VERSION ""

NS_ :

BS_:

BU_: OpticalSensor EMUS_BMS SCIMO_PE TelemetryNode Master SensorF SensorR BrakeF BrakeR PDU HVCU HVTU TestBench

BO_ 1482 HVCU_SDO_Req_Up: 8 TelemetryNode
 SG_ HVCU_OD_CAN2_DelayedTxMessages m1129 : 16|24@1+ (1,0) [0|16777215] ""  HVCU
 SG_ HVCU_OD_CAN2_ErrorStatus m1128 : 16|8@1+ (1,0) [0|255] ""  HVCU
 SG_ HVCU_OD_CAN2_DiscardedTxMessages m1127 : 16|24@1+ (1,0) [0|16777215] ""  HVCU
 SG_ HVCU_OD_CAN2_Status m1126 : 16|8@1+ (1,0) [0|255] ""  HVCU
 SG_ HVCU_OD_CAN2_Baudrate m1124 : 16|16@1+ (1,0) [125|1000] "kbps"  HVCU
 SG_ HVCU_OD_CAN2_autoErrorReset m1123 : 16|8@1+ (1,0) [0|255] ""  HVCU
 SG_ HVCU_OD_CAN2_lastErrorCode m1122 : 16|32@1+ (1,0) [0|4294967295] ""  HVCU
 SG_ HVCU_OD_CAN2_RxErrCnt m1121 : 16|8@1+ (1,0) [0|255] ""  HVCU
 SG_ HVCU_OD_CAN2_TxErrCnt m1120 : 16|8@1+ (1,0) [0|255] ""  HVCU
 SG_ HVCU_OD_CAN1_DelayedTxMessages m1113 : 16|24@1+ (1,0) [0|16777215] ""  HVCU
 SG_ HVCU_OD_CAN1_ErrorStatus m1112 : 16|8@1+ (1,0) [0|255] ""  HVCU
 SG_ HVCU_OD_CAN1_DiscardedTxMessages m1111 : 16|24@1+ (1,0) [0|16777215] ""  HVCU
 SG_ HVCU_OD_CAN1_Status m1110 : 16|8@1+ (1,0) [0|255] ""  HVCU
 SG_ HVCU_OD_CAN1_Baudrate m1108 : 16|16@1+ (1,0) [125|1000] "kbps"  HVCU
 SG_ HVCU_OD_CAN1_autoErrorReset m1107 : 16|8@1+ (1,0) [0|255] ""  HVCU
 SG_ HVCU_OD_CAN1_lastErrorCode m1106 : 16|32@1+ (1,0) [0|4294967295] ""  HVCU
 SG_ HVCU_OD_CAN1_RxErrCnt m1105 : 16|8@1+ (1,0) [0|255] ""  HVCU
 SG_ HVCU_OD_CAN1_TxErrCnt m1104 : 16|8@1+ (1,0) [0|255] ""  HVCU
 SG_ HVCU_OD_BuildTime m1073 : 16|24@1+ (1,0) [0|16777215] ""  HVCU
 SG_ HVCU_OD_BuildDate m1072 : 16|32@1+ (1,0) [0|4294967295] ""  HVCU
 SG_ HVCU_OD_ChipUID2 m1057 : 16|48@1+ (1,0) [0|281474976710655] ""  HVCU
 SG_ HVCU_OD_ChipUID1 m1056 : 16|48@1+ (1,0) [0|281474976710655] ""  HVCU
 SG_ HVCU_OD_SdcOut m1046 : 16|8@1+ (1,0) [0|255] ""  HVCU
 SG_ HVCU_OD_SdcIn m1045 : 16|8@1+ (1,0) [0|255] ""  HVCU
 SG_ HVCU_OD_runtime m1044 : 16|24@1+ (1,0) [0|16777215] "ms"  HVCU
 SG_ HVCU_OD_InputVoltage m1043 : 16|16@1+ (0.001,0) [0|65.535] "V"  HVCU
 SG_ HVCU_OD_BoardTemp m1042 : 16|16@1+ (0.01,-30) [-30|625.35] "°C"  HVCU
 SG_ HVCU_OD_MemFree m1041 : 16|16@1+ (4,0) [0|262140] "bytes"  HVCU
 SG_ HVCU_OD_CpuUsage m1040 : 16|8@1+ (0.5,0) [0|100] "%"  HVCU
 SG_ HVCU_OD_OdEntrySendInterval m33 : 16|16@1+ (1,0) [0|65535] "ms"  HVCU
 SG_ HVCU_OD_SendOdOnBootup m32 : 16|8@1+ (1,0) [0|255] ""  HVCU
 SG_ HVCU_OD_HeartbeatInterval m16 : 16|16@1+ (1,0) [0|65535] "ms"  HVCU
 SG_ HVCU_OD_DbcVersion m5 : 16|16@1+ (1,0) [0|65535] ""  HVCU
 SG_ HVCU_OD_StackVersion m4 : 16|16@1+ (1,0) [0|65535] ""  HVCU
 SG_ HVCU_OD_ProtocolVersion m3 : 16|16@1+ (1,0) [0|65535] ""  HVCU
 SG_ HVCU_OD_NodeStatus m2 : 16|8@1+ (1,0) [0|255] ""  HVCU
 SG_ HVCU_OD_NodeID m1 : 16|8@1+ (1,0) [0|255] ""  HVCU
 SG_ HVCU_SDO_ID M : 0|12@1+ (1,0) [0|4095] ""  HVCU

BO_ 1546 HVCU_SDO_Req_Down: 2 TelemetryNode
 SG_ HVCU_SDO_ID M : 0|12@1+ (1,0) [0|4095] ""  HVCU

BO_ 1802 HVCU_Heartbeat: 1 HVCU
 SG_ HVCU_NodeState : 0|8@1+ (1,0) [0|0] ""  SensorF,Master,TelemetryNode

BO_ 1866 HVCU_BTL_TX: 8 HVCU

BO_ 1930 HVCU_BTL_RX: 8 TelemetryNode

BO_ 153 HVTU_EMCY: 4 HVTU
 SG_ HVTU_E0_OtherError : 12|1@1+ (1,0) [0|0] ""  Master,TelemetryNode
 SG_ HVTU_W0_OtherWarning : 0|1@1+ (1,0) [0|0] ""  Master,TelemetryNode

BO_ 2684289024 EMUS_Internal_01: 8 EMUS_BMS

BO_ 2684289025 EMUS_Internal_02: 8 EMUS_BMS

BO_ 2684289026 EMUS_Internal_03: 8 EMUS_BMS

BO_ 2684289027 EMUS_Internal_04: 8 EMUS_BMS

BO_ 2684289028 EMUS_Internal_05: 8 EMUS_BMS

BO_ 2684289029 EMUS_Internal_06: 8 EMUS_BMS

BO_ 2684289030 EMUS_Internal_07: 8 EMUS_BMS

BO_ 2684289031 EMUS_Internal_08: 8 EMUS_BMS

BO_ 2684289032 EMUS_Internal_09: 8 EMUS_BMS

BO_ 2684289033 EMUS_Internal_10: 8 EMUS_BMS

BO_ 2684289034 EMUS_Internal_11: 8 EMUS_BMS

BO_ 2684289035 EMUS_Internal_12: 8 EMUS_BMS

BO_ 2684289036 EMUS_Internal_13: 8 EMUS_BMS

BO_ 2684289037 EMUS_Internal_14: 8 EMUS_BMS

BO_ 2684289038 EMUS_Internal_15: 8 EMUS_BMS

BO_ 2684289039 EMUS_Internal_16: 8 EMUS_BMS

BO_ 2684289040 EMUS_Internal_17: 8 EMUS_BMS

BO_ 2684289041 EMUS_Internal_18: 8 EMUS_BMS

BO_ 2684289042 EMUS_Internal_19: 8 EMUS_BMS

BO_ 2684289043 EMUS_Internal_20: 8 EMUS_BMS

BO_ 2684289044 EMUS_Internal_21: 8 EMUS_BMS

BO_ 2684289045 EMUS_Internal_22: 8 EMUS_BMS

BO_ 2684289046 EMUS_Internal_23: 8 EMUS_BMS

BO_ 2684289047 EMUS_Internal_24: 8 EMUS_BMS

BO_ 2684289048 EMUS_Internal_25: 8 EMUS_BMS

BO_ 2684289049 EMUS_Internal_26: 8 EMUS_BMS

BO_ 2684289050 EMUS_Internal_27: 8 EMUS_BMS

BO_ 2684289051 EMUS_Internal_28: 8 EMUS_BMS

BO_ 2684289052 EMUS_Internal_29: 8 EMUS_BMS

BO_ 2684289053 EMUS_Internal_30: 8 EMUS_BMS

BO_ 2684289054 EMUS_Internal_31: 8 EMUS_BMS

BO_ 2684289055 EMUS_Internal_32: 8 EMUS_BMS

BO_ 2684289056 EMUS_Internal_33: 8 EMUS_BMS

BO_ 2684289057 EMUS_Internal_34: 8 EMUS_BMS

BO_ 2684289058 EMUS_Internal_35: 8 EMUS_BMS

BO_ 2684289059 EMUS_Internal_36: 8 EMUS_BMS

BO_ 2684289060 EMUS_Internal_37: 8 EMUS_BMS

BO_ 2684289061 EMUS_Internal_38: 8 EMUS_BMS

BO_ 2684289062 EMUS_Internal_39: 8 EMUS_BMS

BO_ 2684289063 EMUS_Internal_40: 8 EMUS_BMS

BO_ 2684289064 EMUS_Internal_41: 8 EMUS_BMS

BO_ 2684289065 EMUS_Internal_42: 8 EMUS_BMS

BO_ 2684289066 EMUS_Internal_43: 8 EMUS_BMS

BO_ 2684289067 EMUS_Internal_44: 8 EMUS_BMS

BO_ 2684289068 EMUS_Internal_45: 8 EMUS_BMS

BO_ 2684289069 EMUS_Internal_46: 8 EMUS_BMS

BO_ 2684289070 EMUS_Internal_47: 8 EMUS_BMS

BO_ 2684289071 EMUS_Internal_48: 8 EMUS_BMS

BO_ 1509 SCIMO_PE_TX_Electric_MZ_V_FAST: 6 SCIMO_PE
 SG_ SCIMO_V_SET_W_MOT2 : 39|16@0- (0.02,0) [-655.36|655.34] "" Vector__XXX
 SG_ SCIMO_V_SET_V_MOT2 : 23|16@0- (0.02,0) [-655.36|655.34] "" Vector__XXX
 SG_ SCIMO_V_SET_U_MOT2 : 7|16@0- (0.02,0) [-655.36|655.34] "" Vector__XXX

BO_ 1508 SCIMO_PE_TX_Electric_MZ_I_FAST: 6 SCIMO_PE
 SG_ SCIMO_I_MES_W_MOT2 : 39|16@0- (0.02,0) [-655.36|655.34] "" Vector__XXX
 SG_ SCIMO_I_MES_V_MOT2 : 23|16@0- (0.02,0) [-655.36|655.34] "" Vector__XXX
 SG_ SCIMO_I_MES_U_MOT2 : 7|16@0- (0.02,0) [-655.36|655.34] "" Vector__XXX

BO_ 1488 SCIMO_PE_TX_AmbientTemp_MOT2: 8 SensorR
 SG_ SCIMO_Temp_ThermocoupleJ_MOT2 : 55|16@0- (0.005,150) [-13.84|313.835] ""  TestBench
 SG_ SCIMO_Temp_ThermocoupleK_MOT2 : 39|16@0- (0.005,150) [-13.84|313.835] ""  TestBench
 SG_ SCIMO_Temp_ADS_Ambient_MOT2 : 23|16@0- (0.005,150) [-13.84|313.835] ""  TestBench
 SG_ SCIMO_Temp_RotorAmbient_MOT2 : 7|16@0- (0.005,150) [-13.84|313.835] ""  TestBench

BO_ 1472 SCIMO_PE_TX_AmbientTemp_MOT1: 8 SensorR
 SG_ SCIMO_Temp_ThermocoupleJ_MOT1 : 55|16@0- (0.005,150) [-13.84|313.835] ""  TestBench
 SG_ SCIMO_Temp_ThermocoupleK_MOT1 : 39|16@0- (0.005,150) [-13.84|313.835] ""  TestBench
 SG_ SCIMO_Temp_ADS_Ambient_MOT1 : 23|16@0- (0.005,150) [-13.84|313.835] ""  TestBench
 SG_ SCIMO_Temp_RotorAmbient_MOT1 : 7|16@0- (0.005,150) [-13.84|313.835] ""  TestBench

BO_ 1456 SCIMO_MS_RX_RequestData: 2 SensorR
 SG_ SCIMO_NumOfSamples : 7|16@0+ (1,0) [0|65535] ""  TestBench

BO_ 1440 SCIMO_MS_TX_Electric: 8 SCIMO_PE
 SG_ SCIMO_U_Q_MOT : 55|16@0- (0.025,0) [-819.2|819.175] ""  TestBench
 SG_ SCIMO_U_D_MOT : 39|16@0- (0.025,0) [-819.2|819.175] ""  TestBench
 SG_ SCIMO_I_Q_MOT : 23|16@0- (0.025,0) [-819.2|819.175] ""  TestBench
 SG_ SCIMO_I_D_MOT : 7|16@0- (0.025,0) [-819.2|819.175] ""  TestBench

BO_ 1344 SCIMO_PE_TX_MotorTemp_MOT2: 6 SensorR
 SG_ SCIMO_Temp_PT100B_MOT2 : 39|16@0- (0.005,150) [-13.84|313.835] ""  TestBench
 SG_ SCIMO_Temp_PT100A_MOT2 : 23|16@0- (0.005,150) [-13.84|313.835] ""  TestBench
 SG_ SCIMO_Temp_Rotor_MOT2 : 7|16@0- (0.005,150) [-13.84|313.835] ""  TestBench

BO_ 1328 SCIMO_PE_TX_MotorTemp_MOT1: 6 SensorR
 SG_ SCIMO_Temp_PT100B_MOT1 : 39|16@0- (0.005,150) [-13.84|313.835] ""  TestBench
 SG_ SCIMO_Temp_PT100A_MOT1 : 23|16@0- (0.005,150) [-13.84|313.835] ""  TestBench
 SG_ SCIMO_Temp_Rotor_MOT1 : 7|16@0- (0.005,150) [-13.84|313.835] ""  TestBench

BO_ 1520 SCIMO_PE_TX_Status: 6 SCIMO_PE
 SG_ SCIMO_tempCPU : 47|8@0+ (0.5,0) [0|127.5] ""  TestBench,SensorR
 SG_ SCIMO_VCC_LV : 39|8@0+ (0.25,6) [6|69.75] ""  TestBench,SensorR
 SG_ SCIMO_I_LV : 31|8@0+ (0.01,0) [0|2.55] ""  TestBench,SensorR
 SG_ SCIMO_tempAUX2 : 23|8@0+ (1,0) [0|255] ""  TestBench,SensorR
 SG_ SCIMO_tempAUX1 : 15|8@0+ (1,0) [0|255] ""  TestBench,SensorR
 SG_ SCIMO_tempPCB : 7|8@0+ (1,0) [0|255] ""  TestBench,SensorR

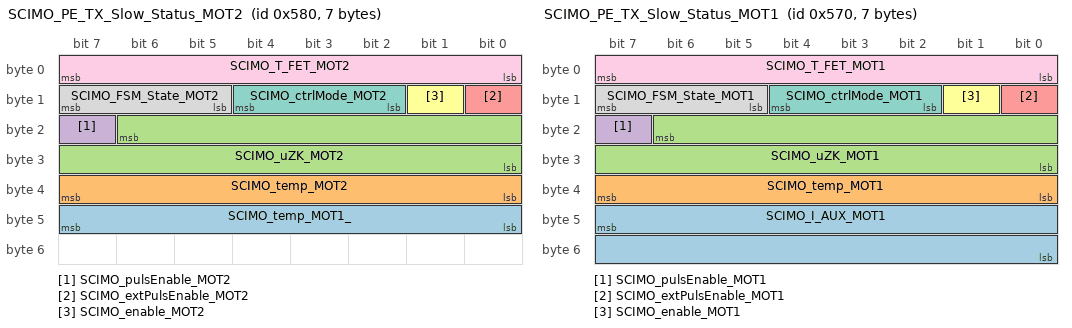
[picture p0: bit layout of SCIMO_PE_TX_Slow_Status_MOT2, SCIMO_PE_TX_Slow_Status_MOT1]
BO_ 1408 SCIMO_PE_TX_Slow_Status_MOT2: 7 SCIMO_PE
 SG_ SCIMO_temp_MOT1_ : 47|8@0+ (1,0) [0|0] ""  TestBench,SensorR
 SG_ SCIMO_temp_MOT2 : 39|8@0+ (1,0) [0|0] ""  TestBench,SensorR
 SG_ SCIMO_uZK_MOT2 : 22|15@0- (0.1,0) [0|0] ""  TestBench,SensorR
 SG_ SCIMO_pulsEnable_MOT2 : 23|1@0+ (1,0) [0|0] ""  TestBench,SensorR
 SG_ SCIMO_extPulsEnable_MOT2 : 8|1@0+ (1,0) [0|0] ""  TestBench,SensorR
 SG_ SCIMO_enable_MOT2 : 9|1@0+ (1,0) [0|0] ""  TestBench,SensorR
 SG_ SCIMO_ctrlMode_MOT2 : 12|3@0+ (1,0) [0|0] ""  TestBench,SensorR
 SG_ SCIMO_FSM_State_MOT2 : 15|3@0+ (1,0) [0|0] ""  TestBench,SensorR
 SG_ SCIMO_T_FET_MOT2 : 7|8@0+ (1,0) [0|0] ""  TestBench,SensorR

BO_ 1392 SCIMO_PE_TX_Slow_Status_MOT1: 7 SCIMO_PE
 SG_ SCIMO_I_AUX_MOT1 : 47|16@0- (1,0) [-32768|32767] ""  TestBench
 SG_ SCIMO_temp_MOT1 : 39|8@0+ (1,0) [0|0] ""  TestBench,SensorR
 SG_ SCIMO_uZK_MOT1 : 22|15@0- (0.1,0) [0|0] ""  TestBench,SensorR
 SG_ SCIMO_pulsEnable_MOT1 : 23|1@0+ (1,0) [0|0] ""  TestBench,SensorR
 SG_ SCIMO_extPulsEnable_MOT1 : 8|1@0+ (1,0) [0|0] ""  TestBench,SensorR
 SG_ SCIMO_enable_MOT1 : 9|1@0+ (1,0) [0|0] ""  TestBench,SensorR
 SG_ SCIMO_ctrlMode_MOT1 : 12|3@0+ (1,0) [0|0] ""  TestBench,SensorR
 SG_ SCIMO_FSM_State_MOT1 : 15|3@0+ (1,0) [0|0] ""  TestBench,SensorR
 SG_ SCIMO_T_FET_MOT1 : 7|8@0+ (1,0) [0|0] ""  TestBench,SensorR

BO_ 1504 SCIMO_PE_TX_Electric: 8 SCIMO_PE
 SG_ I_Q_MOT2 : 55|16@0- (1,0) [0|0] ""  TestBench,SensorR
 SG_ I_D_MOT2 : 39|16@0- (1,0) [0|0] ""  TestBench,SensorR
 SG_ I_Q_MOT1 : 23|16@0- (1,0) [0|0] ""  TestBench,SensorR
 SG_ I_D_MOT1 : 7|16@0- (1,0) [0|0] ""  TestBench,SensorR

BO_ 1510 SCIMO_PE_TX_MZ_Electric: 8 SCIMO_PE
 SG_ SCIMO_I_Q_MOT2 : 55|16@0- (0.05,0) [-1638.4|1638.35] ""  TestBench,SensorR
 SG_ SCIMO_I_D_MOT2 : 39|16@0- (0.05,0) [-1638.4|1638.35] ""  TestBench,SensorR
 SG_ SCIMO_f_REQ_LOWPASS_MOT2 : 23|13@0+ (0.05,0) [0|409.55] ""  TestBench,SensorR
 SG_ SCIMO_I_REQ_LOWPASS_MOT2 : 7|13@0+ (0.05,0) [0|409.55] ""  TestBench,SensorR

BO_ 1312 SCIMO_PE_TX_Errors: 5 SCIMO_PE
 SG_ SCIMO_warnNum_MOT2 : 25|10@0+ (1,0) [0|0] ""  TestBench,SensorR
 SG_ SCIMO_warnNum_MOT1 : 19|10@0+ (1,0) [0|1023] ""  TestBench,SensorR
 SG_ SCIMO_errNum_MOT2 : 15|8@0+ (1,0) [0|0] ""  TestBench,SensorR
 SG_ SCIMO_errNum_MOT1 : 7|8@0+ (1,0) [0|0] ""  TestBench,SensorR

BO_ 1360 SCIMO_PE_TX_Mech_fast: 8 SCIMO_PE
 SG_ SCIMO_M_ist_gw_MOT2 : 55|16@0- (1,0) [0|0] ""  TestBench,SensorR
 SG_ SCIMO_n_gw_MOT2 : 39|16@0- (1,0) [0|0] ""  TestBench,SensorR
 SG_ SCIMO_M_ist_gw_MOT1 : 23|16@0- (1,0) [0|0] ""  TestBench,SensorR
 SG_ SCIMO_n_gw_MOT1 : 7|16@0- (1,0) [0|0] ""  TestBench,SensorR

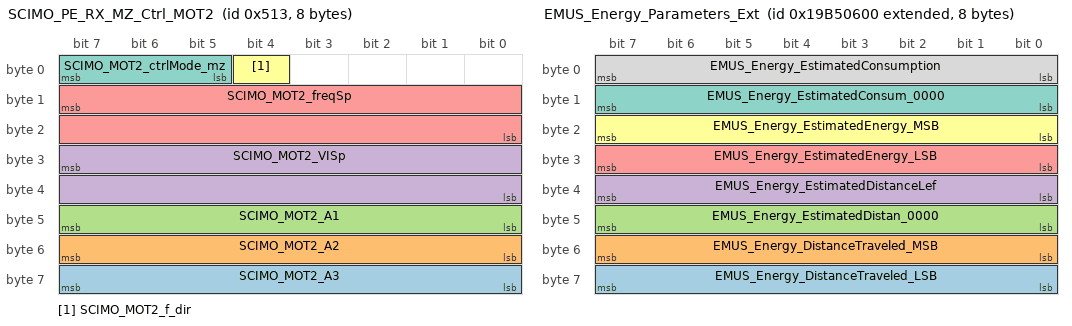
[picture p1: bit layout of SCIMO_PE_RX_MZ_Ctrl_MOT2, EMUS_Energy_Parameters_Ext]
BO_ 1299 SCIMO_PE_RX_MZ_Ctrl_MOT2: 8 SensorR
 SG_ SCIMO_MOT2_A3 : 56|8@1+ (0.01,0) [0|2.55] ""  SCIMO_PE
 SG_ SCIMO_MOT2_A2 : 48|8@1+ (0.01,0) [0|2.55] ""  SCIMO_PE
 SG_ SCIMO_MOT2_A1 : 40|8@1+ (0.01,0) [0|2.55] ""  SCIMO_PE
 SG_ SCIMO_MOT2_VISp : 31|16@0+ (0.01,0) [0|655.35] ""  TestBench,SCIMO_PE
 SG_ SCIMO_MOT2_freqSp : 15|16@0+ (0.02,0) [0|1310.7] ""  TestBench,SCIMO_PE
 SG_ SCIMO_MOT2_f_dir : 4|1@0+ (1,0) [0|0] ""  SCIMO_PE
 SG_ SCIMO_MOT2_ctrlMode_mz : 7|3@0+ (1,0) [0|0] ""  TestBench,SCIMO_PE

BO_ 1280 SCIMO_PE_RX_Ctrl_MOT1: 5 SensorR
 SG_ SCIMO_MOT1_limitSp : 31|16@0- (1,0) [0|0] ""  TestBench,SCIMO_PE
 SG_ SCIMO_MOT1_targetSp : 15|16@0- (1,0) [0|0] ""  TestBench,SCIMO_PE
 SG_ SCIMO_MOT1_reset : 3|1@0+ (1,0) [0|0] ""  TestBench,SCIMO_PE
 SG_ SCIMO_MOT1_ctrlMode : 6|3@0+ (1,0) [0|0] ""  TestBench,SCIMO_PE
 SG_ SCIMO_MOT1_enable : 7|1@0+ (1,0) [0|0] ""  TestBench,SCIMO_PE

BO_ 1296 SCIMO_PE_RX_Ctrl_MOT2: 5 SensorR
 SG_ SCIMO_MOT2_limitSp : 31|16@0- (1,0) [0|0] ""  TestBench,SCIMO_PE
 SG_ SCIMO_MOT2_targetSp : 15|16@0- (1,0) [0|0] ""  TestBench,SCIMO_PE
 SG_ SCIMO_MOT2_reset : 3|1@0+ (1,0) [0|0] ""  TestBench,SCIMO_PE
 SG_ SCIMO_MOT2_ctrlMode : 6|3@0+ (1,0) [0|0] ""  TestBench,SCIMO_PE
 SG_ SCIMO_MOT2_enable : 7|1@0+ (1,0) [0|0] ""  TestBench,SCIMO_PE

BO_ 2578776065 EMUS_Battery_Volt_Overall_Param_: 8 EMUS_BMS
 SG_ EMUS_VoltOverallParams_TVoltThir : 48|8@1+ (1,0) [0|255] ""  HVCU,HVTU
 SG_ EMUS_VoltOverallParams_TVoltMSB : 40|8@1+ (1,0) [0|255] ""  HVCU,HVTU
 SG_ EMUS_VoltOverallParams_TVoltLSB : 32|8@1+ (1,0) [0|255] ""  HVCU,HVTU
 SG_ EMUS_VoltOverallParams_TVoltSecB : 24|8@1+ (1,0) [0|255] ""  HVCU,HVTU
 SG_ EMUS_VoltOverallParam_AvrgCellVo : 16|8@1+ (0.01,2) [2|4.55] "V"  HVCU,HVTU
 SG_ EMUS_VoltOverallParam_MaxCellVol : 8|8@1+ (0.01,2) [2|4.55] "V"  HVCU,HVTU
 SG_ EMUS_VoltOverallParam_MinCellVol : 0|8@1+ (0.01,2) [2|4.55] "V"  HVCU,HVTU

BO_ 2578776064 EMUS_Overall_Parameters_Ext: 8 EMUS_BMS
 SG_ EMUS_OverallParams_NumberOf_0000 : 56|8@1+ (1,0) [0|255] ""  HVCU
 SG_ EMUS_OverallParams_LastChargingE : 48|8@1+ (1,0) [0|255] ""  HVCU
 SG_ EMUS_OverallParams_ChrgStag_0000 : 40|8@1+ (1,0) [0|255] ""  HVCU
 SG_ EMUS_OverallParams_ChrgStageDura : 32|8@1+ (1,0) [0|255] ""  HVCU
 SG_ EMUS_OverallParams_ChargingStage : 24|8@1+ (1,0) [0|255] ""  HVCU
 SG_ EMUS_OverallParams_NumberOfCells : 16|8@1+ (1,0) [0|255] ""  HVCU
 SG_ EMUS_OverallParams_ContactorPreC : 15|1@1+ (1,0) [0|1] ""  HVCU
 SG_ EMUS_OverallParams_DCDC_Control : 14|1@1+ (1,0) [0|1] ""  HVCU
 SG_ EMUS_OverallParams_ChargingInter : 13|1@1+ (1,0) [0|1] ""  HVCU
 SG_ EMUS_OverallParams_PowerReductio : 12|1@1+ (1,0) [0|1] ""  HVCU
 SG_ EMUS_OverallParams_BatteryFan : 11|1@1+ (1,0) [0|1] ""  HVCU
 SG_ EMUS_OverallParams_BatteryContac : 10|1@1+ (1,0) [0|1] ""  HVCU
 SG_ EMUS_OverallParams_HeaterEnable : 9|1@1+ (1,0) [0|1] ""  HVCU
 SG_ EMUS_OverallParams_ChargerEnable : 8|1@1+ (1,0) [0|1] ""  HVCU
 SG_ EMUS_OverallParams_LeakageSensor : 3|1@1+ (1,0) [0|1] ""  HVCU
 SG_ EMUS_OverallParams_FastCharge : 2|1@1+ (1,0) [0|1] ""  HVCU
 SG_ EMUS_OverallParams_ChargerMains : 1|1@1+ (1,0) [0|1] ""  HVCU
 SG_ EMUS_OverallParams_IgnitionKey : 0|1@1+ (1,0) [0|1] ""  HVCU

BO_ 2578776071 EMUS_Diagnostic_Codes_Ext: 8 EMUS_BMS
 SG_ EMUS_DiagnosticCodes_CellTempVal : 29|1@1+ (1,0) [0|1] ""  HVCU,HVTU
 SG_ EMUS_DiagnosticCodes_BatChrgFini : 28|1@1+ (1,0) [0|1] ""  HVCU,HVTU
 SG_ EMUS_DiagnosticCodes_NumOfCellsV : 27|1@1+ (1,0) [0|1] ""  HVCU,HVTU
 SG_ EMUS_DiagnosticCodes_CellBalancV : 26|1@1+ (1,0) [0|1] ""  HVCU,HVTU
 SG_ EMUS_DiagnosticCodes_CellModTemp : 25|1@1+ (1,0) [0|1] ""  HVCU,HVTU
 SG_ EMUS_DiagnosticCodes_CellVoltVal : 24|1@1+ (1,0) [0|1] ""  HVCU,HVTU
 SG_ EMUS_DiagnosticCodes_PackUnderVo : 21|1@1+ (1,0) [0|1] ""  HVCU,HVTU
 SG_ EMUS_DiagnosticCodes_NoCurrentSe : 20|1@1+ (1,0) [0|1] ""  HVCU,HVTU
 SG_ EMUS_DiagnosticCodes_CellOverHea : 19|1@1+ (1,0) [0|1] ""  HVCU,HVTU
 SG_ EMUS_DiagnosticCodes_HighTempera : 10|1@1+ (1,0) [0|1] ""  HVCU,HVTU
 SG_ EMUS_DiagnosticCodes_HighCurrent : 9|1@1+ (1,0) [0|1] ""  HVCU,HVTU
 SG_ EMUS_DiagnosticCodes_LowVoltage : 8|1@1+ (1,0) [0|1] ""  HVCU,HVTU
 SG_ EMUS_DiagnosticCodes_NoCellComm : 6|1@1+ (1,0) [0|1] ""  HVCU,HVTU
 SG_ EMUS_DiagnosticCodes_Leakage : 5|1@1+ (1,0) [0|1] ""  HVCU,HVTU
 SG_ EMUS_DiagnosticCodes_CellModOver : 4|1@1+ (1,0) [0|1] ""  HVCU,HVTU
 SG_ EMUS_DiagnosticCodes_ChrgOverCur : 3|1@1+ (1,0) [0|1] ""  HVCU,HVTU
 SG_ EMUS_DiagnosticCodes_DchrgOvrCur : 2|1@1+ (1,0) [0|1] ""  HVCU,HVTU
 SG_ EMUS_DiagnosticCodes_OverVoltage : 1|1@1+ (1,0) [0|1] ""  HVCU,HVTU
 SG_ EMUS_DiagnosticCodes_UnderVoltag : 0|1@1+ (1,0) [0|1] ""  HVCU,HVTU

BO_ 2578776066 EMUS_Cell_Mod_Temp_Overall_Param: 8 EMUS_BMS
 SG_ EMUS_CellModOverallPar_AvgCellMo : 16|8@1+ (1,-100) [-100|155] "Â°C"  HVTU
 SG_ EMUS_CellModOverallPar_MaxCellMo : 8|8@1+ (1,-100) [-100|155] "Â°C"  HVTU
 SG_ EMUS_CellModOverallPar_MinCellMo : 0|8@1+ (1,-100) [-100|155] "Â°C"  HVTU

BO_ 2578776072 EMUS_Cell_Temp_Overall_Params_Ex: 8 EMUS_BMS
 SG_ EMUS_CellOverallPar_AvgCellTemp : 16|8@1+ (1,-100) [-100|155] "Â°C"  HVTU
 SG_ EMUS_CellOverallPar_MaxCellTemp : 8|8@1+ (1,-100) [-100|155] "Â°C"  HVTU
 SG_ EMUS_CellOverallPar_MinCellTemp : 0|8@1+ (1,-100) [-100|155] "Â°C"  HVTU

BO_ 2578776067 EMUS_Cell_Balanc_Rate_Overall_Pa: 8 EMUS_BMS
 SG_ EMUS_CellBalancPar_AvgCellBalanc : 16|8@1+ (0.392156862745098,0) [0|100] "%"  HVTU
 SG_ EMUS_CellBalancPar_MaxCellBalanc : 8|8@1+ (0.392156862745098,0) [0|100] "%"  HVTU
 SG_ EMUS_CellBalancPar_MinCellBalanc : 0|8@1+ (0.392156862745098,0) [0|100] "%"  HVTU

BO_ 2578777088 EMUS_Configuration_Parameters_Ex: 8 EMUS_BMS
 SG_ EMUS_ConfigParams_Parameter_0000 : 48|8@1+ (1,0) [0|255] "" Vector__XXX
 SG_ EMUS_ConfigParams_ParamData_SecB : 40|8@1+ (1,0) [0|255] "" Vector__XXX
 SG_ EMUS_ConfigParams_ParamData_Thir : 32|8@1+ (1,0) [0|255] "" Vector__XXX
 SG_ EMUS_ConfigParams_ParameterData_ : 24|8@1+ (1,0) [0|255] "" Vector__XXX
 SG_ EMUS_ConfigParams_ParameterSize : 16|8@1+ (1,0) [0|255] "" Vector__XXX
 SG_ EMUS_ConfigParams_ParameterID_LS : 8|8@1+ (1,0) [0|255] "" Vector__XXX
 SG_ EMUS_ConfigParams_ParameterID_MS : 0|8@1+ (1,0) [0|255] "" Vector__XXX

BO_ 2578777090 EMUS_Login_Level_Ext: 8 EMUS_BMS
 SG_ EMUS_LoginLevel : 0|8@1+ (1,0) [0|255] "" Vector__XXX

BO_ 2578777089 EMUS_Contactor_Control_Ext: 1 HVCU
 SG_ EMUS_ContactorControl_ContactorS : 0|8@1+ (1,0) [0|255] ""  HVTU,EMUS_BMS

BO_ 2578777600 EMUS_Energy_Parameters_Ext: 8 EMUS_BMS
 SG_ EMUS_Energy_DistanceTraveled_LSB : 56|8@1+ (1,0) [0|255] "" Vector__XXX
 SG_ EMUS_Energy_DistanceTraveled_MSB : 48|8@1+ (1,0) [0|255] "" Vector__XXX
 SG_ EMUS_Energy_EstimatedDistan_0000 : 40|8@1+ (1,0) [0|255] "" Vector__XXX
 SG_ EMUS_Energy_EstimatedDistanceLef : 32|8@1+ (1,0) [0|255] "" Vector__XXX
 SG_ EMUS_Energy_EstimatedEnergy_LSB : 24|8@1+ (1,0) [0|255] "" Vector__XXX
 SG_ EMUS_Energy_EstimatedEnergy_MSB : 16|8@1+ (1,0) [0|255] "" Vector__XXX
 SG_ EMUS_Energy_EstimatedConsum_0000 : 8|8@1+ (1,0) [0|255] "" Vector__XXX
 SG_ EMUS_Energy_EstimatedConsumption : 0|8@1+ (1,0) [0|255] "" Vector__XXX

BO_ 2578777344 EMUS_State_Of_Charge_Param_Ext: 8 EMUS_BMS
 SG_ EMUS_SOCParams_EstimatedSOC : 48|8@1+ (1,0) [0|255] ""  HVTU
 SG_ EMUS_SOCParams_EstimatedCharge_L : 24|8@1+ (1,0) [0|255] ""  HVTU
 SG_ EMUS_SOCParams_EstimatedCharge_M : 16|8@1+ (1,0) [0|255] ""  HVTU
 SG_ EMUS_SOCParams_Current_LSB : 8|8@1+ (1,0) [0|255] ""  HVTU
 SG_ EMUS_SOCParams_Current_MSB : 0|8@1+ (1,0) [0|255] ""  HVTU

BO_ 2578777092 EMUS_Statistics_Ext: 8 EMUS_BMS
 SG_ EMUS_Statistics_Data_LSB : 40|8@1+ (1,0) [0|255] "" Vector__XXX
 SG_ EMUS_Statistics_Data_SecondByte : 32|8@1+ (1,0) [0|255] "" Vector__XXX
 SG_ EMUS_Statistics_Data_ThirdByte : 24|8@1+ (1,0) [0|255] "" Vector__XXX
 SG_ EMUS_Statistics_Data_MSB : 16|8@1+ (1,0) [0|255] "" Vector__XXX
 SG_ EMUS_Statistics_DataType : 8|8@1+ (1,0) [0|255] "" Vector__XXX
 SG_ EMUS_Statistics_Identifier : 0|8@1+ (1,0) [0|255] "" Vector__XXX

BO_ 2578777093 EMUS_Events_Ext: 8 EMUS_BMS
 SG_ EMUS_Events_Data_LSB : 40|8@1+ (1,0) [0|255] "" Vector__XXX
 SG_ EMUS_Events_Data_SecondByte : 32|8@1+ (1,0) [0|255] "" Vector__XXX
 SG_ EMUS_Events_Data_ThirdByte : 24|8@1+ (1,0) [0|255] "" Vector__XXX
 SG_ EMUS_Events_Data_MSB : 16|8@1+ (1,0) [0|255] "" Vector__XXX
 SG_ EMUS_Events_DataType : 8|8@1+ (1,0) [0|255] "" Vector__XXX
 SG_ EMUS_Events_EntryNumber : 0|8@1+ (1,0) [0|255] "" Vector__XXX

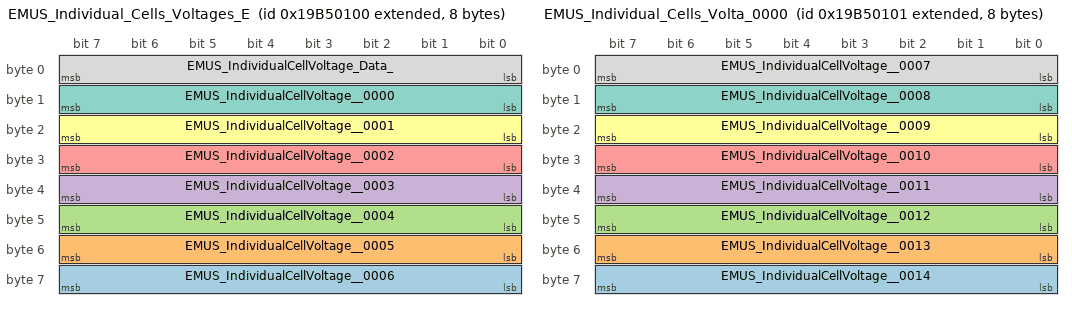
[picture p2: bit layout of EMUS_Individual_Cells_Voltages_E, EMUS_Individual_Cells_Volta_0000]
BO_ 2578776320 EMUS_Individual_Cells_Voltages_E: 8 EMUS_BMS
 SG_ EMUS_IndividualCellVoltage__0006 : 56|8@1+ (0.01,2) [2|4.55] "V" Vector__XXX
 SG_ EMUS_IndividualCellVoltage__0005 : 48|8@1+ (0.01,2) [2|4.55] "V" Vector__XXX
 SG_ EMUS_IndividualCellVoltage__0004 : 40|8@1+ (0.01,2) [2|4.55] "V" Vector__XXX
 SG_ EMUS_IndividualCellVoltage__0003 : 32|8@1+ (0.01,2) [2|4.55] "V" Vector__XXX
 SG_ EMUS_IndividualCellVoltage__0002 : 24|8@1+ (0.01,2) [2|4.55] "V" Vector__XXX
 SG_ EMUS_IndividualCellVoltage__0001 : 16|8@1+ (0.01,2) [2|4.55] "V" Vector__XXX
 SG_ EMUS_IndividualCellVoltage__0000 : 8|8@1+ (0.01,2) [2|4.55] "V" Vector__XXX
 SG_ EMUS_IndividualCellVoltage_Data_ : 0|8@1+ (0.01,2) [2|4.55] "V" Vector__XXX

BO_ 2578776321 EMUS_Individual_Cells_Volta_0000: 8 EMUS_BMS
 SG_ EMUS_IndividualCellVoltage__0014 : 56|8@1+ (0.01,2) [2|4.55] "V" Vector__XXX
 SG_ EMUS_IndividualCellVoltage__0013 : 48|8@1+ (0.01,2) [2|4.55] "V" Vector__XXX
 SG_ EMUS_IndividualCellVoltage__0012 : 40|8@1+ (0.01,2) [2|4.55] "V" Vector__XXX
 SG_ EMUS_IndividualCellVoltage__0011 : 32|8@1+ (0.01,2) [2|4.55] "V" Vector__XXX
 SG_ EMUS_IndividualCellVoltage__0010 : 24|8@1+ (0.01,2) [2|4.55] "V" Vector__XXX
 SG_ EMUS_IndividualCellVoltage__0009 : 16|8@1+ (0.01,2) [2|4.55] "V" Vector__XXX
 SG_ EMUS_IndividualCellVoltage__0008 : 8|8@1+ (0.01,2) [2|4.55] "V" Vector__XXX
 SG_ EMUS_IndividualCellVoltage__0007 : 0|8@1+ (0.01,2) [2|4.55] "V" Vector__XXX

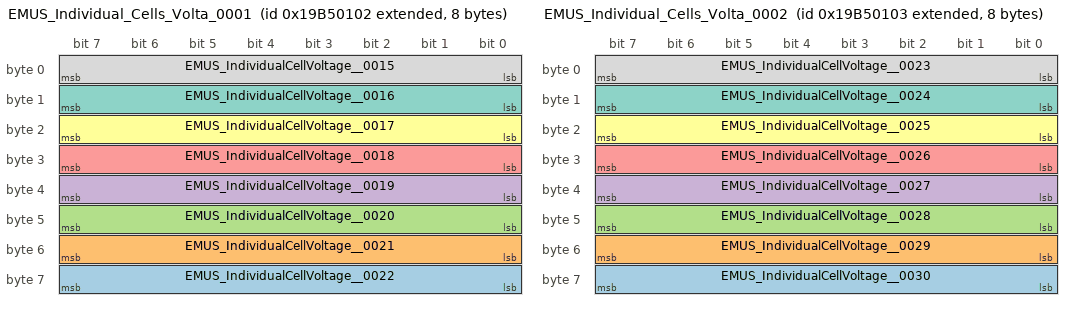
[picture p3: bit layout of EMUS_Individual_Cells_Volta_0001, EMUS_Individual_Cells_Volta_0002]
BO_ 2578776322 EMUS_Individual_Cells_Volta_0001: 8 EMUS_BMS
 SG_ EMUS_IndividualCellVoltage__0022 : 56|8@1+ (0.01,2) [2|4.55] "V" Vector__XXX
 SG_ EMUS_IndividualCellVoltage__0021 : 48|8@1+ (0.01,2) [2|4.55] "V" Vector__XXX
 SG_ EMUS_IndividualCellVoltage__0020 : 40|8@1+ (0.01,2) [2|4.55] "V" Vector__XXX
 SG_ EMUS_IndividualCellVoltage__0019 : 32|8@1+ (0.01,2) [2|4.55] "V" Vector__XXX
 SG_ EMUS_IndividualCellVoltage__0018 : 24|8@1+ (0.01,2) [2|4.55] "V" Vector__XXX
 SG_ EMUS_IndividualCellVoltage__0017 : 16|8@1+ (0.01,2) [2|4.55] "V" Vector__XXX
 SG_ EMUS_IndividualCellVoltage__0016 : 8|8@1+ (0.01,2) [2|4.55] "V" Vector__XXX
 SG_ EMUS_IndividualCellVoltage__0015 : 0|8@1+ (0.01,2) [2|4.55] "V" Vector__XXX

BO_ 2578776323 EMUS_Individual_Cells_Volta_0002: 8 EMUS_BMS
 SG_ EMUS_IndividualCellVoltage__0030 : 56|8@1+ (0.01,2) [2|4.55] "V" Vector__XXX
 SG_ EMUS_IndividualCellVoltage__0029 : 48|8@1+ (0.01,2) [2|4.55] "V" Vector__XXX
 SG_ EMUS_IndividualCellVoltage__0028 : 40|8@1+ (0.01,2) [2|4.55] "V" Vector__XXX
 SG_ EMUS_IndividualCellVoltage__0027 : 32|8@1+ (0.01,2) [2|4.55] "V" Vector__XXX
 SG_ EMUS_IndividualCellVoltage__0026 : 24|8@1+ (0.01,2) [2|4.55] "V" Vector__XXX
 SG_ EMUS_IndividualCellVoltage__0025 : 16|8@1+ (0.01,2) [2|4.55] "V" Vector__XXX
 SG_ EMUS_IndividualCellVoltage__0024 : 8|8@1+ (0.01,2) [2|4.55] "V" Vector__XXX
 SG_ EMUS_IndividualCellVoltage__0023 : 0|8@1+ (0.01,2) [2|4.55] "V" Vector__XXX

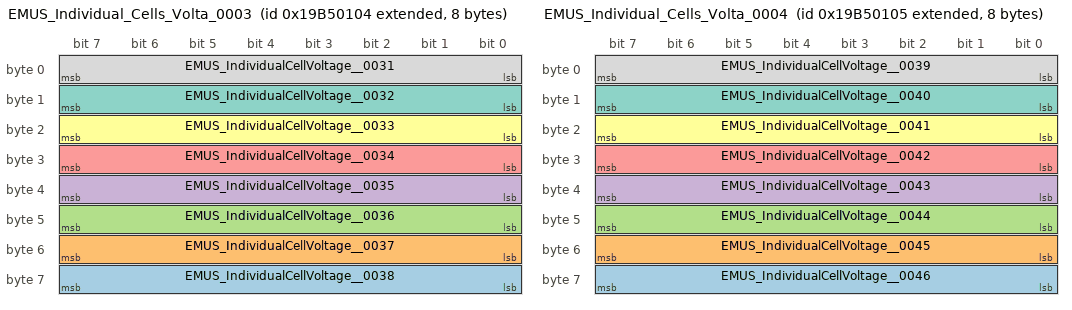
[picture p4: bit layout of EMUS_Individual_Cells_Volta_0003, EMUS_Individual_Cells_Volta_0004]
BO_ 2578776324 EMUS_Individual_Cells_Volta_0003: 8 EMUS_BMS
 SG_ EMUS_IndividualCellVoltage__0038 : 56|8@1+ (0.01,2) [2|4.55] "V" Vector__XXX
 SG_ EMUS_IndividualCellVoltage__0037 : 48|8@1+ (0.01,2) [2|4.55] "V" Vector__XXX
 SG_ EMUS_IndividualCellVoltage__0036 : 40|8@1+ (0.01,2) [2|4.55] "V" Vector__XXX
 SG_ EMUS_IndividualCellVoltage__0035 : 32|8@1+ (0.01,2) [2|4.55] "V" Vector__XXX
 SG_ EMUS_IndividualCellVoltage__0034 : 24|8@1+ (0.01,2) [2|4.55] "V" Vector__XXX
 SG_ EMUS_IndividualCellVoltage__0033 : 16|8@1+ (0.01,2) [2|4.55] "V" Vector__XXX
 SG_ EMUS_IndividualCellVoltage__0032 : 8|8@1+ (0.01,2) [2|4.55] "V" Vector__XXX
 SG_ EMUS_IndividualCellVoltage__0031 : 0|8@1+ (0.01,2) [2|4.55] "V" Vector__XXX

BO_ 2578776325 EMUS_Individual_Cells_Volta_0004: 8 EMUS_BMS
 SG_ EMUS_IndividualCellVoltage__0046 : 56|8@1+ (0.01,2) [2|4.55] "V" Vector__XXX
 SG_ EMUS_IndividualCellVoltage__0045 : 48|8@1+ (0.01,2) [2|4.55] "V" Vector__XXX
 SG_ EMUS_IndividualCellVoltage__0044 : 40|8@1+ (0.01,2) [2|4.55] "V" Vector__XXX
 SG_ EMUS_IndividualCellVoltage__0043 : 32|8@1+ (0.01,2) [2|4.55] "V" Vector__XXX
 SG_ EMUS_IndividualCellVoltage__0042 : 24|8@1+ (0.01,2) [2|4.55] "V" Vector__XXX
 SG_ EMUS_IndividualCellVoltage__0041 : 16|8@1+ (0.01,2) [2|4.55] "V" Vector__XXX
 SG_ EMUS_IndividualCellVoltage__0040 : 8|8@1+ (0.01,2) [2|4.55] "V" Vector__XXX
 SG_ EMUS_IndividualCellVoltage__0039 : 0|8@1+ (0.01,2) [2|4.55] "V" Vector__XXX

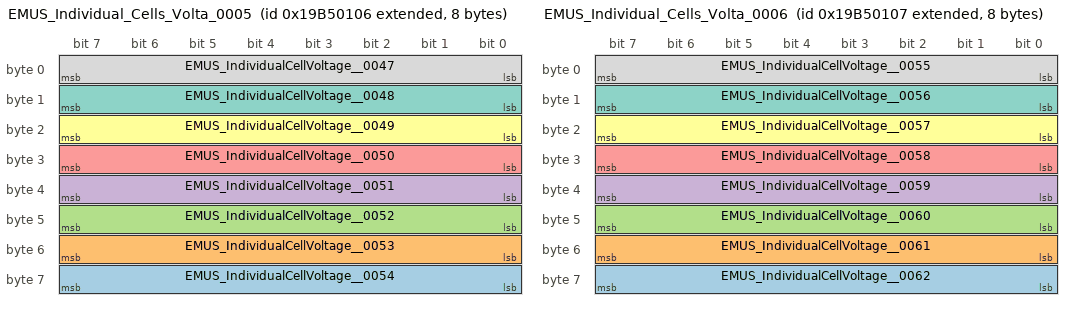
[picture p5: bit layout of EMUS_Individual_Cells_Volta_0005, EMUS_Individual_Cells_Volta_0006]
BO_ 2578776326 EMUS_Individual_Cells_Volta_0005: 8 EMUS_BMS
 SG_ EMUS_IndividualCellVoltage__0054 : 56|8@1+ (0.01,2) [2|4.55] "V" Vector__XXX
 SG_ EMUS_IndividualCellVoltage__0053 : 48|8@1+ (0.01,2) [2|4.55] "V" Vector__XXX
 SG_ EMUS_IndividualCellVoltage__0052 : 40|8@1+ (0.01,2) [2|4.55] "V" Vector__XXX
 SG_ EMUS_IndividualCellVoltage__0051 : 32|8@1+ (0.01,2) [2|4.55] "V" Vector__XXX
 SG_ EMUS_IndividualCellVoltage__0050 : 24|8@1+ (0.01,2) [2|4.55] "V" Vector__XXX
 SG_ EMUS_IndividualCellVoltage__0049 : 16|8@1+ (0.01,2) [2|4.55] "V" Vector__XXX
 SG_ EMUS_IndividualCellVoltage__0048 : 8|8@1+ (0.01,2) [2|4.55] "V" Vector__XXX
 SG_ EMUS_IndividualCellVoltage__0047 : 0|8@1+ (0.01,2) [2|4.55] "V" Vector__XXX

BO_ 2578776327 EMUS_Individual_Cells_Volta_0006: 8 EMUS_BMS
 SG_ EMUS_IndividualCellVoltage__0062 : 56|8@1+ (0.01,2) [2|4.55] "V" Vector__XXX
 SG_ EMUS_IndividualCellVoltage__0061 : 48|8@1+ (0.01,2) [2|4.55] "V" Vector__XXX
 SG_ EMUS_IndividualCellVoltage__0060 : 40|8@1+ (0.01,2) [2|4.55] "V" Vector__XXX
 SG_ EMUS_IndividualCellVoltage__0059 : 32|8@1+ (0.01,2) [2|4.55] "V" Vector__XXX
 SG_ EMUS_IndividualCellVoltage__0058 : 24|8@1+ (0.01,2) [2|4.55] "V" Vector__XXX
 SG_ EMUS_IndividualCellVoltage__0057 : 16|8@1+ (0.01,2) [2|4.55] "V" Vector__XXX
 SG_ EMUS_IndividualCellVoltage__0056 : 8|8@1+ (0.01,2) [2|4.55] "V" Vector__XXX
 SG_ EMUS_IndividualCellVoltage__0055 : 0|8@1+ (0.01,2) [2|4.55] "V" Vector__XXX

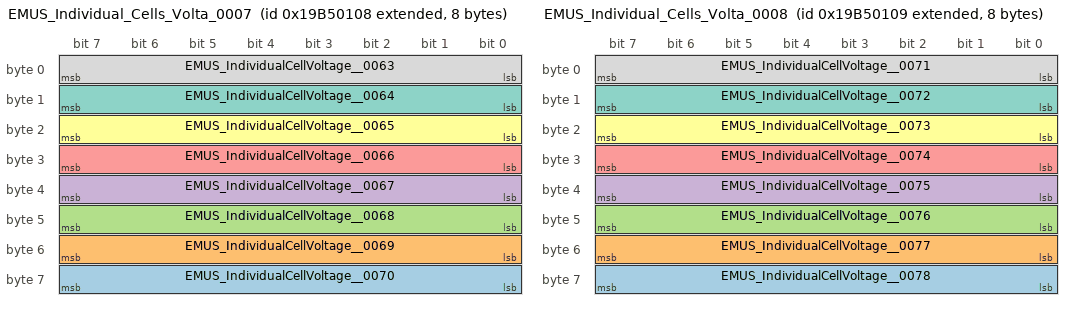
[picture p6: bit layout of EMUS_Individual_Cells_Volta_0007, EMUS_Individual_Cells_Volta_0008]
BO_ 2578776328 EMUS_Individual_Cells_Volta_0007: 8 EMUS_BMS
 SG_ EMUS_IndividualCellVoltage__0070 : 56|8@1+ (0.01,2) [2|4.55] "V" Vector__XXX
 SG_ EMUS_IndividualCellVoltage__0069 : 48|8@1+ (0.01,2) [2|4.55] "V" Vector__XXX
 SG_ EMUS_IndividualCellVoltage__0068 : 40|8@1+ (0.01,2) [2|4.55] "V" Vector__XXX
 SG_ EMUS_IndividualCellVoltage__0067 : 32|8@1+ (0.01,2) [2|4.55] "V" Vector__XXX
 SG_ EMUS_IndividualCellVoltage__0066 : 24|8@1+ (0.01,2) [2|4.55] "V" Vector__XXX
 SG_ EMUS_IndividualCellVoltage__0065 : 16|8@1+ (0.01,2) [2|4.55] "V" Vector__XXX
 SG_ EMUS_IndividualCellVoltage__0064 : 8|8@1+ (0.01,2) [2|4.55] "V" Vector__XXX
 SG_ EMUS_IndividualCellVoltage__0063 : 0|8@1+ (0.01,2) [2|4.55] "V" Vector__XXX

BO_ 2578776329 EMUS_Individual_Cells_Volta_0008: 8 EMUS_BMS
 SG_ EMUS_IndividualCellVoltage__0078 : 56|8@1+ (0.01,2) [2|4.55] "V" Vector__XXX
 SG_ EMUS_IndividualCellVoltage__0077 : 48|8@1+ (0.01,2) [2|4.55] "V" Vector__XXX
 SG_ EMUS_IndividualCellVoltage__0076 : 40|8@1+ (0.01,2) [2|4.55] "V" Vector__XXX
 SG_ EMUS_IndividualCellVoltage__0075 : 32|8@1+ (0.01,2) [2|4.55] "V" Vector__XXX
 SG_ EMUS_IndividualCellVoltage__0074 : 24|8@1+ (0.01,2) [2|4.55] "V" Vector__XXX
 SG_ EMUS_IndividualCellVoltage__0073 : 16|8@1+ (0.01,2) [2|4.55] "V" Vector__XXX
 SG_ EMUS_IndividualCellVoltage__0072 : 8|8@1+ (0.01,2) [2|4.55] "V" Vector__XXX
 SG_ EMUS_IndividualCellVoltage__0071 : 0|8@1+ (0.01,2) [2|4.55] "V" Vector__XXX

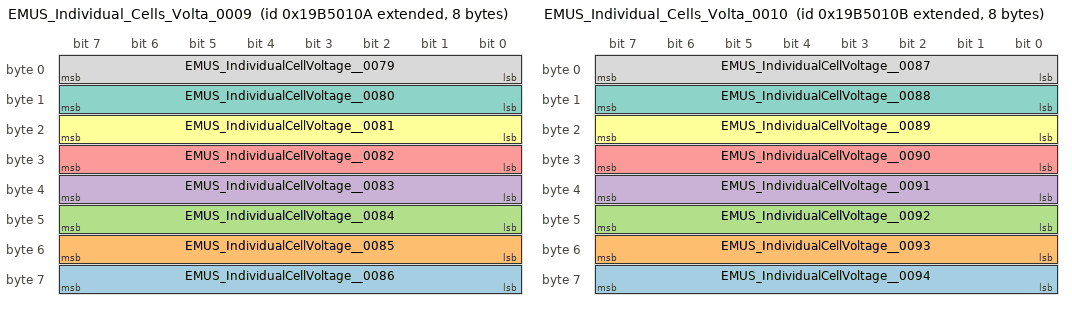
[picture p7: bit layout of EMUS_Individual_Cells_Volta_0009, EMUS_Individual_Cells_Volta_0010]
BO_ 2578776330 EMUS_Individual_Cells_Volta_0009: 8 EMUS_BMS
 SG_ EMUS_IndividualCellVoltage__0086 : 56|8@1+ (0.01,2) [2|4.55] "V" Vector__XXX
 SG_ EMUS_IndividualCellVoltage__0085 : 48|8@1+ (0.01,2) [2|4.55] "V" Vector__XXX
 SG_ EMUS_IndividualCellVoltage__0084 : 40|8@1+ (0.01,2) [2|4.55] "V" Vector__XXX
 SG_ EMUS_IndividualCellVoltage__0083 : 32|8@1+ (0.01,2) [2|4.55] "V" Vector__XXX
 SG_ EMUS_IndividualCellVoltage__0082 : 24|8@1+ (0.01,2) [2|4.55] "V" Vector__XXX
 SG_ EMUS_IndividualCellVoltage__0081 : 16|8@1+ (0.01,2) [2|4.55] "V" Vector__XXX
 SG_ EMUS_IndividualCellVoltage__0080 : 8|8@1+ (0.01,2) [2|4.55] "V" Vector__XXX
 SG_ EMUS_IndividualCellVoltage__0079 : 0|8@1+ (0.01,2) [2|4.55] "V" Vector__XXX

BO_ 2578776331 EMUS_Individual_Cells_Volta_0010: 8 EMUS_BMS
 SG_ EMUS_IndividualCellVoltage__0094 : 56|8@1+ (0.01,2) [2|4.55] "V" Vector__XXX
 SG_ EMUS_IndividualCellVoltage__0093 : 48|8@1+ (0.01,2) [2|4.55] "V" Vector__XXX
 SG_ EMUS_IndividualCellVoltage__0092 : 40|8@1+ (0.01,2) [2|4.55] "V" Vector__XXX
 SG_ EMUS_IndividualCellVoltage__0091 : 32|8@1+ (0.01,2) [2|4.55] "V" Vector__XXX
 SG_ EMUS_IndividualCellVoltage__0090 : 24|8@1+ (0.01,2) [2|4.55] "V" Vector__XXX
 SG_ EMUS_IndividualCellVoltage__0089 : 16|8@1+ (0.01,2) [2|4.55] "V" Vector__XXX
 SG_ EMUS_IndividualCellVoltage__0088 : 8|8@1+ (0.01,2) [2|4.55] "V" Vector__XXX
 SG_ EMUS_IndividualCellVoltage__0087 : 0|8@1+ (0.01,2) [2|4.55] "V" Vector__XXX

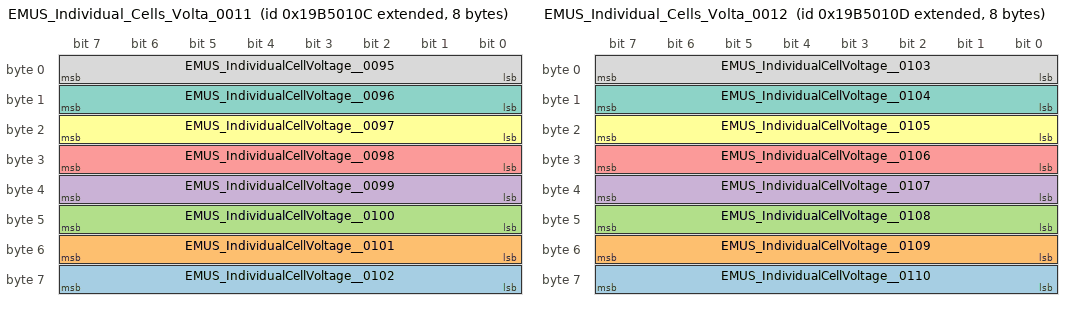
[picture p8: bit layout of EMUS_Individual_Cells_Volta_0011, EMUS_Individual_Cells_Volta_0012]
BO_ 2578776332 EMUS_Individual_Cells_Volta_0011: 8 EMUS_BMS
 SG_ EMUS_IndividualCellVoltage__0102 : 56|8@1+ (0.01,2) [2|4.55] "V" Vector__XXX
 SG_ EMUS_IndividualCellVoltage__0101 : 48|8@1+ (0.01,2) [2|4.55] "V" Vector__XXX
 SG_ EMUS_IndividualCellVoltage__0100 : 40|8@1+ (0.01,2) [2|4.55] "V" Vector__XXX
 SG_ EMUS_IndividualCellVoltage__0099 : 32|8@1+ (0.01,2) [2|4.55] "V" Vector__XXX
 SG_ EMUS_IndividualCellVoltage__0098 : 24|8@1+ (0.01,2) [2|4.55] "V" Vector__XXX
 SG_ EMUS_IndividualCellVoltage__0097 : 16|8@1+ (0.01,2) [2|4.55] "V" Vector__XXX
 SG_ EMUS_IndividualCellVoltage__0096 : 8|8@1+ (0.01,2) [2|4.55] "V" Vector__XXX
 SG_ EMUS_IndividualCellVoltage__0095 : 0|8@1+ (0.01,2) [2|4.55] "V" Vector__XXX

BO_ 2578776333 EMUS_Individual_Cells_Volta_0012: 8 EMUS_BMS
 SG_ EMUS_IndividualCellVoltage__0110 : 56|8@1+ (0.01,2) [2|4.55] "V" Vector__XXX
 SG_ EMUS_IndividualCellVoltage__0109 : 48|8@1+ (0.01,2) [2|4.55] "V" Vector__XXX
 SG_ EMUS_IndividualCellVoltage__0108 : 40|8@1+ (0.01,2) [2|4.55] "V" Vector__XXX
 SG_ EMUS_IndividualCellVoltage__0107 : 32|8@1+ (0.01,2) [2|4.55] "V" Vector__XXX
 SG_ EMUS_IndividualCellVoltage__0106 : 24|8@1+ (0.01,2) [2|4.55] "V" Vector__XXX
 SG_ EMUS_IndividualCellVoltage__0105 : 16|8@1+ (0.01,2) [2|4.55] "V" Vector__XXX
 SG_ EMUS_IndividualCellVoltage__0104 : 8|8@1+ (0.01,2) [2|4.55] "V" Vector__XXX
 SG_ EMUS_IndividualCellVoltage__0103 : 0|8@1+ (0.01,2) [2|4.55] "V" Vector__XXX

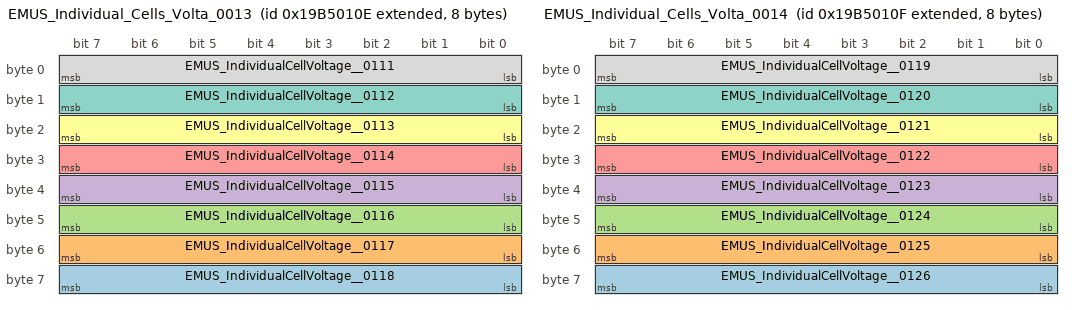
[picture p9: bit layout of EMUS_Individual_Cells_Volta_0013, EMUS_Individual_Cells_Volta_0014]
BO_ 2578776334 EMUS_Individual_Cells_Volta_0013: 8 EMUS_BMS
 SG_ EMUS_IndividualCellVoltage__0118 : 56|8@1+ (0.01,2) [2|4.55] "V" Vector__XXX
 SG_ EMUS_IndividualCellVoltage__0117 : 48|8@1+ (0.01,2) [2|4.55] "V" Vector__XXX
 SG_ EMUS_IndividualCellVoltage__0116 : 40|8@1+ (0.01,2) [2|4.55] "V" Vector__XXX
 SG_ EMUS_IndividualCellVoltage__0115 : 32|8@1+ (0.01,2) [2|4.55] "V" Vector__XXX
 SG_ EMUS_IndividualCellVoltage__0114 : 24|8@1+ (0.01,2) [2|4.55] "V" Vector__XXX
 SG_ EMUS_IndividualCellVoltage__0113 : 16|8@1+ (0.01,2) [2|4.55] "V" Vector__XXX
 SG_ EMUS_IndividualCellVoltage__0112 : 8|8@1+ (0.01,2) [2|4.55] "V" Vector__XXX
 SG_ EMUS_IndividualCellVoltage__0111 : 0|8@1+ (0.01,2) [2|4.55] "V" Vector__XXX

BO_ 2578776335 EMUS_Individual_Cells_Volta_0014: 8 EMUS_BMS
 SG_ EMUS_IndividualCellVoltage__0126 : 56|8@1+ (0.01,2) [2|4.55] "V" Vector__XXX
 SG_ EMUS_IndividualCellVoltage__0125 : 48|8@1+ (0.01,2) [2|4.55] "V" Vector__XXX
 SG_ EMUS_IndividualCellVoltage__0124 : 40|8@1+ (0.01,2) [2|4.55] "V" Vector__XXX
 SG_ EMUS_IndividualCellVoltage__0123 : 32|8@1+ (0.01,2) [2|4.55] "V" Vector__XXX
 SG_ EMUS_IndividualCellVoltage__0122 : 24|8@1+ (0.01,2) [2|4.55] "V" Vector__XXX
 SG_ EMUS_IndividualCellVoltage__0121 : 16|8@1+ (0.01,2) [2|4.55] "V" Vector__XXX
 SG_ EMUS_IndividualCellVoltage__0120 : 8|8@1+ (0.01,2) [2|4.55] "V" Vector__XXX
 SG_ EMUS_IndividualCellVoltage__0119 : 0|8@1+ (0.01,2) [2|4.55] "V" Vector__XXX

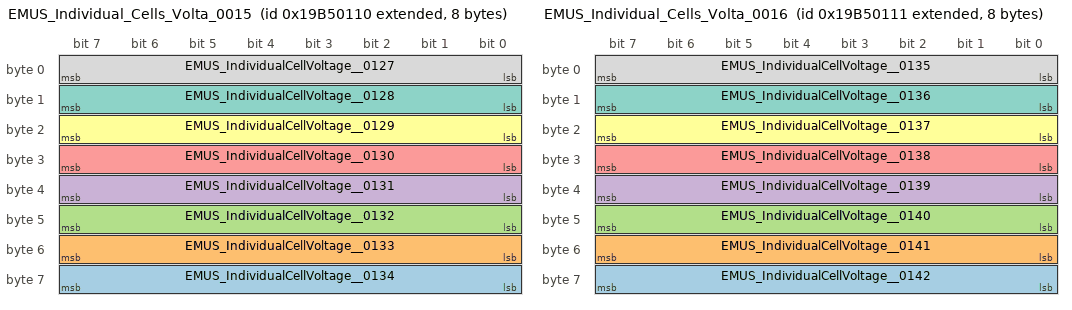
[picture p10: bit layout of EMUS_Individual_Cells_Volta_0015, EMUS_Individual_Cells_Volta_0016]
BO_ 2578776336 EMUS_Individual_Cells_Volta_0015: 8 EMUS_BMS
 SG_ EMUS_IndividualCellVoltage__0134 : 56|8@1+ (0.01,2) [2|4.55] "V" Vector__XXX
 SG_ EMUS_IndividualCellVoltage__0133 : 48|8@1+ (0.01,2) [2|4.55] "V" Vector__XXX
 SG_ EMUS_IndividualCellVoltage__0132 : 40|8@1+ (0.01,2) [2|4.55] "V" Vector__XXX
 SG_ EMUS_IndividualCellVoltage__0131 : 32|8@1+ (0.01,2) [2|4.55] "V" Vector__XXX
 SG_ EMUS_IndividualCellVoltage__0130 : 24|8@1+ (0.01,2) [2|4.55] "V" Vector__XXX
 SG_ EMUS_IndividualCellVoltage__0129 : 16|8@1+ (0.01,2) [2|4.55] "V" Vector__XXX
 SG_ EMUS_IndividualCellVoltage__0128 : 8|8@1+ (0.01,2) [2|4.55] "V" Vector__XXX
 SG_ EMUS_IndividualCellVoltage__0127 : 0|8@1+ (0.01,2) [2|4.55] "V" Vector__XXX

BO_ 2578776337 EMUS_Individual_Cells_Volta_0016: 8 EMUS_BMS
 SG_ EMUS_IndividualCellVoltage__0142 : 56|8@1+ (0.01,2) [2|4.55] "V" Vector__XXX
 SG_ EMUS_IndividualCellVoltage__0141 : 48|8@1+ (0.01,2) [2|4.55] "V" Vector__XXX
 SG_ EMUS_IndividualCellVoltage__0140 : 40|8@1+ (0.01,2) [2|4.55] "V" Vector__XXX
 SG_ EMUS_IndividualCellVoltage__0139 : 32|8@1+ (0.01,2) [2|4.55] "V" Vector__XXX
 SG_ EMUS_IndividualCellVoltage__0138 : 24|8@1+ (0.01,2) [2|4.55] "V" Vector__XXX
 SG_ EMUS_IndividualCellVoltage__0137 : 16|8@1+ (0.01,2) [2|4.55] "V" Vector__XXX
 SG_ EMUS_IndividualCellVoltage__0136 : 8|8@1+ (0.01,2) [2|4.55] "V" Vector__XXX
 SG_ EMUS_IndividualCellVoltage__0135 : 0|8@1+ (0.01,2) [2|4.55] "V" Vector__XXX

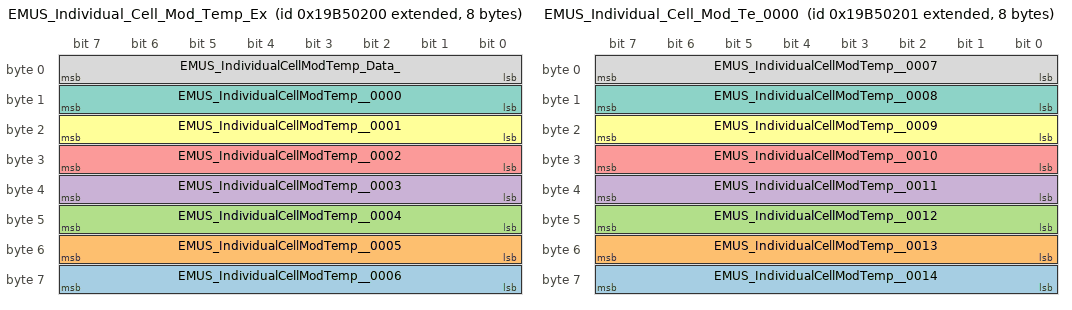
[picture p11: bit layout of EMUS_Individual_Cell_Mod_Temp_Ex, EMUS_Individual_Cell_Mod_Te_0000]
BO_ 2578776576 EMUS_Individual_Cell_Mod_Temp_Ex: 8 EMUS_BMS
 SG_ EMUS_IndividualCellModTemp__0006 : 56|8@1+ (1,-100) [-100|155] "%" Vector__XXX
 SG_ EMUS_IndividualCellModTemp__0005 : 48|8@1+ (1,-100) [-100|155] "%" Vector__XXX
 SG_ EMUS_IndividualCellModTemp__0004 : 40|8@1+ (1,-100) [-100|155] "%" Vector__XXX
 SG_ EMUS_IndividualCellModTemp__0003 : 32|8@1+ (1,-100) [-100|155] "%" Vector__XXX
 SG_ EMUS_IndividualCellModTemp__0002 : 24|8@1+ (1,-100) [-100|155] "%" Vector__XXX
 SG_ EMUS_IndividualCellModTemp__0001 : 16|8@1+ (1,-100) [-100|155] "%" Vector__XXX
 SG_ EMUS_IndividualCellModTemp__0000 : 8|8@1+ (1,-100) [-100|155] "%" Vector__XXX
 SG_ EMUS_IndividualCellModTemp_Data_ : 0|8@1+ (1,-100) [-100|155] "%" Vector__XXX

BO_ 2578776577 EMUS_Individual_Cell_Mod_Te_0000: 8 EMUS_BMS
 SG_ EMUS_IndividualCellModTemp__0014 : 56|8@1+ (1,-100) [-100|155] "%" Vector__XXX
 SG_ EMUS_IndividualCellModTemp__0013 : 48|8@1+ (1,-100) [-100|155] "%" Vector__XXX
 SG_ EMUS_IndividualCellModTemp__0012 : 40|8@1+ (1,-100) [-100|155] "%" Vector__XXX
 SG_ EMUS_IndividualCellModTemp__0011 : 32|8@1+ (1,-100) [-100|155] "%" Vector__XXX
 SG_ EMUS_IndividualCellModTemp__0010 : 24|8@1+ (1,-100) [-100|155] "%" Vector__XXX
 SG_ EMUS_IndividualCellModTemp__0009 : 16|8@1+ (1,-100) [-100|155] "%" Vector__XXX
 SG_ EMUS_IndividualCellModTemp__0008 : 8|8@1+ (1,-100) [-100|155] "%" Vector__XXX
 SG_ EMUS_IndividualCellModTemp__0007 : 0|8@1+ (1,-100) [-100|155] "%" Vector__XXX

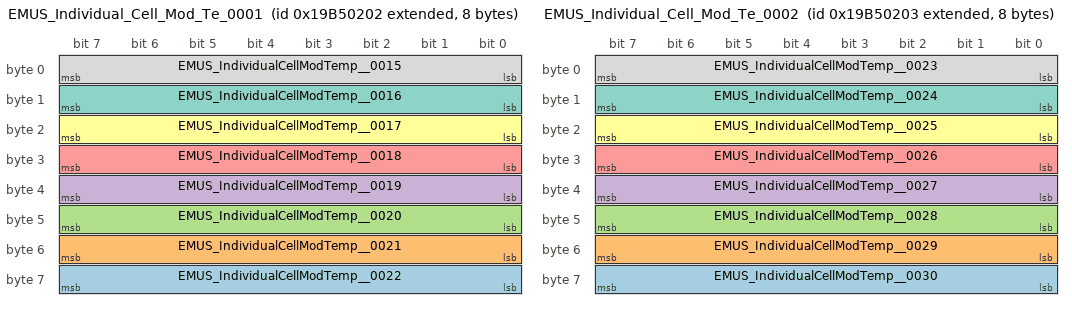
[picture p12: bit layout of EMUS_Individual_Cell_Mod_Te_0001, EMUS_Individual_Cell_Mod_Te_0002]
BO_ 2578776578 EMUS_Individual_Cell_Mod_Te_0001: 8 EMUS_BMS
 SG_ EMUS_IndividualCellModTemp__0022 : 56|8@1+ (1,-100) [-100|155] "%" Vector__XXX
 SG_ EMUS_IndividualCellModTemp__0021 : 48|8@1+ (1,-100) [-100|155] "%" Vector__XXX
 SG_ EMUS_IndividualCellModTemp__0020 : 40|8@1+ (1,-100) [-100|155] "%" Vector__XXX
 SG_ EMUS_IndividualCellModTemp__0019 : 32|8@1+ (1,-100) [-100|155] "%" Vector__XXX
 SG_ EMUS_IndividualCellModTemp__0018 : 24|8@1+ (1,-100) [-100|155] "%" Vector__XXX
 SG_ EMUS_IndividualCellModTemp__0017 : 16|8@1+ (1,-100) [-100|155] "%" Vector__XXX
 SG_ EMUS_IndividualCellModTemp__0016 : 8|8@1+ (1,-100) [-100|155] "%" Vector__XXX
 SG_ EMUS_IndividualCellModTemp__0015 : 0|8@1+ (1,-100) [-100|155] "%" Vector__XXX

BO_ 2578776579 EMUS_Individual_Cell_Mod_Te_0002: 8 EMUS_BMS
 SG_ EMUS_IndividualCellModTemp__0030 : 56|8@1+ (1,-100) [-100|155] "%" Vector__XXX
 SG_ EMUS_IndividualCellModTemp__0029 : 48|8@1+ (1,-100) [-100|155] "%" Vector__XXX
 SG_ EMUS_IndividualCellModTemp__0028 : 40|8@1+ (1,-100) [-100|155] "%" Vector__XXX
 SG_ EMUS_IndividualCellModTemp__0027 : 32|8@1+ (1,-100) [-100|155] "%" Vector__XXX
 SG_ EMUS_IndividualCellModTemp__0026 : 24|8@1+ (1,-100) [-100|155] "%" Vector__XXX
 SG_ EMUS_IndividualCellModTemp__0025 : 16|8@1+ (1,-100) [-100|155] "%" Vector__XXX
 SG_ EMUS_IndividualCellModTemp__0024 : 8|8@1+ (1,-100) [-100|155] "%" Vector__XXX
 SG_ EMUS_IndividualCellModTemp__0023 : 0|8@1+ (1,-100) [-100|155] "%" Vector__XXX

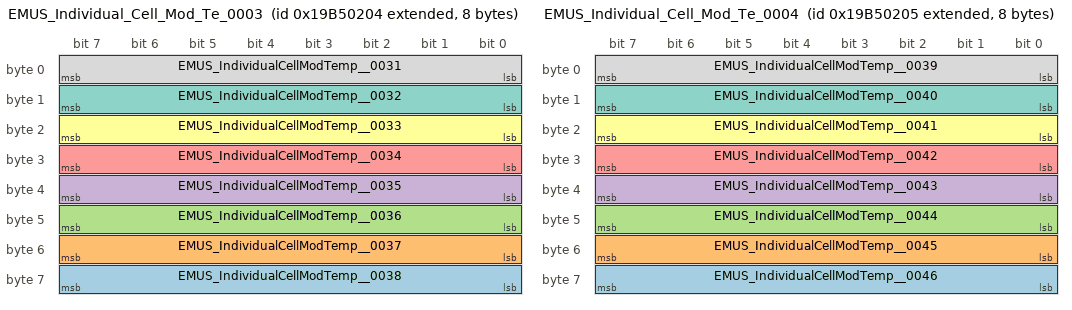
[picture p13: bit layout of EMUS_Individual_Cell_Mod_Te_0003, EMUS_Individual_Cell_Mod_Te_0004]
BO_ 2578776580 EMUS_Individual_Cell_Mod_Te_0003: 8 EMUS_BMS
 SG_ EMUS_IndividualCellModTemp__0038 : 56|8@1+ (1,-100) [-100|155] "%" Vector__XXX
 SG_ EMUS_IndividualCellModTemp__0037 : 48|8@1+ (1,-100) [-100|155] "%" Vector__XXX
 SG_ EMUS_IndividualCellModTemp__0036 : 40|8@1+ (1,-100) [-100|155] "%" Vector__XXX
 SG_ EMUS_IndividualCellModTemp__0035 : 32|8@1+ (1,-100) [-100|155] "%" Vector__XXX
 SG_ EMUS_IndividualCellModTemp__0034 : 24|8@1+ (1,-100) [-100|155] "%" Vector__XXX
 SG_ EMUS_IndividualCellModTemp__0033 : 16|8@1+ (1,-100) [-100|155] "%" Vector__XXX
 SG_ EMUS_IndividualCellModTemp__0032 : 8|8@1+ (1,-100) [-100|155] "%" Vector__XXX
 SG_ EMUS_IndividualCellModTemp__0031 : 0|8@1+ (1,-100) [-100|155] "%" Vector__XXX

BO_ 2578776581 EMUS_Individual_Cell_Mod_Te_0004: 8 EMUS_BMS
 SG_ EMUS_IndividualCellModTemp__0046 : 56|8@1+ (1,-100) [-100|155] "%" Vector__XXX
 SG_ EMUS_IndividualCellModTemp__0045 : 48|8@1+ (1,-100) [-100|155] "%" Vector__XXX
 SG_ EMUS_IndividualCellModTemp__0044 : 40|8@1+ (1,-100) [-100|155] "%" Vector__XXX
 SG_ EMUS_IndividualCellModTemp__0043 : 32|8@1+ (1,-100) [-100|155] "%" Vector__XXX
 SG_ EMUS_IndividualCellModTemp__0042 : 24|8@1+ (1,-100) [-100|155] "%" Vector__XXX
 SG_ EMUS_IndividualCellModTemp__0041 : 16|8@1+ (1,-100) [-100|155] "%" Vector__XXX
 SG_ EMUS_IndividualCellModTemp__0040 : 8|8@1+ (1,-100) [-100|155] "%" Vector__XXX
 SG_ EMUS_IndividualCellModTemp__0039 : 0|8@1+ (1,-100) [-100|155] "%" Vector__XXX

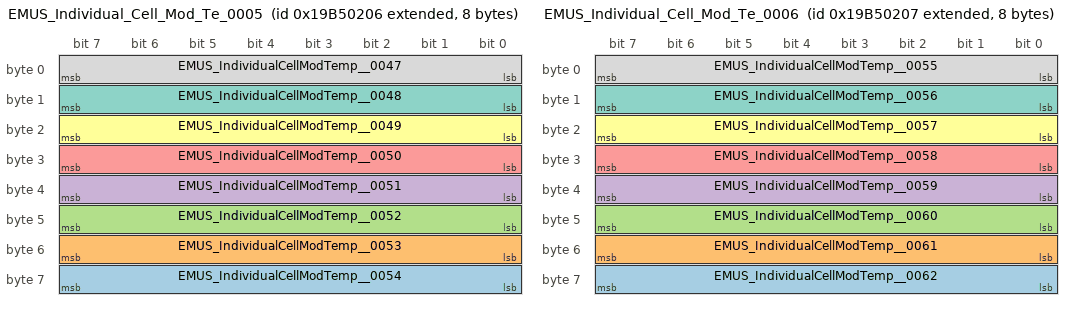
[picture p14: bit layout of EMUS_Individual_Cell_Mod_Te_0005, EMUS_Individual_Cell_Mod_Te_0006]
BO_ 2578776582 EMUS_Individual_Cell_Mod_Te_0005: 8 EMUS_BMS
 SG_ EMUS_IndividualCellModTemp__0054 : 56|8@1+ (1,-100) [-100|155] "%" Vector__XXX
 SG_ EMUS_IndividualCellModTemp__0053 : 48|8@1+ (1,-100) [-100|155] "%" Vector__XXX
 SG_ EMUS_IndividualCellModTemp__0052 : 40|8@1+ (1,-100) [-100|155] "%" Vector__XXX
 SG_ EMUS_IndividualCellModTemp__0051 : 32|8@1+ (1,-100) [-100|155] "%" Vector__XXX
 SG_ EMUS_IndividualCellModTemp__0050 : 24|8@1+ (1,-100) [-100|155] "%" Vector__XXX
 SG_ EMUS_IndividualCellModTemp__0049 : 16|8@1+ (1,-100) [-100|155] "%" Vector__XXX
 SG_ EMUS_IndividualCellModTemp__0048 : 8|8@1+ (1,-100) [-100|155] "%" Vector__XXX
 SG_ EMUS_IndividualCellModTemp__0047 : 0|8@1+ (1,-100) [-100|155] "%" Vector__XXX

BO_ 2578776583 EMUS_Individual_Cell_Mod_Te_0006: 8 EMUS_BMS
 SG_ EMUS_IndividualCellModTemp__0062 : 56|8@1+ (1,-100) [-100|155] "%" Vector__XXX
 SG_ EMUS_IndividualCellModTemp__0061 : 48|8@1+ (1,-100) [-100|155] "%" Vector__XXX
 SG_ EMUS_IndividualCellModTemp__0060 : 40|8@1+ (1,-100) [-100|155] "%" Vector__XXX
 SG_ EMUS_IndividualCellModTemp__0059 : 32|8@1+ (1,-100) [-100|155] "%" Vector__XXX
 SG_ EMUS_IndividualCellModTemp__0058 : 24|8@1+ (1,-100) [-100|155] "%" Vector__XXX
 SG_ EMUS_IndividualCellModTemp__0057 : 16|8@1+ (1,-100) [-100|155] "%" Vector__XXX
 SG_ EMUS_IndividualCellModTemp__0056 : 8|8@1+ (1,-100) [-100|155] "%" Vector__XXX
 SG_ EMUS_IndividualCellModTemp__0055 : 0|8@1+ (1,-100) [-100|155] "%" Vector__XXX

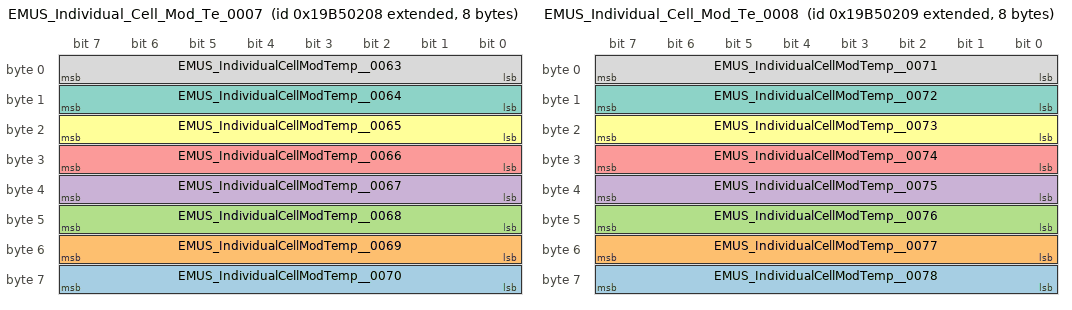
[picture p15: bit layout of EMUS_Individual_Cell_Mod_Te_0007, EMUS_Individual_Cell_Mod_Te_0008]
BO_ 2578776584 EMUS_Individual_Cell_Mod_Te_0007: 8 EMUS_BMS
 SG_ EMUS_IndividualCellModTemp__0070 : 56|8@1+ (1,-100) [-100|155] "%" Vector__XXX
 SG_ EMUS_IndividualCellModTemp__0069 : 48|8@1+ (1,-100) [-100|155] "%" Vector__XXX
 SG_ EMUS_IndividualCellModTemp__0068 : 40|8@1+ (1,-100) [-100|155] "%" Vector__XXX
 SG_ EMUS_IndividualCellModTemp__0067 : 32|8@1+ (1,-100) [-100|155] "%" Vector__XXX
 SG_ EMUS_IndividualCellModTemp__0066 : 24|8@1+ (1,-100) [-100|155] "%" Vector__XXX
 SG_ EMUS_IndividualCellModTemp__0065 : 16|8@1+ (1,-100) [-100|155] "%" Vector__XXX
 SG_ EMUS_IndividualCellModTemp__0064 : 8|8@1+ (1,-100) [-100|155] "%" Vector__XXX
 SG_ EMUS_IndividualCellModTemp__0063 : 0|8@1+ (1,-100) [-100|155] "%" Vector__XXX

BO_ 2578776585 EMUS_Individual_Cell_Mod_Te_0008: 8 EMUS_BMS
 SG_ EMUS_IndividualCellModTemp__0078 : 56|8@1+ (1,-100) [-100|155] "%" Vector__XXX
 SG_ EMUS_IndividualCellModTemp__0077 : 48|8@1+ (1,-100) [-100|155] "%" Vector__XXX
 SG_ EMUS_IndividualCellModTemp__0076 : 40|8@1+ (1,-100) [-100|155] "%" Vector__XXX
 SG_ EMUS_IndividualCellModTemp__0075 : 32|8@1+ (1,-100) [-100|155] "%" Vector__XXX
 SG_ EMUS_IndividualCellModTemp__0074 : 24|8@1+ (1,-100) [-100|155] "%" Vector__XXX
 SG_ EMUS_IndividualCellModTemp__0073 : 16|8@1+ (1,-100) [-100|155] "%" Vector__XXX
 SG_ EMUS_IndividualCellModTemp__0072 : 8|8@1+ (1,-100) [-100|155] "%" Vector__XXX
 SG_ EMUS_IndividualCellModTemp__0071 : 0|8@1+ (1,-100) [-100|155] "%" Vector__XXX

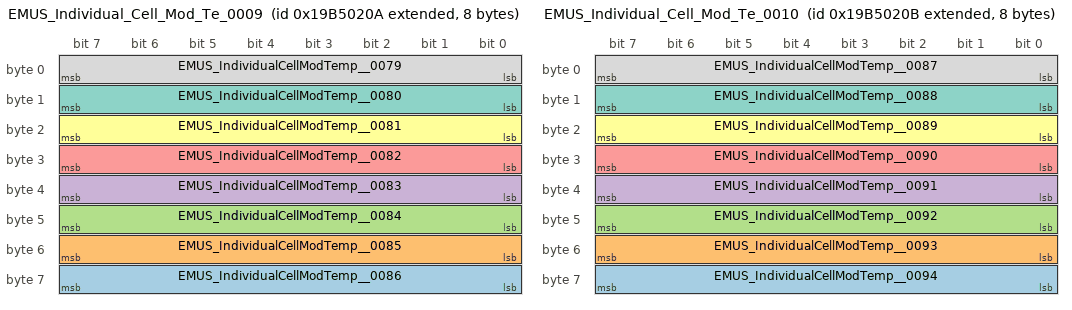
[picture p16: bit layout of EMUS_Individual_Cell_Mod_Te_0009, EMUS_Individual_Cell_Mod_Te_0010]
BO_ 2578776586 EMUS_Individual_Cell_Mod_Te_0009: 8 EMUS_BMS
 SG_ EMUS_IndividualCellModTemp__0086 : 56|8@1+ (1,-100) [-100|155] "%" Vector__XXX
 SG_ EMUS_IndividualCellModTemp__0085 : 48|8@1+ (1,-100) [-100|155] "%" Vector__XXX
 SG_ EMUS_IndividualCellModTemp__0084 : 40|8@1+ (1,-100) [-100|155] "%" Vector__XXX
 SG_ EMUS_IndividualCellModTemp__0083 : 32|8@1+ (1,-100) [-100|155] "%" Vector__XXX
 SG_ EMUS_IndividualCellModTemp__0082 : 24|8@1+ (1,-100) [-100|155] "%" Vector__XXX
 SG_ EMUS_IndividualCellModTemp__0081 : 16|8@1+ (1,-100) [-100|155] "%" Vector__XXX
 SG_ EMUS_IndividualCellModTemp__0080 : 8|8@1+ (1,-100) [-100|155] "%" Vector__XXX
 SG_ EMUS_IndividualCellModTemp__0079 : 0|8@1+ (1,-100) [-100|155] "%" Vector__XXX

BO_ 2578776587 EMUS_Individual_Cell_Mod_Te_0010: 8 EMUS_BMS
 SG_ EMUS_IndividualCellModTemp__0094 : 56|8@1+ (1,-100) [-100|155] "%" Vector__XXX
 SG_ EMUS_IndividualCellModTemp__0093 : 48|8@1+ (1,-100) [-100|155] "%" Vector__XXX
 SG_ EMUS_IndividualCellModTemp__0092 : 40|8@1+ (1,-100) [-100|155] "%" Vector__XXX
 SG_ EMUS_IndividualCellModTemp__0091 : 32|8@1+ (1,-100) [-100|155] "%" Vector__XXX
 SG_ EMUS_IndividualCellModTemp__0090 : 24|8@1+ (1,-100) [-100|155] "%" Vector__XXX
 SG_ EMUS_IndividualCellModTemp__0089 : 16|8@1+ (1,-100) [-100|155] "%" Vector__XXX
 SG_ EMUS_IndividualCellModTemp__0088 : 8|8@1+ (1,-100) [-100|155] "%" Vector__XXX
 SG_ EMUS_IndividualCellModTemp__0087 : 0|8@1+ (1,-100) [-100|155] "%" Vector__XXX

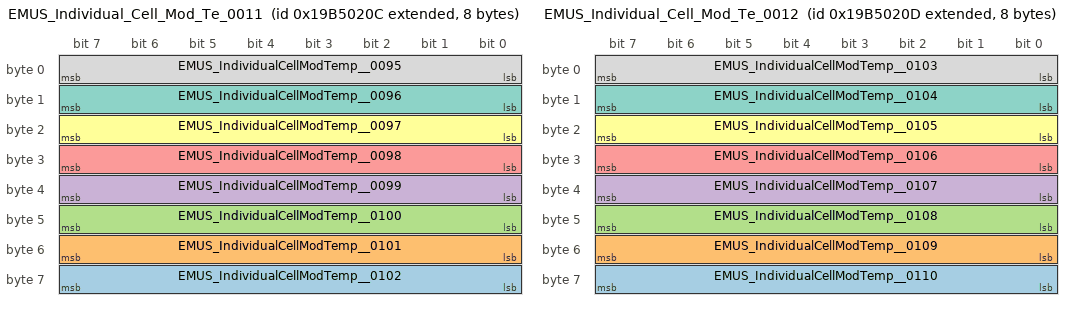
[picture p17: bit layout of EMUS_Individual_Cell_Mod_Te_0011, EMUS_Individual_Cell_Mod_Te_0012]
BO_ 2578776588 EMUS_Individual_Cell_Mod_Te_0011: 8 EMUS_BMS
 SG_ EMUS_IndividualCellModTemp__0102 : 56|8@1+ (1,-100) [-100|155] "%" Vector__XXX
 SG_ EMUS_IndividualCellModTemp__0101 : 48|8@1+ (1,-100) [-100|155] "%" Vector__XXX
 SG_ EMUS_IndividualCellModTemp__0100 : 40|8@1+ (1,-100) [-100|155] "%" Vector__XXX
 SG_ EMUS_IndividualCellModTemp__0099 : 32|8@1+ (1,-100) [-100|155] "%" Vector__XXX
 SG_ EMUS_IndividualCellModTemp__0098 : 24|8@1+ (1,-100) [-100|155] "%" Vector__XXX
 SG_ EMUS_IndividualCellModTemp__0097 : 16|8@1+ (1,-100) [-100|155] "%" Vector__XXX
 SG_ EMUS_IndividualCellModTemp__0096 : 8|8@1+ (1,-100) [-100|155] "%" Vector__XXX
 SG_ EMUS_IndividualCellModTemp__0095 : 0|8@1+ (1,-100) [-100|155] "%" Vector__XXX

BO_ 2578776589 EMUS_Individual_Cell_Mod_Te_0012: 8 EMUS_BMS
 SG_ EMUS_IndividualCellModTemp__0110 : 56|8@1+ (1,-100) [-100|155] "%" Vector__XXX
 SG_ EMUS_IndividualCellModTemp__0109 : 48|8@1+ (1,-100) [-100|155] "%" Vector__XXX
 SG_ EMUS_IndividualCellModTemp__0108 : 40|8@1+ (1,-100) [-100|155] "%" Vector__XXX
 SG_ EMUS_IndividualCellModTemp__0107 : 32|8@1+ (1,-100) [-100|155] "%" Vector__XXX
 SG_ EMUS_IndividualCellModTemp__0106 : 24|8@1+ (1,-100) [-100|155] "%" Vector__XXX
 SG_ EMUS_IndividualCellModTemp__0105 : 16|8@1+ (1,-100) [-100|155] "%" Vector__XXX
 SG_ EMUS_IndividualCellModTemp__0104 : 8|8@1+ (1,-100) [-100|155] "%" Vector__XXX
 SG_ EMUS_IndividualCellModTemp__0103 : 0|8@1+ (1,-100) [-100|155] "%" Vector__XXX

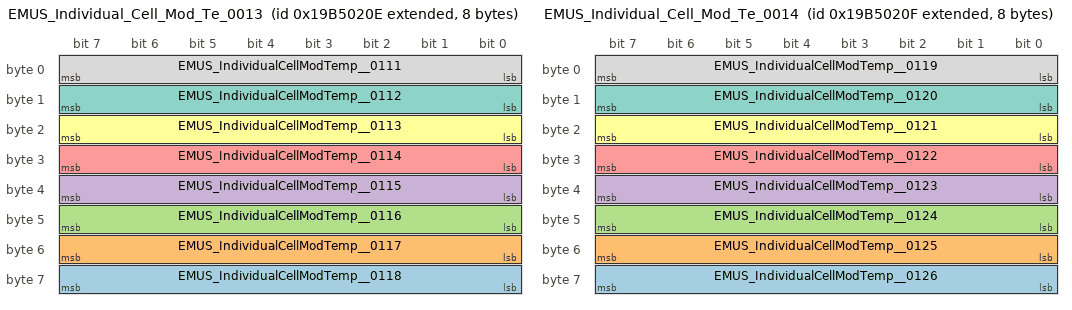
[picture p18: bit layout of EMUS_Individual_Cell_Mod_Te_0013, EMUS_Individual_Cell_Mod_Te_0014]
BO_ 2578776590 EMUS_Individual_Cell_Mod_Te_0013: 8 EMUS_BMS
 SG_ EMUS_IndividualCellModTemp__0118 : 56|8@1+ (1,-100) [-100|155] "%" Vector__XXX
 SG_ EMUS_IndividualCellModTemp__0117 : 48|8@1+ (1,-100) [-100|155] "%" Vector__XXX
 SG_ EMUS_IndividualCellModTemp__0116 : 40|8@1+ (1,-100) [-100|155] "%" Vector__XXX
 SG_ EMUS_IndividualCellModTemp__0115 : 32|8@1+ (1,-100) [-100|155] "%" Vector__XXX
 SG_ EMUS_IndividualCellModTemp__0114 : 24|8@1+ (1,-100) [-100|155] "%" Vector__XXX
 SG_ EMUS_IndividualCellModTemp__0113 : 16|8@1+ (1,-100) [-100|155] "%" Vector__XXX
 SG_ EMUS_IndividualCellModTemp__0112 : 8|8@1+ (1,-100) [-100|155] "%" Vector__XXX
 SG_ EMUS_IndividualCellModTemp__0111 : 0|8@1+ (1,-100) [-100|155] "%" Vector__XXX

BO_ 2578776591 EMUS_Individual_Cell_Mod_Te_0014: 8 EMUS_BMS
 SG_ EMUS_IndividualCellModTemp__0126 : 56|8@1+ (1,-100) [-100|155] "%" Vector__XXX
 SG_ EMUS_IndividualCellModTemp__0125 : 48|8@1+ (1,-100) [-100|155] "%" Vector__XXX
 SG_ EMUS_IndividualCellModTemp__0124 : 40|8@1+ (1,-100) [-100|155] "%" Vector__XXX
 SG_ EMUS_IndividualCellModTemp__0123 : 32|8@1+ (1,-100) [-100|155] "%" Vector__XXX
 SG_ EMUS_IndividualCellModTemp__0122 : 24|8@1+ (1,-100) [-100|155] "%" Vector__XXX
 SG_ EMUS_IndividualCellModTemp__0121 : 16|8@1+ (1,-100) [-100|155] "%" Vector__XXX
 SG_ EMUS_IndividualCellModTemp__0120 : 8|8@1+ (1,-100) [-100|155] "%" Vector__XXX
 SG_ EMUS_IndividualCellModTemp__0119 : 0|8@1+ (1,-100) [-100|155] "%" Vector__XXX

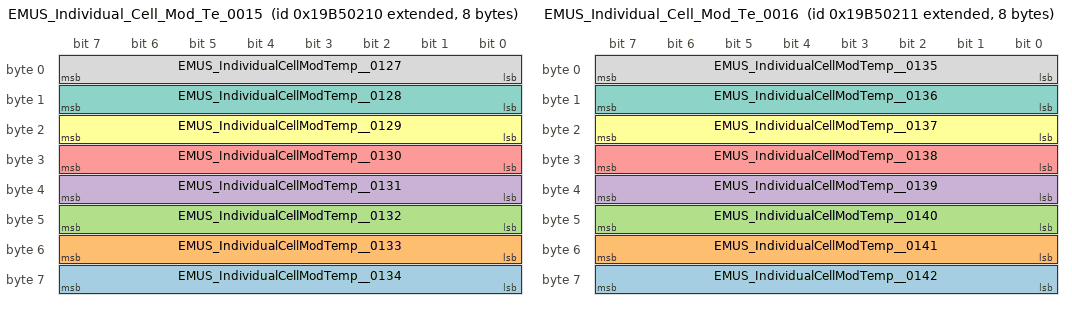
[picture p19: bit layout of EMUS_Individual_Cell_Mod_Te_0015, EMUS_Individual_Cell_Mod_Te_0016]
BO_ 2578776592 EMUS_Individual_Cell_Mod_Te_0015: 8 EMUS_BMS
 SG_ EMUS_IndividualCellModTemp__0134 : 56|8@1+ (1,-100) [-100|155] "%" Vector__XXX
 SG_ EMUS_IndividualCellModTemp__0133 : 48|8@1+ (1,-100) [-100|155] "%" Vector__XXX
 SG_ EMUS_IndividualCellModTemp__0132 : 40|8@1+ (1,-100) [-100|155] "%" Vector__XXX
 SG_ EMUS_IndividualCellModTemp__0131 : 32|8@1+ (1,-100) [-100|155] "%" Vector__XXX
 SG_ EMUS_IndividualCellModTemp__0130 : 24|8@1+ (1,-100) [-100|155] "%" Vector__XXX
 SG_ EMUS_IndividualCellModTemp__0129 : 16|8@1+ (1,-100) [-100|155] "%" Vector__XXX
 SG_ EMUS_IndividualCellModTemp__0128 : 8|8@1+ (1,-100) [-100|155] "%" Vector__XXX
 SG_ EMUS_IndividualCellModTemp__0127 : 0|8@1+ (1,-100) [-100|155] "%" Vector__XXX

BO_ 2578776593 EMUS_Individual_Cell_Mod_Te_0016: 8 EMUS_BMS
 SG_ EMUS_IndividualCellModTemp__0142 : 56|8@1+ (1,-100) [-100|155] "%" Vector__XXX
 SG_ EMUS_IndividualCellModTemp__0141 : 48|8@1+ (1,-100) [-100|155] "%" Vector__XXX
 SG_ EMUS_IndividualCellModTemp__0140 : 40|8@1+ (1,-100) [-100|155] "%" Vector__XXX
 SG_ EMUS_IndividualCellModTemp__0139 : 32|8@1+ (1,-100) [-100|155] "%" Vector__XXX
 SG_ EMUS_IndividualCellModTemp__0138 : 24|8@1+ (1,-100) [-100|155] "%" Vector__XXX
 SG_ EMUS_IndividualCellModTemp__0137 : 16|8@1+ (1,-100) [-100|155] "%" Vector__XXX
 SG_ EMUS_IndividualCellModTemp__0136 : 8|8@1+ (1,-100) [-100|155] "%" Vector__XXX
 SG_ EMUS_IndividualCellModTemp__0135 : 0|8@1+ (1,-100) [-100|155] "%" Vector__XXX

BO_ 2578778112 EMUS_Individual_Cell_Temp_Ext_A0: 8 EMUS_BMS
 SG_ EMUS_IndividualCellTemperat_0006 : 56|8@1+ (1,-100) [-100|155] "%" Vector__XXX
 SG_ EMUS_IndividualCellTemperat_0005 : 48|8@1+ (1,-100) [-100|155] "%" Vector__XXX
 SG_ EMUS_IndividualCellTemperat_0004 : 40|8@1+ (1,-100) [-100|155] "%" Vector__XXX
 SG_ EMUS_IndividualCellTemperat_0003 : 32|8@1+ (1,-100) [-100|155] "%" Vector__XXX
 SG_ EMUS_IndividualCellTemperat_0002 : 24|8@1+ (1,-100) [-100|155] "%" Vector__XXX
 SG_ EMUS_IndividualCellTemperat_0001 : 16|8@1+ (1,-100) [-100|155] "%" Vector__XXX
 SG_ EMUS_IndividualCellTemperat_0000 : 8|8@1+ (1,-100) [-100|155] "%" Vector__XXX
 SG_ EMUS_IndividualCellTemperature_D : 0|8@1+ (1,-100) [-100|155] "%" Vector__XXX

BO_ 2578778113 EMUS_Individual_Cell_Temp_E_0000: 8 EMUS_BMS
 SG_ EMUS_IndividualCellTemperat_0014 : 56|8@1+ (1,-100) [-100|155] "%" Vector__XXX
 SG_ EMUS_IndividualCellTemperat_0013 : 48|8@1+ (1,-100) [-100|155] "%" Vector__XXX
 SG_ EMUS_IndividualCellTemperat_0012 : 40|8@1+ (1,-100) [-100|155] "%" Vector__XXX
 SG_ EMUS_IndividualCellTemperat_0011 : 32|8@1+ (1,-100) [-100|155] "%" Vector__XXX
 SG_ EMUS_IndividualCellTemperat_0010 : 24|8@1+ (1,-100) [-100|155] "%" Vector__XXX
 SG_ EMUS_IndividualCellTemperat_0009 : 16|8@1+ (1,-100) [-100|155] "%" Vector__XXX
 SG_ EMUS_IndividualCellTemperat_0008 : 8|8@1+ (1,-100) [-100|155] "%" Vector__XXX
 SG_ EMUS_IndividualCellTemperat_0007 : 0|8@1+ (1,-100) [-100|155] "%" Vector__XXX

BO_ 2578778114 EMUS_Individual_Cell_Temp_E_0001: 8 EMUS_BMS
 SG_ EMUS_IndividualCellTemperat_0022 : 56|8@1+ (1,-100) [-100|155] "%" Vector__XXX
 SG_ EMUS_IndividualCellTemperat_0021 : 48|8@1+ (1,-100) [-100|155] "%" Vector__XXX
 SG_ EMUS_IndividualCellTemperat_0020 : 40|8@1+ (1,-100) [-100|155] "%" Vector__XXX
 SG_ EMUS_IndividualCellTemperat_0019 : 32|8@1+ (1,-100) [-100|155] "%" Vector__XXX
 SG_ EMUS_IndividualCellTemperat_0018 : 24|8@1+ (1,-100) [-100|155] "%" Vector__XXX
 SG_ EMUS_IndividualCellTemperat_0017 : 16|8@1+ (1,-100) [-100|155] "%" Vector__XXX
 SG_ EMUS_IndividualCellTemperat_0016 : 8|8@1+ (1,-100) [-100|155] "%" Vector__XXX
 SG_ EMUS_IndividualCellTemperat_0015 : 0|8@1+ (1,-100) [-100|155] "%" Vector__XXX

BO_ 2578778115 EMUS_Individual_Cell_Temp_E_0002: 8 EMUS_BMS
 SG_ EMUS_IndividualCellTemperat_0030 : 56|8@1+ (1,-100) [-100|155] "%" Vector__XXX
 SG_ EMUS_IndividualCellTemperat_0029 : 48|8@1+ (1,-100) [-100|155] "%" Vector__XXX
 SG_ EMUS_IndividualCellTemperat_0028 : 40|8@1+ (1,-100) [-100|155] "%" Vector__XXX
 SG_ EMUS_IndividualCellTemperat_0027 : 32|8@1+ (1,-100) [-100|155] "%" Vector__XXX
 SG_ EMUS_IndividualCellTemperat_0026 : 24|8@1+ (1,-100) [-100|155] "%" Vector__XXX
 SG_ EMUS_IndividualCellTemperat_0025 : 16|8@1+ (1,-100) [-100|155] "%" Vector__XXX
 SG_ EMUS_IndividualCellTemperat_0024 : 8|8@1+ (1,-100) [-100|155] "%" Vector__XXX
 SG_ EMUS_IndividualCellTemperat_0023 : 0|8@1+ (1,-100) [-100|155] "%" Vector__XXX

BO_ 2578778116 EMUS_Individual_Cell_Temp_E_0003: 8 EMUS_BMS
 SG_ EMUS_IndividualCellTemperat_0038 : 56|8@1+ (1,-100) [-100|155] "%" Vector__XXX
 SG_ EMUS_IndividualCellTemperat_0037 : 48|8@1+ (1,-100) [-100|155] "%" Vector__XXX
 SG_ EMUS_IndividualCellTemperat_0036 : 40|8@1+ (1,-100) [-100|155] "%" Vector__XXX
 SG_ EMUS_IndividualCellTemperat_0035 : 32|8@1+ (1,-100) [-100|155] "%" Vector__XXX
 SG_ EMUS_IndividualCellTemperat_0034 : 24|8@1+ (1,-100) [-100|155] "%" Vector__XXX
 SG_ EMUS_IndividualCellTemperat_0033 : 16|8@1+ (1,-100) [-100|155] "%" Vector__XXX
 SG_ EMUS_IndividualCellTemperat_0032 : 8|8@1+ (1,-100) [-100|155] "%" Vector__XXX
 SG_ EMUS_IndividualCellTemperat_0031 : 0|8@1+ (1,-100) [-100|155] "%" Vector__XXX

BO_ 2578778117 EMUS_Individual_Cell_Temp_E_0004: 8 EMUS_BMS
 SG_ EMUS_IndividualCellTemperat_0046 : 56|8@1+ (1,-100) [-100|155] "%" Vector__XXX
 SG_ EMUS_IndividualCellTemperat_0045 : 48|8@1+ (1,-100) [-100|155] "%" Vector__XXX
 SG_ EMUS_IndividualCellTemperat_0044 : 40|8@1+ (1,-100) [-100|155] "%" Vector__XXX
 SG_ EMUS_IndividualCellTemperat_0043 : 32|8@1+ (1,-100) [-100|155] "%" Vector__XXX
 SG_ EMUS_IndividualCellTemperat_0042 : 24|8@1+ (1,-100) [-100|155] "%" Vector__XXX
 SG_ EMUS_IndividualCellTemperat_0041 : 16|8@1+ (1,-100) [-100|155] "%" Vector__XXX
 SG_ EMUS_IndividualCellTemperat_0040 : 8|8@1+ (1,-100) [-100|155] "%" Vector__XXX
 SG_ EMUS_IndividualCellTemperat_0039 : 0|8@1+ (1,-100) [-100|155] "%" Vector__XXX

BO_ 2578778118 EMUS_Individual_Cell_Temp_E_0005: 8 EMUS_BMS
 SG_ EMUS_IndividualCellTemperat_0054 : 56|8@1+ (1,-100) [-100|155] "%" Vector__XXX
 SG_ EMUS_IndividualCellTemperat_0053 : 48|8@1+ (1,-100) [-100|155] "%" Vector__XXX
 SG_ EMUS_IndividualCellTemperat_0052 : 40|8@1+ (1,-100) [-100|155] "%" Vector__XXX
 SG_ EMUS_IndividualCellTemperat_0051 : 32|8@1+ (1,-100) [-100|155] "%" Vector__XXX
 SG_ EMUS_IndividualCellTemperat_0050 : 24|8@1+ (1,-100) [-100|155] "%" Vector__XXX
 SG_ EMUS_IndividualCellTemperat_0049 : 16|8@1+ (1,-100) [-100|155] "%" Vector__XXX
 SG_ EMUS_IndividualCellTemperat_0048 : 8|8@1+ (1,-100) [-100|155] "%" Vector__XXX
 SG_ EMUS_IndividualCellTemperat_0047 : 0|8@1+ (1,-100) [-100|155] "%" Vector__XXX

BO_ 2578778119 EMUS_Individual_Cell_Temp_E_0006: 8 EMUS_BMS
 SG_ EMUS_IndividualCellTemperat_0062 : 56|8@1+ (1,-100) [-100|155] "%" Vector__XXX
 SG_ EMUS_IndividualCellTemperat_0061 : 48|8@1+ (1,-100) [-100|155] "%" Vector__XXX
 SG_ EMUS_IndividualCellTemperat_0060 : 40|8@1+ (1,-100) [-100|155] "%" Vector__XXX
 SG_ EMUS_IndividualCellTemperat_0059 : 32|8@1+ (1,-100) [-100|155] "%" Vector__XXX
 SG_ EMUS_IndividualCellTemperat_0058 : 24|8@1+ (1,-100) [-100|155] "%" Vector__XXX
 SG_ EMUS_IndividualCellTemperat_0057 : 16|8@1+ (1,-100) [-100|155] "%" Vector__XXX
 SG_ EMUS_IndividualCellTemperat_0056 : 8|8@1+ (1,-100) [-100|155] "%" Vector__XXX
 SG_ EMUS_IndividualCellTemperat_0055 : 0|8@1+ (1,-100) [-100|155] "%" Vector__XXX

BO_ 2578778120 EMUS_Individual_Cell_Temp_E_0007: 8 EMUS_BMS
 SG_ EMUS_IndividualCellTemperat_0070 : 56|8@1+ (1,-100) [-100|155] "%" Vector__XXX
 SG_ EMUS_IndividualCellTemperat_0069 : 48|8@1+ (1,-100) [-100|155] "%" Vector__XXX
 SG_ EMUS_IndividualCellTemperat_0068 : 40|8@1+ (1,-100) [-100|155] "%" Vector__XXX
 SG_ EMUS_IndividualCellTemperat_0067 : 32|8@1+ (1,-100) [-100|155] "%" Vector__XXX
 SG_ EMUS_IndividualCellTemperat_0066 : 24|8@1+ (1,-100) [-100|155] "%" Vector__XXX
 SG_ EMUS_IndividualCellTemperat_0065 : 16|8@1+ (1,-100) [-100|155] "%" Vector__XXX
 SG_ EMUS_IndividualCellTemperat_0064 : 8|8@1+ (1,-100) [-100|155] "%" Vector__XXX
 SG_ EMUS_IndividualCellTemperat_0063 : 0|8@1+ (1,-100) [-100|155] "%" Vector__XXX

BO_ 2578778121 EMUS_Individual_Cell_Temp_E_0008: 8 EMUS_BMS
 SG_ EMUS_IndividualCellTemperat_0078 : 56|8@1+ (1,-100) [-100|155] "%" Vector__XXX
 SG_ EMUS_IndividualCellTemperat_0077 : 48|8@1+ (1,-100) [-100|155] "%" Vector__XXX
 SG_ EMUS_IndividualCellTemperat_0076 : 40|8@1+ (1,-100) [-100|155] "%" Vector__XXX
 SG_ EMUS_IndividualCellTemperat_0075 : 32|8@1+ (1,-100) [-100|155] "%" Vector__XXX
 SG_ EMUS_IndividualCellTemperat_0074 : 24|8@1+ (1,-100) [-100|155] "%" Vector__XXX
 SG_ EMUS_IndividualCellTemperat_0073 : 16|8@1+ (1,-100) [-100|155] "%" Vector__XXX
 SG_ EMUS_IndividualCellTemperat_0072 : 8|8@1+ (1,-100) [-100|155] "%" Vector__XXX
 SG_ EMUS_IndividualCellTemperat_0071 : 0|8@1+ (1,-100) [-100|155] "%" Vector__XXX

BO_ 2578778122 EMUS_Individual_Cell_Temp_Ext_A1: 8 EMUS_BMS
 SG_ EMUS_IndividualCellTemperat_0086 : 56|8@1+ (1,-100) [-100|155] "%" Vector__XXX
 SG_ EMUS_IndividualCellTemperat_0085 : 48|8@1+ (1,-100) [-100|155] "%" Vector__XXX
 SG_ EMUS_IndividualCellTemperat_0084 : 40|8@1+ (1,-100) [-100|155] "%" Vector__XXX
 SG_ EMUS_IndividualCellTemperat_0083 : 32|8@1+ (1,-100) [-100|155] "%" Vector__XXX
 SG_ EMUS_IndividualCellTemperat_0082 : 24|8@1+ (1,-100) [-100|155] "%" Vector__XXX
 SG_ EMUS_IndividualCellTemperat_0081 : 16|8@1+ (1,-100) [-100|155] "%" Vector__XXX
 SG_ EMUS_IndividualCellTemperat_0080 : 8|8@1+ (1,-100) [-100|155] "%" Vector__XXX
 SG_ EMUS_IndividualCellTemperat_0079 : 0|8@1+ (1,-100) [-100|155] "%" Vector__XXX

BO_ 2578776075 EMUS_Individual_Cells_Volta_0017: 8 EMUS_BMS
 SG_ EMUS_IndividualCellVoltage__0149 : 56|8@1+ (0.01,2) [2|4.55] "V" Vector__XXX
 SG_ EMUS_IndividualCellVoltage__0148 : 48|8@1+ (0.01,2) [2|4.55] "V" Vector__XXX
 SG_ EMUS_IndividualCellVoltage__0147 : 40|8@1+ (0.01,2) [2|4.55] "V" Vector__XXX
 SG_ EMUS_IndividualCellVoltage__0146 : 32|8@1+ (0.01,2) [2|4.55] "V" Vector__XXX
 SG_ EMUS_IndividualCellVoltage__0145 : 24|8@1+ (0.01,2) [2|4.55] "V" Vector__XXX
 SG_ EMUS_IndividualCellVoltage__0144 : 16|8@1+ (0.01,2) [2|4.55] "V" Vector__XXX
 SG_ EMUS_IndividualCellVoltage__0143 : 8|8@1+ (0.01,2) [2|4.55] "V" Vector__XXX
 SG_ EMUS_Individual_Cells_Group_Opt_ : 0|8@1+ (1,0) [0|255] "" Vector__XXX

BO_ 2578776077 EMUS_Individual_Cell_Balan_Rate_: 8 EMUS_BMS
 SG_ EMUS_IndividualCellBalancRa_0005 : 56|8@1+ (0.392156862745098,0) [0|100] "%" Vector__XXX
 SG_ EMUS_IndividualCellBalancRa_0004 : 48|8@1+ (0.392156862745098,0) [0|100] "%" Vector__XXX
 SG_ EMUS_IndividualCellBalancRa_0003 : 40|8@1+ (0.392156862745098,0) [0|100] "%" Vector__XXX
 SG_ EMUS_IndividualCellBalancRa_0002 : 32|8@1+ (0.392156862745098,0) [0|100] "%" Vector__XXX
 SG_ EMUS_IndividualCellBalancRa_0001 : 24|8@1+ (0.392156862745098,0) [0|100] "%" Vector__XXX
 SG_ EMUS_IndividualCellBalancRa_0000 : 16|8@1+ (0.392156862745098,0) [0|100] "%" Vector__XXX
 SG_ EMUS_IndividualCellBalancRate_Da : 8|8@1+ (0.392156862745098,0) [0|100] "%" Vector__XXX
 SG_ EMUS_Individual_Cells_Group_0000 : 0|8@1+ (1,0) [0|255] "" Vector__XXX

BO_ 2578776832 EMUS_Individual_Cell_Balan__0000: 8 EMUS_BMS
 SG_ EMUS_IndividualCellBalancRa_0013 : 56|8@1+ (0.392156862745098,0) [0|100] "%" Vector__XXX
 SG_ EMUS_IndividualCellBalancRa_0012 : 48|8@1+ (0.392156862745098,0) [0|100] "%" Vector__XXX
 SG_ EMUS_IndividualCellBalancRa_0011 : 40|8@1+ (0.392156862745098,0) [0|100] "%" Vector__XXX
 SG_ EMUS_IndividualCellBalancRa_0010 : 32|8@1+ (0.392156862745098,0) [0|100] "%" Vector__XXX
 SG_ EMUS_IndividualCellBalancRa_0009 : 24|8@1+ (0.392156862745098,0) [0|100] "%" Vector__XXX
 SG_ EMUS_IndividualCellBalancRa_0008 : 16|8@1+ (0.392156862745098,0) [0|100] "%" Vector__XXX
 SG_ EMUS_IndividualCellBalancRa_0007 : 8|8@1+ (0.392156862745098,0) [0|100] "%" Vector__XXX
 SG_ EMUS_IndividualCellBalancRa_0006 : 0|8@1+ (0.392156862745098,0) [0|100] "%" Vector__XXX

BO_ 2578776833 EMUS_Individual_Cell_Balan__0001: 8 EMUS_BMS
 SG_ EMUS_IndividualCellBalancRa_0021 : 56|8@1+ (0.392156862745098,0) [0|100] "%" Vector__XXX
 SG_ EMUS_IndividualCellBalancRa_0020 : 48|8@1+ (0.392156862745098,0) [0|100] "%" Vector__XXX
 SG_ EMUS_IndividualCellBalancRa_0019 : 40|8@1+ (0.392156862745098,0) [0|100] "%" Vector__XXX
 SG_ EMUS_IndividualCellBalancRa_0018 : 32|8@1+ (0.392156862745098,0) [0|100] "%" Vector__XXX
 SG_ EMUS_IndividualCellBalancRa_0017 : 24|8@1+ (0.392156862745098,0) [0|100] "%" Vector__XXX
 SG_ EMUS_IndividualCellBalancRa_0016 : 16|8@1+ (0.392156862745098,0) [0|100] "%" Vector__XXX
 SG_ EMUS_IndividualCellBalancRa_0015 : 8|8@1+ (0.392156862745098,0) [0|100] "%" Vector__XXX
 SG_ EMUS_IndividualCellBalancRa_0014 : 0|8@1+ (0.392156862745098,0) [0|100] "%" Vector__XXX

BO_ 2578776834 EMUS_Individual_Cell_Balan__0002: 8 EMUS_BMS
 SG_ EMUS_IndividualCellBalancRa_0029 : 56|8@1+ (0.392156862745098,0) [0|100] "%" Vector__XXX
 SG_ EMUS_IndividualCellBalancRa_0028 : 48|8@1+ (0.392156862745098,0) [0|100] "%" Vector__XXX
 SG_ EMUS_IndividualCellBalancRa_0027 : 40|8@1+ (0.392156862745098,0) [0|100] "%" Vector__XXX
 SG_ EMUS_IndividualCellBalancRa_0026 : 32|8@1+ (0.392156862745098,0) [0|100] "%" Vector__XXX
 SG_ EMUS_IndividualCellBalancRa_0025 : 24|8@1+ (0.392156862745098,0) [0|100] "%" Vector__XXX
 SG_ EMUS_IndividualCellBalancRa_0024 : 16|8@1+ (0.392156862745098,0) [0|100] "%" Vector__XXX
 SG_ EMUS_IndividualCellBalancRa_0023 : 8|8@1+ (0.392156862745098,0) [0|100] "%" Vector__XXX
 SG_ EMUS_IndividualCellBalancRa_0022 : 0|8@1+ (0.392156862745098,0) [0|100] "%" Vector__XXX

BO_ 2578776835 EMUS_Individual_Cell_Balan__0003: 8 EMUS_BMS
 SG_ EMUS_IndividualCellBalancRa_0037 : 56|8@1+ (0.392156862745098,0) [0|100] "%" Vector__XXX
 SG_ EMUS_IndividualCellBalancRa_0036 : 48|8@1+ (0.392156862745098,0) [0|100] "%" Vector__XXX
 SG_ EMUS_IndividualCellBalancRa_0035 : 40|8@1+ (0.392156862745098,0) [0|100] "%" Vector__XXX
 SG_ EMUS_IndividualCellBalancRa_0034 : 32|8@1+ (0.392156862745098,0) [0|100] "%" Vector__XXX
 SG_ EMUS_IndividualCellBalancRa_0033 : 24|8@1+ (0.392156862745098,0) [0|100] "%" Vector__XXX
 SG_ EMUS_IndividualCellBalancRa_0032 : 16|8@1+ (0.392156862745098,0) [0|100] "%" Vector__XXX
 SG_ EMUS_IndividualCellBalancRa_0031 : 8|8@1+ (0.392156862745098,0) [0|100] "%" Vector__XXX
 SG_ EMUS_IndividualCellBalancRa_0030 : 0|8@1+ (0.392156862745098,0) [0|100] "%" Vector__XXX

BO_ 2578776836 EMUS_Individual_Cell_Balan__0004: 8 EMUS_BMS
 SG_ EMUS_IndividualCellBalancRa_0045 : 56|8@1+ (0.392156862745098,0) [0|100] "%" Vector__XXX
 SG_ EMUS_IndividualCellBalancRa_0044 : 48|8@1+ (0.392156862745098,0) [0|100] "%" Vector__XXX
 SG_ EMUS_IndividualCellBalancRa_0043 : 40|8@1+ (0.392156862745098,0) [0|100] "%" Vector__XXX
 SG_ EMUS_IndividualCellBalancRa_0042 : 32|8@1+ (0.392156862745098,0) [0|100] "%" Vector__XXX
 SG_ EMUS_IndividualCellBalancRa_0041 : 24|8@1+ (0.392156862745098,0) [0|100] "%" Vector__XXX
 SG_ EMUS_IndividualCellBalancRa_0040 : 16|8@1+ (0.392156862745098,0) [0|100] "%" Vector__XXX
 SG_ EMUS_IndividualCellBalancRa_0039 : 8|8@1+ (0.392156862745098,0) [0|100] "%" Vector__XXX
 SG_ EMUS_IndividualCellBalancRa_0038 : 0|8@1+ (0.392156862745098,0) [0|100] "%" Vector__XXX

BO_ 2578776837 EMUS_Individual_Cell_Balan__0005: 8 EMUS_BMS
 SG_ EMUS_IndividualCellBalancRa_0053 : 56|8@1+ (0.392156862745098,0) [0|100] "%" Vector__XXX
 SG_ EMUS_IndividualCellBalancRa_0052 : 48|8@1+ (0.392156862745098,0) [0|100] "%" Vector__XXX
 SG_ EMUS_IndividualCellBalancRa_0051 : 40|8@1+ (0.392156862745098,0) [0|100] "%" Vector__XXX
 SG_ EMUS_IndividualCellBalancRa_0050 : 32|8@1+ (0.392156862745098,0) [0|100] "%" Vector__XXX
 SG_ EMUS_IndividualCellBalancRa_0049 : 24|8@1+ (0.392156862745098,0) [0|100] "%" Vector__XXX
 SG_ EMUS_IndividualCellBalancRa_0048 : 16|8@1+ (0.392156862745098,0) [0|100] "%" Vector__XXX
 SG_ EMUS_IndividualCellBalancRa_0047 : 8|8@1+ (0.392156862745098,0) [0|100] "%" Vector__XXX
 SG_ EMUS_IndividualCellBalancRa_0046 : 0|8@1+ (0.392156862745098,0) [0|100] "%" Vector__XXX

BO_ 2578776838 EMUS_Individual_Cell_Balan__0006: 8 EMUS_BMS
 SG_ EMUS_IndividualCellBalancRa_0061 : 56|8@1+ (0.392156862745098,0) [0|100] "%" Vector__XXX
 SG_ EMUS_IndividualCellBalancRa_0060 : 48|8@1+ (0.392156862745098,0) [0|100] "%" Vector__XXX
 SG_ EMUS_IndividualCellBalancRa_0059 : 40|8@1+ (0.392156862745098,0) [0|100] "%" Vector__XXX
 SG_ EMUS_IndividualCellBalancRa_0058 : 32|8@1+ (0.392156862745098,0) [0|100] "%" Vector__XXX
 SG_ EMUS_IndividualCellBalancRa_0057 : 24|8@1+ (0.392156862745098,0) [0|100] "%" Vector__XXX
 SG_ EMUS_IndividualCellBalancRa_0056 : 16|8@1+ (0.392156862745098,0) [0|100] "%" Vector__XXX
 SG_ EMUS_IndividualCellBalancRa_0055 : 8|8@1+ (0.392156862745098,0) [0|100] "%" Vector__XXX
 SG_ EMUS_IndividualCellBalancRa_0054 : 0|8@1+ (0.392156862745098,0) [0|100] "%" Vector__XXX

BO_ 2578776839 EMUS_Individual_Cell_Balan__0007: 8 EMUS_BMS
 SG_ EMUS_IndividualCellBalancRa_0069 : 56|8@1+ (0.392156862745098,0) [0|100] "%" Vector__XXX
 SG_ EMUS_IndividualCellBalancRa_0068 : 48|8@1+ (0.392156862745098,0) [0|100] "%" Vector__XXX
 SG_ EMUS_IndividualCellBalancRa_0067 : 40|8@1+ (0.392156862745098,0) [0|100] "%" Vector__XXX
 SG_ EMUS_IndividualCellBalancRa_0066 : 32|8@1+ (0.392156862745098,0) [0|100] "%" Vector__XXX
 SG_ EMUS_IndividualCellBalancRa_0065 : 24|8@1+ (0.392156862745098,0) [0|100] "%" Vector__XXX
 SG_ EMUS_IndividualCellBalancRa_0064 : 16|8@1+ (0.392156862745098,0) [0|100] "%" Vector__XXX
 SG_ EMUS_IndividualCellBalancRa_0063 : 8|8@1+ (0.392156862745098,0) [0|100] "%" Vector__XXX
 SG_ EMUS_IndividualCellBalancRa_0062 : 0|8@1+ (0.392156862745098,0) [0|100] "%" Vector__XXX

BO_ 2578776840 EMUS_Individual_Cell_Balan__0008: 8 EMUS_BMS
 SG_ EMUS_IndividualCellBalancRa_0077 : 56|8@1+ (0.392156862745098,0) [0|100] "%" Vector__XXX
 SG_ EMUS_IndividualCellBalancRa_0076 : 48|8@1+ (0.392156862745098,0) [0|100] "%" Vector__XXX
 SG_ EMUS_IndividualCellBalancRa_0075 : 40|8@1+ (0.392156862745098,0) [0|100] "%" Vector__XXX
 SG_ EMUS_IndividualCellBalancRa_0074 : 32|8@1+ (0.392156862745098,0) [0|100] "%" Vector__XXX
 SG_ EMUS_IndividualCellBalancRa_0073 : 24|8@1+ (0.392156862745098,0) [0|100] "%" Vector__XXX
 SG_ EMUS_IndividualCellBalancRa_0072 : 16|8@1+ (0.392156862745098,0) [0|100] "%" Vector__XXX
 SG_ EMUS_IndividualCellBalancRa_0071 : 8|8@1+ (0.392156862745098,0) [0|100] "%" Vector__XXX
 SG_ EMUS_IndividualCellBalancRa_0070 : 0|8@1+ (0.392156862745098,0) [0|100] "%" Vector__XXX

BO_ 2578776841 EMUS_Individual_Cell_Balan__0009: 8 EMUS_BMS
 SG_ EMUS_IndividualCellBalancRa_0085 : 56|8@1+ (0.392156862745098,0) [0|100] "%" Vector__XXX
 SG_ EMUS_IndividualCellBalancRa_0084 : 48|8@1+ (0.392156862745098,0) [0|100] "%" Vector__XXX
 SG_ EMUS_IndividualCellBalancRa_0083 : 40|8@1+ (0.392156862745098,0) [0|100] "%" Vector__XXX
 SG_ EMUS_IndividualCellBalancRa_0082 : 32|8@1+ (0.392156862745098,0) [0|100] "%" Vector__XXX
 SG_ EMUS_IndividualCellBalancRa_0081 : 24|8@1+ (0.392156862745098,0) [0|100] "%" Vector__XXX
 SG_ EMUS_IndividualCellBalancRa_0080 : 16|8@1+ (0.392156862745098,0) [0|100] "%" Vector__XXX
 SG_ EMUS_IndividualCellBalancRa_0079 : 8|8@1+ (0.392156862745098,0) [0|100] "%" Vector__XXX
 SG_ EMUS_IndividualCellBalancRa_0078 : 0|8@1+ (0.392156862745098,0) [0|100] "%" Vector__XXX

BO_ 2578776842 EMUS_Individual_Cell_Balan__0010: 8 EMUS_BMS
 SG_ EMUS_IndividualCellBalancRa_0093 : 56|8@1+ (0.392156862745098,0) [0|100] "%" Vector__XXX
 SG_ EMUS_IndividualCellBalancRa_0092 : 48|8@1+ (0.392156862745098,0) [0|100] "%" Vector__XXX
 SG_ EMUS_IndividualCellBalancRa_0091 : 40|8@1+ (0.392156862745098,0) [0|100] "%" Vector__XXX
 SG_ EMUS_IndividualCellBalancRa_0090 : 32|8@1+ (0.392156862745098,0) [0|100] "%" Vector__XXX
 SG_ EMUS_IndividualCellBalancRa_0089 : 24|8@1+ (0.392156862745098,0) [0|100] "%" Vector__XXX
 SG_ EMUS_IndividualCellBalancRa_0088 : 16|8@1+ (0.392156862745098,0) [0|100] "%" Vector__XXX
 SG_ EMUS_IndividualCellBalancRa_0087 : 8|8@1+ (0.392156862745098,0) [0|100] "%" Vector__XXX
 SG_ EMUS_IndividualCellBalancRa_0086 : 0|8@1+ (0.392156862745098,0) [0|100] "%" Vector__XXX

BO_ 2578776843 EMUS_Individual_Cell_Balan__0011: 8 EMUS_BMS
 SG_ EMUS_IndividualCellBalancRa_0101 : 56|8@1+ (0.392156862745098,0) [0|100] "%" Vector__XXX
 SG_ EMUS_IndividualCellBalancRa_0100 : 48|8@1+ (0.392156862745098,0) [0|100] "%" Vector__XXX
 SG_ EMUS_IndividualCellBalancRa_0099 : 40|8@1+ (0.392156862745098,0) [0|100] "%" Vector__XXX
 SG_ EMUS_IndividualCellBalancRa_0098 : 32|8@1+ (0.392156862745098,0) [0|100] "%" Vector__XXX
 SG_ EMUS_IndividualCellBalancRa_0097 : 24|8@1+ (0.392156862745098,0) [0|100] "%" Vector__XXX
 SG_ EMUS_IndividualCellBalancRa_0096 : 16|8@1+ (0.392156862745098,0) [0|100] "%" Vector__XXX
 SG_ EMUS_IndividualCellBalancRa_0095 : 8|8@1+ (0.392156862745098,0) [0|100] "%" Vector__XXX
 SG_ EMUS_IndividualCellBalancRa_0094 : 0|8@1+ (0.392156862745098,0) [0|100] "%" Vector__XXX

BO_ 2578776844 EMUS_Individual_Cell_Balan__0012: 8 EMUS_BMS
 SG_ EMUS_IndividualCellBalancRa_0109 : 56|8@1+ (0.392156862745098,0) [0|100] "%" Vector__XXX
 SG_ EMUS_IndividualCellBalancRa_0108 : 48|8@1+ (0.392156862745098,0) [0|100] "%" Vector__XXX
 SG_ EMUS_IndividualCellBalancRa_0107 : 40|8@1+ (0.392156862745098,0) [0|100] "%" Vector__XXX
 SG_ EMUS_IndividualCellBalancRa_0106 : 32|8@1+ (0.392156862745098,0) [0|100] "%" Vector__XXX
 SG_ EMUS_IndividualCellBalancRa_0105 : 24|8@1+ (0.392156862745098,0) [0|100] "%" Vector__XXX
 SG_ EMUS_IndividualCellBalancRa_0104 : 16|8@1+ (0.392156862745098,0) [0|100] "%" Vector__XXX
 SG_ EMUS_IndividualCellBalancRa_0103 : 8|8@1+ (0.392156862745098,0) [0|100] "%" Vector__XXX
 SG_ EMUS_IndividualCellBalancRa_0102 : 0|8@1+ (0.392156862745098,0) [0|100] "%" Vector__XXX

BO_ 2578776845 EMUS_Individual_Cell_Balan__0013: 8 EMUS_BMS
 SG_ EMUS_IndividualCellBalancRa_0117 : 56|8@1+ (0.392156862745098,0) [0|100] "%" Vector__XXX
 SG_ EMUS_IndividualCellBalancRa_0116 : 48|8@1+ (0.392156862745098,0) [0|100] "%" Vector__XXX
 SG_ EMUS_IndividualCellBalancRa_0115 : 40|8@1+ (0.392156862745098,0) [0|100] "%" Vector__XXX
 SG_ EMUS_IndividualCellBalancRa_0114 : 32|8@1+ (0.392156862745098,0) [0|100] "%" Vector__XXX
 SG_ EMUS_IndividualCellBalancRa_0113 : 24|8@1+ (0.392156862745098,0) [0|100] "%" Vector__XXX
 SG_ EMUS_IndividualCellBalancRa_0112 : 16|8@1+ (0.392156862745098,0) [0|100] "%" Vector__XXX
 SG_ EMUS_IndividualCellBalancRa_0111 : 8|8@1+ (0.392156862745098,0) [0|100] "%" Vector__XXX
 SG_ EMUS_IndividualCellBalancRa_0110 : 0|8@1+ (0.392156862745098,0) [0|100] "%" Vector__XXX

BO_ 2578776846 EMUS_Individual_Cell_Balan__0014: 8 EMUS_BMS
 SG_ EMUS_IndividualCellBalancRa_0125 : 56|8@1+ (0.392156862745098,0) [0|100] "%" Vector__XXX
 SG_ EMUS_IndividualCellBalancRa_0124 : 48|8@1+ (0.392156862745098,0) [0|100] "%" Vector__XXX
 SG_ EMUS_IndividualCellBalancRa_0123 : 40|8@1+ (0.392156862745098,0) [0|100] "%" Vector__XXX
 SG_ EMUS_IndividualCellBalancRa_0122 : 32|8@1+ (0.392156862745098,0) [0|100] "%" Vector__XXX
 SG_ EMUS_IndividualCellBalancRa_0121 : 24|8@1+ (0.392156862745098,0) [0|100] "%" Vector__XXX
 SG_ EMUS_IndividualCellBalancRa_0120 : 16|8@1+ (0.392156862745098,0) [0|100] "%" Vector__XXX
 SG_ EMUS_IndividualCellBalancRa_0119 : 8|8@1+ (0.392156862745098,0) [0|100] "%" Vector__XXX
 SG_ EMUS_IndividualCellBalancRa_0118 : 0|8@1+ (0.392156862745098,0) [0|100] "%" Vector__XXX

BO_ 2578776847 EMUS_Individual_Cell_Balan__0015: 8 EMUS_BMS
 SG_ EMUS_IndividualCellBalancRa_0133 : 56|8@1+ (0.392156862745098,0) [0|100] "%" Vector__XXX
 SG_ EMUS_IndividualCellBalancRa_0132 : 48|8@1+ (0.392156862745098,0) [0|100] "%" Vector__XXX
 SG_ EMUS_IndividualCellBalancRa_0131 : 40|8@1+ (0.392156862745098,0) [0|100] "%" Vector__XXX
 SG_ EMUS_IndividualCellBalancRa_0130 : 32|8@1+ (0.392156862745098,0) [0|100] "%" Vector__XXX
 SG_ EMUS_IndividualCellBalancRa_0129 : 24|8@1+ (0.392156862745098,0) [0|100] "%" Vector__XXX
 SG_ EMUS_IndividualCellBalancRa_0128 : 16|8@1+ (0.392156862745098,0) [0|100] "%" Vector__XXX
 SG_ EMUS_IndividualCellBalancRa_0127 : 8|8@1+ (0.392156862745098,0) [0|100] "%" Vector__XXX
 SG_ EMUS_IndividualCellBalancRa_0126 : 0|8@1+ (0.392156862745098,0) [0|100] "%" Vector__XXX

BO_ 2578776848 EMUS_Individual_Cell_Balan__0016: 8 EMUS_BMS
 SG_ EMUS_IndividualCellBalancRa_0141 : 56|8@1+ (0.392156862745098,0) [0|100] "%" Vector__XXX
 SG_ EMUS_IndividualCellBalancRa_0140 : 48|8@1+ (0.392156862745098,0) [0|100] "%" Vector__XXX
 SG_ EMUS_IndividualCellBalancRa_0139 : 40|8@1+ (0.392156862745098,0) [0|100] "%" Vector__XXX
 SG_ EMUS_IndividualCellBalancRa_0138 : 32|8@1+ (0.392156862745098,0) [0|100] "%" Vector__XXX
 SG_ EMUS_IndividualCellBalancRa_0137 : 24|8@1+ (0.392156862745098,0) [0|100] "%" Vector__XXX
 SG_ EMUS_IndividualCellBalancRa_0136 : 16|8@1+ (0.392156862745098,0) [0|100] "%" Vector__XXX
 SG_ EMUS_IndividualCellBalancRa_0135 : 8|8@1+ (0.392156862745098,0) [0|100] "%" Vector__XXX
 SG_ EMUS_IndividualCellBalancRa_0134 : 0|8@1+ (0.392156862745098,0) [0|100] "%" Vector__XXX

BO_ 2578776849 EMUS_Individual_Cell_Balan__0017: 8 EMUS_BMS
 SG_ EMUS_IndividualCellBalancRa_0149 : 56|8@1+ (0.392156862745098,0) [0|100] "%" Vector__XXX
 SG_ EMUS_IndividualCellBalancRa_0148 : 48|8@1+ (0.392156862745098,0) [0|100] "%" Vector__XXX
 SG_ EMUS_IndividualCellBalancRa_0147 : 40|8@1+ (0.392156862745098,0) [0|100] "%" Vector__XXX
 SG_ EMUS_IndividualCellBalancRa_0146 : 32|8@1+ (0.392156862745098,0) [0|100] "%" Vector__XXX
 SG_ EMUS_IndividualCellBalancRa_0145 : 24|8@1+ (0.392156862745098,0) [0|100] "%" Vector__XXX
 SG_ EMUS_IndividualCellBalancRa_0144 : 16|8@1+ (0.392156862745098,0) [0|100] "%" Vector__XXX
 SG_ EMUS_IndividualCellBalancRa_0143 : 8|8@1+ (0.392156862745098,0) [0|100] "%" Vector__XXX
 SG_ EMUS_IndividualCellBalancRa_0142 : 0|8@1+ (0.392156862745098,0) [0|100] "%" Vector__XXX

BO_ 2578776076 EMUS_Individual_Cell_Mod_Te_0017: 8 EMUS_BMS
 SG_ EMUS_IndividualCellModTemp__0149 : 56|8@1+ (1,-100) [-100|155] "%" Vector__XXX
 SG_ EMUS_IndividualCellModTemp__0148 : 48|8@1+ (1,-100) [-100|155] "%" Vector__XXX
 SG_ EMUS_IndividualCellModTemp__0147 : 40|8@1+ (1,-100) [-100|155] "%" Vector__XXX
 SG_ EMUS_IndividualCellModTemp__0146 : 32|8@1+ (1,-100) [-100|155] "%" Vector__XXX
 SG_ EMUS_IndividualCellModTemp__0145 : 24|8@1+ (1,-100) [-100|155] "%" Vector__XXX
 SG_ EMUS_IndividualCellModTemp__0144 : 16|8@1+ (1,-100) [-100|155] "%" Vector__XXX
 SG_ EMUS_IndividualCellModTemp__0143 : 8|8@1+ (1,-100) [-100|155] "%" Vector__XXX
 SG_ EMUS_Individual_Cells_Group_0001 : 0|8@1+ (1,0) [0|255] "" Vector__XXX

BO_ 2578776078 EMUS_Individual_Cell_Temp_Ext_B: 8 EMUS_BMS
 SG_ EMUS_IndividualCellTemperat_0149 : 56|8@1+ (1,-100) [-100|155] "%" Vector__XXX
 SG_ EMUS_IndividualCellTemperat_0148 : 48|8@1+ (1,-100) [-100|155] "%" Vector__XXX
 SG_ EMUS_IndividualCellTemperat_0147 : 40|8@1+ (1,-100) [-100|155] "%" Vector__XXX
 SG_ EMUS_IndividualCellTemperat_0146 : 32|8@1+ (1,-100) [-100|155] "%" Vector__XXX
 SG_ EMUS_IndividualCellTemperat_0145 : 24|8@1+ (1,-100) [-100|155] "%" Vector__XXX
 SG_ EMUS_IndividualCellTemperat_0144 : 16|8@1+ (1,-100) [-100|155] "%" Vector__XXX
 SG_ EMUS_IndividualCellTemperat_0143 : 8|8@1+ (1,-100) [-100|155] "%" Vector__XXX
 SG_ EMUS_Individual_Cells_Group_0002 : 0|8@1+ (1,0) [0|255] "" Vector__XXX

BO_ 2578777091 EMUS_Login_Set_Password_Status_E: 8 EMUS_BMS
 SG_ EMUS_LoginSetPasswordStatus : 0|8@1+ (1,0) [0|255] "" Vector__XXX

BO_ 409 HVTU_TX_Voltage: 6 HVTU
 SG_ HVTU_EMUS_MaxCellVoltage : 40|8@1+ (0.01,2) [2|4.55] "V" Vector__XXX
 SG_ HVTU_EMUS_Pack_Voltage : 16|24@1- (0.01,0) [-83886.08|83886.07] "V" Vector__XXX
 SG_ HVTU_EMUS_AvgCellVoltage : 8|8@1+ (0.01,2) [2|4.55] "V" Vector__XXX
 SG_ HVTU_EMUS_MinCellVoltage : 0|8@1+ (0.01,2) [2|4.55] "V" Vector__XXX

BO_ 473 HVTU_RX_PDO1: 0 Vector__XXX

BO_ 537 HVTU_TX_Balance_Rate: 3 HVTU
 SG_ HVTU_EMUS_MinCellBalanceRate : 16|8@1+ (0.392156862745098,0) [0|100] "%" Vector__XXX
 SG_ HVTU_EMUS_MaxCellBalanceRate : 8|8@1+ (0.392156862745098,0) [0|100] "%" Vector__XXX
 SG_ HVTU_EMUS_AvgCellBalanceRate : 0|8@1+ (0.392156862745098,0) [0|100] "%" Vector__XXX

BO_ 601 HVTU_RX_PDO2: 0 Vector__XXX

BO_ 665 HVTU_TX_Cell_Mod_Temp: 3 HVTU
 SG_ HVTU_EMUS_MinCellModTemp : 16|8@1+ (1,-100) [-100|155] "ï¿½C" Vector__XXX
 SG_ HVTU_EMUS_AvgCellModTemp : 8|8@1+ (1,-100) [-100|155] "ï¿½C" Vector__XXX
 SG_ HVTU_EMUS_MaxCellModTemp : 0|8@1+ (1,-100) [-100|155] "ï¿½C" Vector__XXX

BO_ 729 HVTU_RX_PDO3: 0 Vector__XXX

BO_ 793 HVTU_TX_Cell_Temp: 3 HVTU
 SG_ HVTU_EMUS_MinCellTemp : 16|8@1+ (1,-100) [-100|155] "ï¿½C" Vector__XXX
 SG_ HVTU_EMUS_MaxCellTemp : 8|8@1+ (1,-100) [-100|155] "ï¿½C" Vector__XXX
 SG_ HVTU_EMUS_AvgCellTemp : 0|8@1+ (1,-100) [-100|155] "ï¿½C" Vector__XXX

BO_ 857 HVTU_RX_PDO4: 0 Vector__XXX

BO_ 921 HVTU_TX_Diagnostics: 3 HVTU
 SG_ HVTU_EMUS_Diag_UnderVoltage : 18|1@1+ (1,0) [0|0] "" Vector__XXX
 SG_ HVTU_EMUS_Diag_Pack_UnderVoltage : 17|1@1+ (1,0) [0|0] "" Vector__XXX
 SG_ HVTU_EMUS_Diag_OverVoltage : 16|1@1+ (1,0) [0|0] "" Vector__XXX
 SG_ HVTU_EMUS_Diag_NoCurrentSensor : 15|1@1+ (1,0) [0|0] "" Vector__XXX
 SG_ HVTU_EMUS_Diag_NumOfCellsVal : 14|1@1+ (1,0) [0|0] "" Vector__XXX
 SG_ HVTU_EMUS_Diag_NoCellComm : 13|1@1+ (1,0) [0|0] "" Vector__XXX
 SG_ HVTU_EMUS_Diag_LowVoltage : 12|1@1+ (1,0) [0|0] "" Vector__XXX
 SG_ HVTU_EMUS_Diag_Leackage : 11|1@1+ (1,0) [0|0] "" Vector__XXX
 SG_ HVTU_EMUS_Diag_HighTemp : 10|1@1+ (1,0) [0|0] "" Vector__XXX
 SG_ HVTU_EMUS_Diag_HighCurrent : 9|1@1+ (1,0) [0|0] "" Vector__XXX
 SG_ HVTU_EMUS_Diag_DchrgOverCurrent : 8|1@1+ (1,0) [0|0] "" Vector__XXX
 SG_ HVTU_EMUS_Diag_ChargeOverCurrent : 7|1@1+ (1,0) [0|0] "" Vector__XXX
 SG_ HVTU_EMUS_Diag_CellVoltValid : 6|1@1+ (1,0) [0|0] "" Vector__XXX
 SG_ HVTU_EMUS_Diag_CellTempValid : 5|1@1+ (1,0) [0|0] "" Vector__XXX
 SG_ HVTU_EMUS_Diag_CellOverHeat : 4|1@1+ (1,0) [0|0] "" Vector__XXX
 SG_ HVTU_EMUS_Diag_CellModTempValid : 3|1@1+ (1,0) [0|0] "" Vector__XXX
 SG_ HVTU_EMUS_Diag_CellModOverHeat : 2|1@1+ (1,0) [0|0] "" Vector__XXX
 SG_ HVTU_EMUS_Diag_CellBalanceValid : 1|1@1+ (1,0) [0|0] "" Vector__XXX
 SG_ HVTU_EMUS_Diag_BatChargeFinish : 0|1@1+ (1,0) [0|0] "" Vector__XXX

BO_ 985 HVTU_TX_Current_SOC: 5 HVTU
 SG_ HVTU_EMUS_Pack_SOC : 32|8@1+ (1,0) [0|100] "%" Vector__XXX
 SG_ HVTU_EMUS_Pack_Est_Charge : 16|16@1+ (0.1,0) [0|6553.5] "Ah" Vector__XXX
 SG_ HVTU_EMUS_Pack_Current : 0|16@1- (0.1,0) [-3276.8|3276.7] "A" Vector__XXX

BO_ 1049 HVTU_TX_PDO7: 0 HVTU

BO_ 1113 HVTU_TX_PDO8: 0 HVTU

BO_ 1177 HVTU_TX_PDO9: 0 HVTU

BO_ 1241 HVTU_TX_PDO10: 0 HVTU

BO_ 1305 HVTU_TX_PDO11: 0 HVTU

BO_ 1369 HVTU_TX_PDO12: 0 HVTU

BO_ 1433 HVTU_SDO_Resp: 8 HVTU
 SG_ HVTU_OD_CAN2_DelayedTxMessages m1129 : 16|24@1+ (1,0) [0|16777215] ""  TelemetryNode
 SG_ HVTU_OD_CAN2_ErrorStatus m1128 : 16|8@1+ (1,0) [0|255] ""  TelemetryNode
 SG_ HVTU_OD_CAN2_DiscardedTxMessages m1127 : 16|24@1+ (1,0) [0|16777215] ""  TelemetryNode
 SG_ HVTU_OD_CAN2_Status m1126 : 16|8@1+ (1,0) [0|255] ""  TelemetryNode
 SG_ HVTU_OD_CAN2_Baudrate m1124 : 16|16@1+ (1,0) [125|1000] "kbps"  TelemetryNode
 SG_ HVTU_OD_CAN2_autoErrorReset m1123 : 16|8@1+ (1,0) [0|255] ""  TelemetryNode
 SG_ HVTU_OD_CAN2_lastErrorCode m1122 : 16|32@1+ (1,0) [0|4294967295] ""  TelemetryNode
 SG_ HVTU_OD_CAN2_RxErrCnt m1121 : 16|8@1+ (1,0) [0|255] ""  TelemetryNode
 SG_ HVTU_OD_CAN2_TxErrCnt m1120 : 16|8@1+ (1,0) [0|255] ""  TelemetryNode
 SG_ HVTU_OD_CAN1_DelayedTxMessages m1113 : 16|24@1+ (1,0) [0|16777215] ""  TelemetryNode
 SG_ HVTU_OD_CAN1_ErrorStatus m1112 : 16|8@1+ (1,0) [0|255] ""  TelemetryNode
 SG_ HVTU_OD_CAN1_DiscardedTxMessages m1111 : 16|24@1+ (1,0) [0|16777215] ""  TelemetryNode
 SG_ HVTU_OD_CAN1_Status m1110 : 16|8@1+ (1,0) [0|255] ""  TelemetryNode
 SG_ HVTU_OD_CAN1_Baudrate m1108 : 16|16@1+ (1,0) [125|1000] "kbps"  TelemetryNode
 SG_ HVTU_OD_CAN1_autoErrorReset m1107 : 16|8@1+ (1,0) [0|255] ""  TelemetryNode
 SG_ HVTU_OD_CAN1_lastErrorCode m1106 : 16|32@1+ (1,0) [0|4294967295] ""  TelemetryNode
 SG_ HVTU_OD_CAN1_RxErrCnt m1105 : 16|8@1+ (1,0) [0|255] ""  TelemetryNode
 SG_ HVTU_OD_CAN1_TxErrCnt m1104 : 16|8@1+ (1,0) [0|255] ""  TelemetryNode
 SG_ HVTU_OD_BuildTime m1073 : 16|24@1+ (1,0) [0|16777215] ""  TelemetryNode
 SG_ HVTU_OD_BuildDate m1072 : 16|32@1+ (1,0) [0|4294967295] ""  TelemetryNode
 SG_ HVTU_OD_ChipUID2 m1057 : 16|48@1+ (1,0) [0|281474976710655] ""  TelemetryNode
 SG_ HVTU_OD_ChipUID1 m1056 : 16|48@1+ (1,0) [0|281474976710655] ""  TelemetryNode
 SG_ HVTU_OD_SdcOut m1046 : 16|8@1+ (1,0) [0|255] ""  TelemetryNode
 SG_ HVTU_OD_SdcIn m1045 : 16|8@1+ (1,0) [0|255] ""  TelemetryNode
 SG_ HVTU_OD_runtime m1044 : 16|24@1+ (1,0) [0|16777215] "ms"  TelemetryNode
 SG_ HVTU_OD_InputVoltage m1043 : 16|16@1+ (0.001,0) [0|65.535] "V"  TelemetryNode
 SG_ HVTU_OD_BoardTemp m1042 : 16|16@1+ (0.01,-30) [-30|625.35] "°C"  TelemetryNode
 SG_ HVTU_OD_MemFree m1041 : 16|16@1+ (4,0) [0|262140] "bytes"  TelemetryNode
 SG_ HVTU_OD_CpuUsage m1040 : 16|8@1+ (0.5,0) [0|100] "%"  TelemetryNode
 SG_ HVTU_OD_OdEntrySendInterval m33 : 16|16@1+ (1,0) [0|65535] "ms"  TelemetryNode
 SG_ HVTU_OD_SendOdOnBootup m32 : 16|8@1+ (1,0) [0|255] ""  TelemetryNode
 SG_ HVTU_OD_HeartbeatInterval m16 : 16|16@1+ (1,0) [0|65535] "ms"  TelemetryNode
 SG_ HVTU_OD_DbcVersion m5 : 16|16@1+ (1,0) [0|65535] ""  TelemetryNode
 SG_ HVTU_OD_StackVersion m4 : 16|16@1+ (1,0) [0|65535] ""  TelemetryNode
 SG_ HVTU_OD_ProtocolVersion m3 : 16|16@1+ (1,0) [0|65535] ""  TelemetryNode
 SG_ HVTU_OD_NodeStatus m2 : 16|8@1+ (1,0) [0|255] ""  TelemetryNode
 SG_ HVTU_OD_NodeID m1 : 16|8@1+ (1,0) [0|255] ""  TelemetryNode
 SG_ HVTU_SDO_RespCode : 12|4@1+ (1,0) [0|0] ""  TelemetryNode
 SG_ HVTU_SDO_ID M : 0|12@1+ (1,0) [0|4095] ""  TelemetryNode

BO_ 1497 HVTU_SDO_Req_Up: 8 TelemetryNode
 SG_ HVTU_OD_CAN2_DelayedTxMessages m1129 : 16|24@1+ (1,0) [0|16777215] ""  HVTU
 SG_ HVTU_OD_CAN2_ErrorStatus m1128 : 16|8@1+ (1,0) [0|255] ""  HVTU
 SG_ HVTU_OD_CAN2_DiscardedTxMessages m1127 : 16|24@1+ (1,0) [0|16777215] ""  HVTU
 SG_ HVTU_OD_CAN2_Status m1126 : 16|8@1+ (1,0) [0|255] ""  HVTU
 SG_ HVTU_OD_CAN2_Baudrate m1124 : 16|16@1+ (1,0) [125|1000] "kbps"  HVTU
 SG_ HVTU_OD_CAN2_autoErrorReset m1123 : 16|8@1+ (1,0) [0|255] ""  HVTU
 SG_ HVTU_OD_CAN2_lastErrorCode m1122 : 16|32@1+ (1,0) [0|4294967295] ""  HVTU
 SG_ HVTU_OD_CAN2_RxErrCnt m1121 : 16|8@1+ (1,0) [0|255] ""  HVTU
 SG_ HVTU_OD_CAN2_TxErrCnt m1120 : 16|8@1+ (1,0) [0|255] ""  HVTU
 SG_ HVTU_OD_CAN1_DelayedTxMessages m1113 : 16|24@1+ (1,0) [0|16777215] ""  HVTU
 SG_ HVTU_OD_CAN1_ErrorStatus m1112 : 16|8@1+ (1,0) [0|255] ""  HVTU
 SG_ HVTU_OD_CAN1_DiscardedTxMessages m1111 : 16|24@1+ (1,0) [0|16777215] ""  HVTU
 SG_ HVTU_OD_CAN1_Status m1110 : 16|8@1+ (1,0) [0|255] ""  HVTU
 SG_ HVTU_OD_CAN1_Baudrate m1108 : 16|16@1+ (1,0) [125|1000] "kbps"  HVTU
 SG_ HVTU_OD_CAN1_autoErrorReset m1107 : 16|8@1+ (1,0) [0|255] ""  HVTU
 SG_ HVTU_OD_CAN1_lastErrorCode m1106 : 16|32@1+ (1,0) [0|4294967295] ""  HVTU
 SG_ HVTU_OD_CAN1_RxErrCnt m1105 : 16|8@1+ (1,0) [0|255] ""  HVTU
 SG_ HVTU_OD_CAN1_TxErrCnt m1104 : 16|8@1+ (1,0) [0|255] ""  HVTU
 SG_ HVTU_OD_BuildTime m1073 : 16|24@1+ (1,0) [0|16777215] ""  HVTU
 SG_ HVTU_OD_BuildDate m1072 : 16|32@1+ (1,0) [0|4294967295] ""  HVTU
 SG_ HVTU_OD_ChipUID2 m1057 : 16|48@1+ (1,0) [0|281474976710655] ""  HVTU
 SG_ HVTU_OD_ChipUID1 m1056 : 16|48@1+ (1,0) [0|281474976710655] ""  HVTU
 SG_ HVTU_OD_SdcOut m1046 : 16|8@1+ (1,0) [0|255] ""  HVTU
 SG_ HVTU_OD_SdcIn m1045 : 16|8@1+ (1,0) [0|255] ""  HVTU
 SG_ HVTU_OD_runtime m1044 : 16|24@1+ (1,0) [0|16777215] "ms"  HVTU
 SG_ HVTU_OD_InputVoltage m1043 : 16|16@1+ (0.001,0) [0|65.535] "V"  HVTU
 SG_ HVTU_OD_BoardTemp m1042 : 16|16@1+ (0.01,-30) [-30|625.35] "°C"  HVTU
 SG_ HVTU_OD_MemFree m1041 : 16|16@1+ (4,0) [0|262140] "bytes"  HVTU
 SG_ HVTU_OD_CpuUsage m1040 : 16|8@1+ (0.5,0) [0|100] "%"  HVTU
 SG_ HVTU_OD_OdEntrySendInterval m33 : 16|16@1+ (1,0) [0|65535] "ms"  HVTU
 SG_ HVTU_OD_SendOdOnBootup m32 : 16|8@1+ (1,0) [0|255] ""  HVTU
 SG_ HVTU_OD_HeartbeatInterval m16 : 16|16@1+ (1,0) [0|65535] "ms"  HVTU
 SG_ HVTU_OD_DbcVersion m5 : 16|16@1+ (1,0) [0|65535] ""  HVTU
 SG_ HVTU_OD_StackVersion m4 : 16|16@1+ (1,0) [0|65535] ""  HVTU
 SG_ HVTU_OD_ProtocolVersion m3 : 16|16@1+ (1,0) [0|65535] ""  HVTU
 SG_ HVTU_OD_NodeStatus m2 : 16|8@1+ (1,0) [0|255] ""  HVTU
 SG_ HVTU_OD_NodeID m1 : 16|8@1+ (1,0) [0|255] ""  HVTU
 SG_ HVTU_SDO_ID M : 0|12@1+ (1,0) [0|4095] ""  HVTU

BO_ 1561 HVTU_SDO_Req_Down: 2 TelemetryNode
 SG_ HVTU_SDO_ID M : 0|12@1+ (1,0) [0|4095] ""  HVTU

BO_ 1817 HVTU_Heartbeat: 1 HVTU
 SG_ HVTU_NodeState : 0|8@1+ (1,0) [0|0] ""  Master,TelemetryNode

BO_ 1881 HVTU_BTL_TX: 8 HVTU

BO_ 1945 HVTU_BTL_RX: 8 TelemetryNode

BO_ 162 TelemetryNode_EMCY: 4 TelemetryNode
 SG_ TelemetryNode_E0_OtherError : 12|1@1+ (1,0) [0|0] ""  Master,TelemetryNode
 SG_ TelemetryNode_W0_OtherWarning : 0|1@1+ (1,0) [0|0] ""  Master,TelemetryNode

BO_ 418 TelemetryNode_TX_PDO1: 0 TelemetryNode

BO_ 482 TelemetryNode_RX_Shutdown: 1 Vector__XXX
 SG_ TelemetryNode_RX_Shutdown : 0|8@1+ (1,0) [0|0] "" Vector__XXX

BO_ 546 TelemetryNode_TX_PDO2: 0 TelemetryNode

BO_ 610 TelemetryNode_RX_PDO2: 0 Vector__XXX

BO_ 674 TelemetryNode_TX_PDO3: 0 TelemetryNode

BO_ 738 TelemetryNode_RX_PDO3: 0 Vector__XXX

BO_ 802 TelemetryNode_TX_PDO4: 0 TelemetryNode

BO_ 866 TelemetryNode_RX_PDO4: 0 Vector__XXX

BO_ 930 TelemetryNode_TX_PDO5: 0 TelemetryNode

BO_ 994 TelemetryNode_TX_PDO6: 0 TelemetryNode

BO_ 1058 TelemetryNode_TX_PDO7: 0 TelemetryNode

BO_ 1122 TelemetryNode_TX_PDO8: 0 TelemetryNode

BO_ 1186 TelemetryNode_TX_PDO9: 0 TelemetryNode

BO_ 1250 TelemetryNode_TX_PDO10: 0 TelemetryNode

BO_ 1314 TelemetryNode_TX_CAN_Error: 6 TelemetryNode
 SG_ TelemetryNode_CAN2_TxErrors : 38|10@1+ (1,0) [0|4095] "" Vector__XXX
 SG_ TelemetryNode_CAN2_RxErrors : 24|14@1+ (1,0) [0|16383] "" Vector__XXX
 SG_ TelemetryNode_CAN1_TxErrors : 14|10@1+ (1,0) [0|4095] "" Vector__XXX
 SG_ TelemetryNode_CAN1_RxErrors : 0|14@1+ (1,0) [0|16383] "" Vector__XXX

BO_ 1378 TelemetryNode_TX_Info: 7 TelemetryNode
 SG_ TelemetryNode_Date : 36|18@1+ (1,20200000) [20200000|20462143] "" Vector__XXX
 SG_ TelemetryNode_Time : 18|18@1+ (1,0) [0|262143] "" Vector__XXX
 SG_ TelemetryNode_Temperature : 10|8@1+ (0.4,-10) [-10|92] "Â°C" Vector__XXX
 SG_ TelemetryNode_CpuUsage : 0|10@1+ (0.1,0) [0|102.3] "%" Vector__XXX

BO_ 1442 TelemetryNode_SDO_Resp: 8 TelemetryNode
 SG_ TelemetryNode_OD_CanRestart m2050 : 16|8@1+ (1,0) [0|255] ""  TelemetryNode
 SG_ TelemetryNode_OD_Reboot m2049 : 16|8@1+ (1,0) [0|255] ""  TelemetryNode
 SG_ TelemetryNode_OD_Shutdown m2048 : 16|8@1+ (1,0) [0|255] ""  TelemetryNode
 SG_ TelemetryNode_OD_CAN2_DelayedTxM m1129 : 16|24@1+ (1,0) [0|16777215] ""  TelemetryNode
 SG_ TelemetryNode_OD_CAN2_ErrorStatu m1128 : 16|8@1+ (1,0) [0|255] ""  TelemetryNode
 SG_ TelemetryNode_OD_CAN2_DiscardedT m1127 : 16|24@1+ (1,0) [0|16777215] ""  TelemetryNode
 SG_ TelemetryNode_OD_CAN2_Status m1126 : 16|8@1+ (1,0) [0|255] ""  TelemetryNode
 SG_ TelemetryNode_OD_CAN2_Baudrate m1124 : 16|16@1+ (1,0) [125|1000] "kbps"  TelemetryNode
 SG_ TelemetryNode_OD_CAN2_autoErrorR m1123 : 16|8@1+ (1,0) [0|255] ""  TelemetryNode
 SG_ TelemetryNode_OD_CAN2_lastErrorC m1122 : 16|32@1+ (1,0) [0|4294967295] ""  TelemetryNode
 SG_ TelemetryNode_OD_CAN2_RxErrCnt m1121 : 16|8@1+ (1,0) [0|255] ""  TelemetryNode
 SG_ TelemetryNode_OD_CAN2_TxErrCnt m1120 : 16|8@1+ (1,0) [0|255] ""  TelemetryNode
 SG_ TelemetryNode_OD_CAN1_DelayedTxM m1113 : 16|24@1+ (1,0) [0|16777215] ""  TelemetryNode
 SG_ TelemetryNode_OD_CAN1_ErrorStatu m1112 : 16|8@1+ (1,0) [0|255] ""  TelemetryNode
 SG_ TelemetryNode_OD_CAN1_DiscardedT m1111 : 16|24@1+ (1,0) [0|16777215] ""  TelemetryNode
 SG_ TelemetryNode_OD_CAN1_Status m1110 : 16|8@1+ (1,0) [0|255] ""  TelemetryNode
 SG_ TelemetryNode_OD_CAN1_Baudrate m1108 : 16|16@1+ (1,0) [125|1000] "kbps"  TelemetryNode
 SG_ TelemetryNode_OD_CAN1_autoErrorR m1107 : 16|8@1+ (1,0) [0|255] ""  TelemetryNode
 SG_ TelemetryNode_OD_CAN1_lastErrorC m1106 : 16|32@1+ (1,0) [0|4294967295] ""  TelemetryNode
 SG_ TelemetryNode_OD_CAN1_RxErrCnt m1105 : 16|8@1+ (1,0) [0|255] ""  TelemetryNode
 SG_ TelemetryNode_OD_CAN1_TxErrCnt m1104 : 16|8@1+ (1,0) [0|255] ""  TelemetryNode
 SG_ TelemetryNode_OD_BuildTime m1073 : 16|24@1+ (1,0) [0|16777215] ""  TelemetryNode
 SG_ TelemetryNode_OD_BuildDate m1072 : 16|32@1+ (1,0) [0|4294967295] ""  TelemetryNode
 SG_ TelemetryNode_OD_ChipUID2 m1057 : 16|48@1+ (1,0) [0|281474976710655] ""  TelemetryNode
 SG_ TelemetryNode_OD_ChipUID1 m1056 : 16|48@1+ (1,0) [0|281474976710655] ""  TelemetryNode
 SG_ TelemetryNode_OD_SdcOut m1046 : 16|8@1+ (1,0) [0|255] ""  TelemetryNode
 SG_ TelemetryNode_OD_SdcIn m1045 : 16|8@1+ (1,0) [0|255] ""  TelemetryNode
 SG_ TelemetryNode_OD_runtime m1044 : 16|24@1+ (1,0) [0|16777215] "ms"  TelemetryNode
 SG_ TelemetryNode_OD_InputVoltage m1043 : 16|16@1+ (0.001,0) [0|65.535] "V"  TelemetryNode
 SG_ TelemetryNode_OD_BoardTemp m1042 : 16|16@1+ (0.01,-30) [-30|625.35] "°C"  TelemetryNode
 SG_ TelemetryNode_OD_MemFree m1041 : 16|16@1+ (4,0) [0|262140] "bytes"  TelemetryNode
 SG_ TelemetryNode_OD_CpuUsage m1040 : 16|8@1+ (0.5,0) [0|100] "%"  TelemetryNode
 SG_ TelemetryNode_OD_OdEntrySendInte m33 : 16|16@1+ (1,0) [0|65535] "ms"  TelemetryNode
 SG_ TelemetryNode_OD_SendOdOnBootup m32 : 16|8@1+ (1,0) [0|255] ""  TelemetryNode
 SG_ TelemetryNode_OD_HeartbeatInterv m16 : 16|16@1+ (1,0) [0|65535] "ms"  TelemetryNode
 SG_ TelemetryNode_OD_DbcVersion m5 : 16|16@1+ (1,0) [0|65535] ""  TelemetryNode
 SG_ TelemetryNode_OD_StackVersion m4 : 16|16@1+ (1,0) [0|65535] ""  TelemetryNode
 SG_ TelemetryNode_OD_ProtocolVersion m3 : 16|16@1+ (1,0) [0|65535] ""  TelemetryNode
 SG_ TelemetryNode_OD_NodeStatus m2 : 16|8@1+ (1,0) [0|255] ""  TelemetryNode
 SG_ TelemetryNode_OD_NodeID m1 : 16|8@1+ (1,0) [0|255] ""  TelemetryNode
 SG_ TelemetryNode_SDO_RespCode : 12|4@1+ (1,0) [0|0] ""  TelemetryNode
 SG_ TelemetryNode_SDO_ID M : 0|12@1+ (1,0) [0|4095] ""  TelemetryNode

BO_ 1506 TelemetryNode_SDO_Req_Up: 8 TelemetryNode
 SG_ TelemetryNode_OD_CanRestart m2050 : 16|8@1+ (1,0) [0|255] ""  TelemetryNode
 SG_ TelemetryNode_OD_Reboot m2049 : 16|8@1+ (1,0) [0|255] ""  TelemetryNode
 SG_ TelemetryNode_OD_Shutdown m2048 : 16|8@1+ (1,0) [0|255] ""  TelemetryNode
 SG_ TelemetryNode_OD_CAN2_Delay_0000 m1129 : 16|24@1+ (1,0) [0|16777215] ""  TelemetryNode
 SG_ TelemetryNode_OD_CAN2_Error_0000 m1128 : 16|8@1+ (1,0) [0|255] ""  TelemetryNode
 SG_ TelemetryNode_OD_CAN2_Disca_0000 m1127 : 16|24@1+ (1,0) [0|16777215] ""  TelemetryNode
 SG_ TelemetryNode_OD_CAN2_Status m1126 : 16|8@1+ (1,0) [0|255] ""  TelemetryNode
 SG_ TelemetryNode_OD_CAN2_Baudrate m1124 : 16|16@1+ (1,0) [125|1000] "kbps"  TelemetryNode
 SG_ TelemetryNode_OD_CAN2_autoE_0000 m1123 : 16|8@1+ (1,0) [0|255] ""  TelemetryNode
 SG_ TelemetryNode_OD_CAN2_lastE_0000 m1122 : 16|32@1+ (1,0) [0|4294967295] ""  TelemetryNode
 SG_ TelemetryNode_OD_CAN2_RxErrCnt m1121 : 16|8@1+ (1,0) [0|255] ""  TelemetryNode
 SG_ TelemetryNode_OD_CAN2_TxErrCnt m1120 : 16|8@1+ (1,0) [0|255] ""  TelemetryNode
 SG_ TelemetryNode_OD_CAN1_Delay_0000 m1113 : 16|24@1+ (1,0) [0|16777215] ""  TelemetryNode
 SG_ TelemetryNode_OD_CAN1_Error_0000 m1112 : 16|8@1+ (1,0) [0|255] ""  TelemetryNode
 SG_ TelemetryNode_OD_CAN1_Disca_0000 m1111 : 16|24@1+ (1,0) [0|16777215] ""  TelemetryNode
 SG_ TelemetryNode_OD_CAN1_Status m1110 : 16|8@1+ (1,0) [0|255] ""  TelemetryNode
 SG_ TelemetryNode_OD_CAN1_Baudrate m1108 : 16|16@1+ (1,0) [125|1000] "kbps"  TelemetryNode
 SG_ TelemetryNode_OD_CAN1_autoE_0000 m1107 : 16|8@1+ (1,0) [0|255] ""  TelemetryNode
 SG_ TelemetryNode_OD_CAN1_lastE_0000 m1106 : 16|32@1+ (1,0) [0|4294967295] ""  TelemetryNode
 SG_ TelemetryNode_OD_CAN1_RxErrCnt m1105 : 16|8@1+ (1,0) [0|255] ""  TelemetryNode
 SG_ TelemetryNode_OD_CAN1_TxErrCnt m1104 : 16|8@1+ (1,0) [0|255] ""  TelemetryNode
 SG_ TelemetryNode_OD_BuildTime m1073 : 16|24@1+ (1,0) [0|16777215] ""  TelemetryNode
 SG_ TelemetryNode_OD_BuildDate m1072 : 16|32@1+ (1,0) [0|4294967295] ""  TelemetryNode
 SG_ TelemetryNode_OD_ChipUID2 m1057 : 16|48@1+ (1,0) [0|281474976710655] ""  TelemetryNode
 SG_ TelemetryNode_OD_ChipUID1 m1056 : 16|48@1+ (1,0) [0|281474976710655] ""  TelemetryNode
 SG_ TelemetryNode_OD_SdcOut m1046 : 16|8@1+ (1,0) [0|255] ""  TelemetryNode
 SG_ TelemetryNode_OD_SdcIn m1045 : 16|8@1+ (1,0) [0|255] ""  TelemetryNode
 SG_ TelemetryNode_OD_runtime m1044 : 16|24@1+ (1,0) [0|16777215] "ms"  TelemetryNode
 SG_ TelemetryNode_OD_InputVoltage m1043 : 16|16@1+ (0.001,0) [0|65.535] "V"  TelemetryNode
 SG_ TelemetryNode_OD_BoardTemp m1042 : 16|16@1+ (0.01,-30) [-30|625.35] "°C"  TelemetryNode
 SG_ TelemetryNode_OD_MemFree m1041 : 16|16@1+ (4,0) [0|262140] "bytes"  TelemetryNode
 SG_ TelemetryNode_OD_CpuUsage m1040 : 16|8@1+ (0.5,0) [0|100] "%"  TelemetryNode
 SG_ TelemetryNode_OD_OdEntrySen_0000 m33 : 16|16@1+ (1,0) [0|65535] "ms"  TelemetryNode
 SG_ TelemetryNode_OD_SendOdOnBootup m32 : 16|8@1+ (1,0) [0|255] ""  TelemetryNode
 SG_ TelemetryNode_OD_HeartbeatI_0000 m16 : 16|16@1+ (1,0) [0|65535] "ms"  TelemetryNode
 SG_ TelemetryNode_OD_DbcVersion m5 : 16|16@1+ (1,0) [0|65535] ""  TelemetryNode
 SG_ TelemetryNode_OD_StackVersion m4 : 16|16@1+ (1,0) [0|65535] ""  TelemetryNode
 SG_ TelemetryNode_OD_ProtocolVersion m3 : 16|16@1+ (1,0) [0|65535] ""  TelemetryNode
 SG_ TelemetryNode_OD_NodeStatus m2 : 16|8@1+ (1,0) [0|255] ""  TelemetryNode
 SG_ TelemetryNode_OD_NodeID m1 : 16|8@1+ (1,0) [0|255] ""  TelemetryNode
 SG_ TelemetryNode_SDO_ID M : 0|12@1+ (1,0) [0|4095] ""  TelemetryNode

BO_ 1570 TelemetryNode_SDO_Req_Down: 2 TelemetryNode
 SG_ TelemetryNode_SDO_ID M : 0|12@1+ (1,0) [0|4095] ""  TelemetryNode

BO_ 1826 TelemetryNode_Heartbeat: 1 TelemetryNode
 SG_ TelemetryNode_NodeState : 0|8@1+ (1,0) [0|0] ""  SensorF,Master,TelemetryNode

BO_ 1890 TelemetryNode_BTL_TX: 8 TelemetryNode

BO_ 1954 TelemetryNode_BTL_RX: 8 TelemetryNode

CM_ BO_ 1482 "DO NOT CHANGE ANYTHING HERE!
SDO Request Upload to node HVCU with Node-ID 0xA";
CM_ SG_ 1482 HVCU_OD_CAN2_DelayedTxMessages "Number of delayed TX messages on CAN2 because no messagebox was free.";
CM_ SG_ 1482 HVCU_OD_CAN2_ErrorStatus "Internal error status (e.g. Error active, Error passive, Bus Off)";
CM_ SG_ 1482 HVCU_OD_CAN2_DiscardedTxMessages "Number of discarded TX messages on CAN2 because all messageboxes were full";
CM_ SG_ 1482 HVCU_OD_CAN2_Status "Status of CAN2.";
CM_ SG_ 1482 HVCU_OD_CAN2_Baudrate "Baudrate of CAN.";
CM_ SG_ 1482 HVCU_OD_CAN2_autoErrorReset "Automatic reset of errors.";
CM_ SG_ 1482 HVCU_OD_CAN2_lastErrorCode "Last error code.";
CM_ SG_ 1482 HVCU_OD_CAN2_RxErrCnt "Receive error count of CAN1.";
CM_ SG_ 1482 HVCU_OD_CAN2_TxErrCnt "Transmit error count of CAN1.";
CM_ SG_ 1482 HVCU_OD_CAN1_DelayedTxMessages "Number of delayed TX messages on CAN1 because no messagebox was free.";
CM_ SG_ 1482 HVCU_OD_CAN1_ErrorStatus "Internal error status (e.g. Error active, Error passive, Bus Off)";
CM_ SG_ 1482 HVCU_OD_CAN1_DiscardedTxMessages "Number of discarded TX messages on CAN1 because all messageboxes were full";
CM_ SG_ 1482 HVCU_OD_CAN1_Status "Status of CAN1.";
CM_ SG_ 1482 HVCU_OD_CAN1_Baudrate "Baudrate of CAN.";
CM_ SG_ 1482 HVCU_OD_CAN1_autoErrorReset "Automatic reset of errors.";
CM_ SG_ 1482 HVCU_OD_CAN1_lastErrorCode "Last error code.";
CM_ SG_ 1482 HVCU_OD_CAN1_RxErrCnt "Receive error count of CAN1.";
CM_ SG_ 1482 HVCU_OD_CAN1_TxErrCnt "Transmit error count of CAN1.";
CM_ SG_ 1482 HVCU_OD_BuildTime "Software build time in the format HHMMSS.";
CM_ SG_ 1482 HVCU_OD_BuildDate "Software build date in the format YYYYMMDD.";
CM_ SG_ 1482 HVCU_OD_ChipUID2 "Seccond part of unique ID of microcontroller.";
CM_ SG_ 1482 HVCU_OD_ChipUID1 "First part of unique ID of microcontroller.";
CM_ SG_ 1482 HVCU_OD_SdcOut "Measurement of Shutdown Circuit Output";
CM_ SG_ 1482 HVCU_OD_SdcIn "Measurement of Shutdown Circuit Input";
CM_ SG_ 1482 HVCU_OD_runtime "Runtime of chip in milliseconds.";
CM_ SG_ 1482 HVCU_OD_InputVoltage "Board supply voltage.";
CM_ SG_ 1482 HVCU_OD_BoardTemp "Temperature of board";
CM_ SG_ 1482 HVCU_OD_MemFree "Free memory in bytes.";
CM_ SG_ 1482 HVCU_OD_CpuUsage "Current CPU usage in %.";
CM_ SG_ 1482 HVCU_OD_OdEntrySendInterval "Interval for sending all readable OD entries. Sending is disabled if less than 5 ms.";
CM_ SG_ 1482 HVCU_OD_SendOdOnBootup "Whether to send all OD entries on bootup.";
CM_ SG_ 1482 HVCU_OD_HeartbeatInterval "Heartbeat Interval in milliseconds.";
CM_ SG_ 1482 HVCU_OD_DbcVersion "CANzero DBC version.";
CM_ SG_ 1482 HVCU_OD_StackVersion "CANzero stack version.";
CM_ SG_ 1482 HVCU_OD_ProtocolVersion "CANzero Protocol Version.";
CM_ SG_ 1482 HVCU_OD_NodeStatus "State of the node.";
CM_ SG_ 1482 HVCU_OD_NodeID "CANzero Node-ID.";
CM_ SG_ 1482 HVCU_SDO_ID "Specifies SDO-ID of HVCU";
CM_ BO_ 1546 "DO NOT CHANGE ANYTHING HERE!
SDO Request Download from node HVCU with Node-ID 0xA";
CM_ SG_ 1546 HVCU_SDO_ID "Specifies SDO-ID of HVCU";
CM_ BO_ 1802 "Heartbeat of node HVCU with Node-ID 0xA";
CM_ SG_ 1802 HVCU_NodeState "Heartbeat status of node HVCU";
CM_ BO_ 1866 "Bootloader transmit from node HVCU with Node-ID 0xA";
CM_ BO_ 1930 "Bootloader receive by node HVCU with Node-ID 0xA";
CM_ BO_ 153 "Emergency message of node HVTU with Node-ID 0x19";
CM_ SG_ 153 HVTU_E0_OtherError "Other error.";
CM_ SG_ 153 HVTU_W0_OtherWarning "Other warning.";
CM_ BO_ 1299 "Control signals to control the SciMo PE with the mz control model implemented on the SciMo hardware (Vf and If control).

";
CM_ BO_ 409 "Transmit PDO 1 of node HVTU with Node-ID 0x19";
CM_ BO_ 473 "Receive PDO 1 of node HVTU with Node-ID 0x19";
CM_ BO_ 537 "Transmit PDO 2 of node HVTU with Node-ID 0x19";
CM_ BO_ 601 "Receive PDO 2 of node HVTU with Node-ID 0x19";
CM_ BO_ 665 "Transmit PDO 3 of node HVTU with Node-ID 0x19";
CM_ BO_ 729 "Receive PDO 3 of node HVTU with Node-ID 0x19";
CM_ BO_ 793 "Transmit PDO 4 of node HVTU with Node-ID 0x19";
CM_ BO_ 857 "Receive PDO 4 of node HVTU with Node-ID 0x19";
CM_ BO_ 921 "Transmit PDO 5 of node HVTU with Node-ID 0x19";
CM_ BO_ 985 "Transmit PDO 6 of node HVTU with Node-ID 0x19";
CM_ BO_ 1049 "Transmit PDO 7 of node HVTU with Node-ID 0x19";
CM_ BO_ 1113 "Transmit PDO 8 of node HVTU with Node-ID 0x19";
CM_ BO_ 1177 "Transmit PDO 9 of node HVTU with Node-ID 0x19";
CM_ BO_ 1241 "Transmit PDO 10 of node HVTU with Node-ID 0x19";
CM_ BO_ 1305 "Transmit PDO 11 of node HVTU with Node-ID 0x19";
CM_ BO_ 1369 "Transmit PDO 12 of node HVTU with Node-ID 0x19";
CM_ BO_ 1433 "DO NOT CHANGE ANYTHING HERE!
SDO Response of node HVTU with Node-ID 0x19";
CM_ SG_ 1433 HVTU_OD_CAN2_DelayedTxMessages "Number of delayed TX messages on CAN2 because no messagebox was free.";
CM_ SG_ 1433 HVTU_OD_CAN2_ErrorStatus "Internal error status (e.g. Error active, Error passive, Bus Off)";
CM_ SG_ 1433 HVTU_OD_CAN2_DiscardedTxMessages "Number of discarded TX messages on CAN2 because all messageboxes were full";
CM_ SG_ 1433 HVTU_OD_CAN2_Status "Status of CAN2.";
CM_ SG_ 1433 HVTU_OD_CAN2_Baudrate "Baudrate of CAN.";
CM_ SG_ 1433 HVTU_OD_CAN2_autoErrorReset "Automatic reset of errors.";
CM_ SG_ 1433 HVTU_OD_CAN2_lastErrorCode "Last error code.";
CM_ SG_ 1433 HVTU_OD_CAN2_RxErrCnt "Receive error count of CAN1.";
CM_ SG_ 1433 HVTU_OD_CAN2_TxErrCnt "Transmit error count of CAN1.";
CM_ SG_ 1433 HVTU_OD_CAN1_DelayedTxMessages "Number of delayed TX messages on CAN1 because no messagebox was free.";
CM_ SG_ 1433 HVTU_OD_CAN1_ErrorStatus "Internal error status (e.g. Error active, Error passive, Bus Off)";
CM_ SG_ 1433 HVTU_OD_CAN1_DiscardedTxMessages "Number of discarded TX messages on CAN1 because all messageboxes were full";
CM_ SG_ 1433 HVTU_OD_CAN1_Status "Status of CAN1.";
CM_ SG_ 1433 HVTU_OD_CAN1_Baudrate "Baudrate of CAN.";
CM_ SG_ 1433 HVTU_OD_CAN1_autoErrorReset "Automatic reset of errors.";
CM_ SG_ 1433 HVTU_OD_CAN1_lastErrorCode "Last error code.";
CM_ SG_ 1433 HVTU_OD_CAN1_RxErrCnt "Receive error count of CAN1.";
CM_ SG_ 1433 HVTU_OD_CAN1_TxErrCnt "Transmit error count of CAN1.";
CM_ SG_ 1433 HVTU_OD_BuildTime "Software build time in the format HHMMSS.";
CM_ SG_ 1433 HVTU_OD_BuildDate "Software build date in the format YYYYMMDD.";
CM_ SG_ 1433 HVTU_OD_ChipUID2 "Seccond part of unique ID of microcontroller.";
CM_ SG_ 1433 HVTU_OD_ChipUID1 "First part of unique ID of microcontroller.";
CM_ SG_ 1433 HVTU_OD_SdcOut "Measurement of Shutdown Circuit Output";
CM_ SG_ 1433 HVTU_OD_SdcIn "Measurement of Shutdown Circuit Input";
CM_ SG_ 1433 HVTU_OD_runtime "Runtime of chip in milliseconds.";
CM_ SG_ 1433 HVTU_OD_InputVoltage "Board supply voltage.";
CM_ SG_ 1433 HVTU_OD_BoardTemp "Temperature of board";
CM_ SG_ 1433 HVTU_OD_MemFree "Free memory in bytes.";
CM_ SG_ 1433 HVTU_OD_CpuUsage "Current CPU usage in %.";
CM_ SG_ 1433 HVTU_OD_OdEntrySendInterval "Interval for sending all readable OD entries. Sending is disabled if less than 5 ms.";
CM_ SG_ 1433 HVTU_OD_SendOdOnBootup "Whether to send all OD entries on bootup.";
CM_ SG_ 1433 HVTU_OD_HeartbeatInterval "Heartbeat Interval in milliseconds.";
CM_ SG_ 1433 HVTU_OD_DbcVersion "CANzero DBC version.";
CM_ SG_ 1433 HVTU_OD_StackVersion "CANzero stack version.";
CM_ SG_ 1433 HVTU_OD_ProtocolVersion "CANzero Protocol Version.";
CM_ SG_ 1433 HVTU_OD_NodeStatus "State of the node.";
CM_ SG_ 1433 HVTU_OD_NodeID "CANzero Node-ID.";
CM_ SG_ 1433 HVTU_SDO_RespCode "Response code of SDO access.";
CM_ SG_ 1433 HVTU_SDO_ID "Specifies SDO-ID of HVTU";
CM_ BO_ 1497 "DO NOT CHANGE ANYTHING HERE!
SDO Request Upload to node HVTU with Node-ID 0x19";
CM_ SG_ 1497 HVTU_OD_CAN2_DelayedTxMessages "Number of delayed TX messages on CAN2 because no messagebox was free.";
CM_ SG_ 1497 HVTU_OD_CAN2_ErrorStatus "Internal error status (e.g. Error active, Error passive, Bus Off)";
CM_ SG_ 1497 HVTU_OD_CAN2_DiscardedTxMessages "Number of discarded TX messages on CAN2 because all messageboxes were full";
CM_ SG_ 1497 HVTU_OD_CAN2_Status "Status of CAN2.";
CM_ SG_ 1497 HVTU_OD_CAN2_Baudrate "Baudrate of CAN.";
CM_ SG_ 1497 HVTU_OD_CAN2_autoErrorReset "Automatic reset of errors.";
CM_ SG_ 1497 HVTU_OD_CAN2_lastErrorCode "Last error code.";
CM_ SG_ 1497 HVTU_OD_CAN2_RxErrCnt "Receive error count of CAN1.";
CM_ SG_ 1497 HVTU_OD_CAN2_TxErrCnt "Transmit error count of CAN1.";
CM_ SG_ 1497 HVTU_OD_CAN1_DelayedTxMessages "Number of delayed TX messages on CAN1 because no messagebox was free.";
CM_ SG_ 1497 HVTU_OD_CAN1_ErrorStatus "Internal error status (e.g. Error active, Error passive, Bus Off)";
CM_ SG_ 1497 HVTU_OD_CAN1_DiscardedTxMessages "Number of discarded TX messages on CAN1 because all messageboxes were full";
CM_ SG_ 1497 HVTU_OD_CAN1_Status "Status of CAN1.";
CM_ SG_ 1497 HVTU_OD_CAN1_Baudrate "Baudrate of CAN.";
CM_ SG_ 1497 HVTU_OD_CAN1_autoErrorReset "Automatic reset of errors.";
CM_ SG_ 1497 HVTU_OD_CAN1_lastErrorCode "Last error code.";
CM_ SG_ 1497 HVTU_OD_CAN1_RxErrCnt "Receive error count of CAN1.";
CM_ SG_ 1497 HVTU_OD_CAN1_TxErrCnt "Transmit error count of CAN1.";
CM_ SG_ 1497 HVTU_OD_BuildTime "Software build time in the format HHMMSS.";
CM_ SG_ 1497 HVTU_OD_BuildDate "Software build date in the format YYYYMMDD.";
CM_ SG_ 1497 HVTU_OD_ChipUID2 "Seccond part of unique ID of microcontroller.";
CM_ SG_ 1497 HVTU_OD_ChipUID1 "First part of unique ID of microcontroller.";
CM_ SG_ 1497 HVTU_OD_SdcOut "Measurement of Shutdown Circuit Output";
CM_ SG_ 1497 HVTU_OD_SdcIn "Measurement of Shutdown Circuit Input";
CM_ SG_ 1497 HVTU_OD_runtime "Runtime of chip in milliseconds.";
CM_ SG_ 1497 HVTU_OD_InputVoltage "Board supply voltage.";
CM_ SG_ 1497 HVTU_OD_BoardTemp "Temperature of board";
CM_ SG_ 1497 HVTU_OD_MemFree "Free memory in bytes.";
CM_ SG_ 1497 HVTU_OD_CpuUsage "Current CPU usage in %.";
CM_ SG_ 1497 HVTU_OD_OdEntrySendInterval "Interval for sending all readable OD entries. Sending is disabled if less than 5 ms.";
CM_ SG_ 1497 HVTU_OD_SendOdOnBootup "Whether to send all OD entries on bootup.";
CM_ SG_ 1497 HVTU_OD_HeartbeatInterval "Heartbeat Interval in milliseconds.";
CM_ SG_ 1497 HVTU_OD_DbcVersion "CANzero DBC version.";
CM_ SG_ 1497 HVTU_OD_StackVersion "CANzero stack version.";
CM_ SG_ 1497 HVTU_OD_ProtocolVersion "CANzero Protocol Version.";
CM_ SG_ 1497 HVTU_OD_NodeStatus "State of the node.";
CM_ SG_ 1497 HVTU_OD_NodeID "CANzero Node-ID.";
CM_ SG_ 1497 HVTU_SDO_ID "Specifies SDO-ID of HVTU";
CM_ BO_ 1561 "DO NOT CHANGE ANYTHING HERE!
SDO Request Download from node HVTU with Node-ID 0x19";
CM_ SG_ 1561 HVTU_SDO_ID "Specifies SDO-ID of HVTU";
CM_ BO_ 1817 "Heartbeat of node HVTU with Node-ID 0x19";
CM_ SG_ 1817 HVTU_NodeState "Heartbeat status of node HVTU";
CM_ BO_ 1881 "Bootloader transmit from node HVTU with Node-ID 0x19";
CM_ BO_ 1945 "Bootloader receive by node HVTU with Node-ID 0x19";
CM_ BO_ 162 "Emergency message of node TelemetryNode with Node-ID 0x22";
CM_ SG_ 162 TelemetryNode_E0_OtherError "Other error.";
CM_ SG_ 162 TelemetryNode_W0_OtherWarning "Other warning.";
CM_ BO_ 418 "Transmit PDO 1 of node TelemetryNode with Node-ID 0x22";
CM_ BO_ 482 "Receive PDO 1 of node TelemetryNode with Node-ID 0x22";
CM_ BO_ 546 "Transmit PDO 2 of node TelemetryNode with Node-ID 0x22";
CM_ BO_ 610 "Receive PDO 2 of node TelemetryNode with Node-ID 0x22";
CM_ BO_ 674 "Transmit PDO 3 of node TelemetryNode with Node-ID 0x22";
CM_ BO_ 738 "Receive PDO 3 of node TelemetryNode with Node-ID 0x22";
CM_ BO_ 802 "Transmit PDO 4 of node TelemetryNode with Node-ID 0x22";
CM_ BO_ 866 "Receive PDO 4 of node TelemetryNode with Node-ID 0x22";
CM_ BO_ 930 "Transmit PDO 5 of node TelemetryNode with Node-ID 0x22";
CM_ BO_ 994 "Transmit PDO 6 of node TelemetryNode with Node-ID 0x22";
CM_ BO_ 1058 "Transmit PDO 7 of node TelemetryNode with Node-ID 0x22";
CM_ BO_ 1122 "Transmit PDO 8 of node TelemetryNode with Node-ID 0x22";
CM_ BO_ 1186 "Transmit PDO 9 of node TelemetryNode with Node-ID 0x22";
CM_ BO_ 1250 "Transmit PDO 10 of node TelemetryNode with Node-ID 0x22";
CM_ BO_ 1314 "Transmit PDO 11 of node TelemetryNode with Node-ID 0x22";
CM_ BO_ 1378 "Transmit PDO 12 of node TelemetryNode with Node-ID 0x22";
CM_ BO_ 1442 "DO NOT CHANGE ANYTHING HERE!
SDO Response of node TelemetryNode with Node-ID 0x22";
CM_ SG_ 1442 TelemetryNode_OD_CanRestart "Restart CAN interfaces.";
CM_ SG_ 1442 TelemetryNode_OD_Reboot "Reboot the Telemetry Node.";
CM_ SG_ 1442 TelemetryNode_OD_Shutdown "Shutdown the Telemetry Node.";
CM_ SG_ 1442 TelemetryNode_OD_CAN2_DelayedTxM "Number of delayed TX messages on CAN2 because no messagebox was free.";
CM_ SG_ 1442 TelemetryNode_OD_CAN2_ErrorStatu "Internal error status (e.g. Error active, Error passive, Bus Off)";
CM_ SG_ 1442 TelemetryNode_OD_CAN2_DiscardedT "Number of discarded TX messages on CAN2 because all messageboxes were full";
CM_ SG_ 1442 TelemetryNode_OD_CAN2_Status "Status of CAN2.";
CM_ SG_ 1442 TelemetryNode_OD_CAN2_Baudrate "Baudrate of CAN.";
CM_ SG_ 1442 TelemetryNode_OD_CAN2_autoErrorR "Automatic reset of errors.";
CM_ SG_ 1442 TelemetryNode_OD_CAN2_lastErrorC "Last error code.";
CM_ SG_ 1442 TelemetryNode_OD_CAN2_RxErrCnt "Receive error count of CAN1.";
CM_ SG_ 1442 TelemetryNode_OD_CAN2_TxErrCnt "Transmit error count of CAN1.";
CM_ SG_ 1442 TelemetryNode_OD_CAN1_DelayedTxM "Number of delayed TX messages on CAN1 because no messagebox was free.";
CM_ SG_ 1442 TelemetryNode_OD_CAN1_ErrorStatu "Internal error status (e.g. Error active, Error passive, Bus Off)";
CM_ SG_ 1442 TelemetryNode_OD_CAN1_DiscardedT "Number of discarded TX messages on CAN1 because all messageboxes were full";
CM_ SG_ 1442 TelemetryNode_OD_CAN1_Status "Status of CAN1.";
CM_ SG_ 1442 TelemetryNode_OD_CAN1_Baudrate "Baudrate of CAN.";
CM_ SG_ 1442 TelemetryNode_OD_CAN1_autoErrorR "Automatic reset of errors.";
CM_ SG_ 1442 TelemetryNode_OD_CAN1_lastErrorC "Last error code.";
CM_ SG_ 1442 TelemetryNode_OD_CAN1_RxErrCnt "Receive error count of CAN1.";
CM_ SG_ 1442 TelemetryNode_OD_CAN1_TxErrCnt "Transmit error count of CAN1.";
CM_ SG_ 1442 TelemetryNode_OD_BuildTime "Software build time in the format HHMMSS.";
CM_ SG_ 1442 TelemetryNode_OD_BuildDate "Software build date in the format YYYYMMDD.";
CM_ SG_ 1442 TelemetryNode_OD_ChipUID2 "Seccond part of unique ID of microcontroller.";
CM_ SG_ 1442 TelemetryNode_OD_ChipUID1 "First part of unique ID of microcontroller.";
CM_ SG_ 1442 TelemetryNode_OD_SdcOut "Measurement of Shutdown Circuit Output";
CM_ SG_ 1442 TelemetryNode_OD_SdcIn "Measurement of Shutdown Circuit Input";
CM_ SG_ 1442 TelemetryNode_OD_runtime "Runtime of chip in milliseconds.";
CM_ SG_ 1442 TelemetryNode_OD_InputVoltage "Board supply voltage.";
CM_ SG_ 1442 TelemetryNode_OD_BoardTemp "Temperature of board";
CM_ SG_ 1442 TelemetryNode_OD_MemFree "Free memory in bytes.";
CM_ SG_ 1442 TelemetryNode_OD_CpuUsage "Current CPU usage in %.";
CM_ SG_ 1442 TelemetryNode_OD_OdEntrySendInte "Interval for sending all readable OD entries. Sending is disabled if less than 5 ms.";
CM_ SG_ 1442 TelemetryNode_OD_SendOdOnBootup "Whether to send all OD entries on bootup.";
CM_ SG_ 1442 TelemetryNode_OD_HeartbeatInterv "Heartbeat Interval in milliseconds.";
CM_ SG_ 1442 TelemetryNode_OD_DbcVersion "CANzero DBC version.";
CM_ SG_ 1442 TelemetryNode_OD_StackVersion "CANzero stack version.";
CM_ SG_ 1442 TelemetryNode_OD_ProtocolVersion "CANzero Protocol Version.";
CM_ SG_ 1442 TelemetryNode_OD_NodeStatus "State of the node.";
CM_ SG_ 1442 TelemetryNode_OD_NodeID "CANzero Node-ID.";
CM_ SG_ 1442 TelemetryNode_SDO_RespCode "Response code of SDO access.";
CM_ SG_ 1442 TelemetryNode_SDO_ID "Specifies SDO-ID of TelemetryNode";
CM_ BO_ 1506 "DO NOT CHANGE ANYTHING HERE!
SDO Request Upload to node TelemetryNode with Node-ID 0x22";
CM_ SG_ 1506 TelemetryNode_OD_CanRestart "Restart CAN interfaces.";
CM_ SG_ 1506 TelemetryNode_OD_Reboot "Reboot the Telemetry Node.";
CM_ SG_ 1506 TelemetryNode_OD_Shutdown "Shutdown the Telemetry Node.";
CM_ SG_ 1506 TelemetryNode_OD_CAN2_Delay_0000 "Number of delayed TX messages on CAN2 because no messagebox was free.";
CM_ SG_ 1506 TelemetryNode_OD_CAN2_Error_0000 "Internal error status (e.g. Error active, Error passive, Bus Off)";
CM_ SG_ 1506 TelemetryNode_OD_CAN2_Disca_0000 "Number of discarded TX messages on CAN2 because all messageboxes were full";
CM_ SG_ 1506 TelemetryNode_OD_CAN2_Status "Status of CAN2.";
CM_ SG_ 1506 TelemetryNode_OD_CAN2_Baudrate "Baudrate of CAN.";
CM_ SG_ 1506 TelemetryNode_OD_CAN2_autoE_0000 "Automatic reset of errors.";
CM_ SG_ 1506 TelemetryNode_OD_CAN2_lastE_0000 "Last error code.";
CM_ SG_ 1506 TelemetryNode_OD_CAN2_RxErrCnt "Receive error count of CAN1.";
CM_ SG_ 1506 TelemetryNode_OD_CAN2_TxErrCnt "Transmit error count of CAN1.";
CM_ SG_ 1506 TelemetryNode_OD_CAN1_Delay_0000 "Number of delayed TX messages on CAN1 because no messagebox was free.";
CM_ SG_ 1506 TelemetryNode_OD_CAN1_Error_0000 "Internal error status (e.g. Error active, Error passive, Bus Off)";
CM_ SG_ 1506 TelemetryNode_OD_CAN1_Disca_0000 "Number of discarded TX messages on CAN1 because all messageboxes were full";
CM_ SG_ 1506 TelemetryNode_OD_CAN1_Status "Status of CAN1.";
CM_ SG_ 1506 TelemetryNode_OD_CAN1_Baudrate "Baudrate of CAN.";
CM_ SG_ 1506 TelemetryNode_OD_CAN1_autoE_0000 "Automatic reset of errors.";
CM_ SG_ 1506 TelemetryNode_OD_CAN1_lastE_0000 "Last error code.";
CM_ SG_ 1506 TelemetryNode_OD_CAN1_RxErrCnt "Receive error count of CAN1.";
CM_ SG_ 1506 TelemetryNode_OD_CAN1_TxErrCnt "Transmit error count of CAN1.";
CM_ SG_ 1506 TelemetryNode_OD_BuildTime "Software build time in the format HHMMSS.";
CM_ SG_ 1506 TelemetryNode_OD_BuildDate "Software build date in the format YYYYMMDD.";
CM_ SG_ 1506 TelemetryNode_OD_ChipUID2 "Seccond part of unique ID of microcontroller.";
CM_ SG_ 1506 TelemetryNode_OD_ChipUID1 "First part of unique ID of microcontroller.";
CM_ SG_ 1506 TelemetryNode_OD_SdcOut "Measurement of Shutdown Circuit Output";
CM_ SG_ 1506 TelemetryNode_OD_SdcIn "Measurement of Shutdown Circuit Input";
CM_ SG_ 1506 TelemetryNode_OD_runtime "Runtime of chip in milliseconds.";
CM_ SG_ 1506 TelemetryNode_OD_InputVoltage "Board supply voltage.";
CM_ SG_ 1506 TelemetryNode_OD_BoardTemp "Temperature of board";
CM_ SG_ 1506 TelemetryNode_OD_MemFree "Free memory in bytes.";
CM_ SG_ 1506 TelemetryNode_OD_CpuUsage "Current CPU usage in %.";
CM_ SG_ 1506 TelemetryNode_OD_OdEntrySen_0000 "Interval for sending all readable OD entries. Sending is disabled if less than 5 ms.";
CM_ SG_ 1506 TelemetryNode_OD_SendOdOnBootup "Whether to send all OD entries on bootup.";
CM_ SG_ 1506 TelemetryNode_OD_HeartbeatI_0000 "Heartbeat Interval in milliseconds.";
CM_ SG_ 1506 TelemetryNode_OD_DbcVersion "CANzero DBC version.";
CM_ SG_ 1506 TelemetryNode_OD_StackVersion "CANzero stack version.";
CM_ SG_ 1506 TelemetryNode_OD_ProtocolVersion "CANzero Protocol Version.";
CM_ SG_ 1506 TelemetryNode_OD_NodeStatus "State of the node.";
CM_ SG_ 1506 TelemetryNode_OD_NodeID "CANzero Node-ID.";
CM_ SG_ 1506 TelemetryNode_SDO_ID "Specifies SDO-ID of TelemetryNode";
CM_ BO_ 1570 "DO NOT CHANGE ANYTHING HERE!
SDO Request Download from node TelemetryNode with Node-ID 0x22";
CM_ SG_ 1570 TelemetryNode_SDO_ID "Specifies SDO-ID of TelemetryNode";
CM_ BO_ 1826 "Heartbeat of node TelemetryNode with Node-ID 0x22";
CM_ SG_ 1826 TelemetryNode_NodeState "Heartbeat status of node TelemetryNode";
CM_ BO_ 1890 "Bootloader transmit from node TelemetryNode with Node-ID 0x22";
CM_ BO_ 1954 "Bootloader receive by node TelemetryNode with Node-ID 0x22";
BA_DEF_ SG_  "GenSigSendType" ENUM  "Cyclic","OnWrite","OnWriteWithRepetition","OnChange","OnChangeWithRepetition","IfActive","IfActiveWithRepetition","NoSigSendType";
BA_DEF_ BO_  "GenMsgSendType" ENUM  "Cyclic","not_used","not_used","not_used","not_used","Cyclic","not_used","IfActive","NoMsgSendType";
BA_DEF_ BO_  "GenMsgCycleTime" INT 2 50000;
BA_DEF_ BO_  "GenMsgDelayTime" INT 1 1000;
BA_DEF_ BO_  "GenMsgNrOfRepetitions" INT 1 999999;
BA_DEF_ SG_  "GenSigStartValue" FLOAT 0 100000000000;
BA_DEF_ SG_  "CANzero_SDO_Group" STRING ;
BA_DEF_ SG_  "CANzero_SDO_AccessIfOperational" ENUM  "No","Yes";
BA_DEF_ SG_  "CANzero_SDO_AccessType" ENUM  "Read Write","Read Only","Write Only";
BA_DEF_ SG_  "CANzero_SDO_Default" FLOAT 0 0;
BA_DEF_ SG_  "SystemSignalLongSymbol" STRING ;
BA_DEF_DEF_  "GenSigSendType" "Cyclic";
BA_DEF_DEF_  "GenMsgSendType" "NoMsgSendType";
BA_DEF_DEF_  "GenMsgCycleTime" 100;
BA_DEF_DEF_  "GenMsgDelayTime" 1;
BA_DEF_DEF_  "GenMsgNrOfRepetitions" 1;
BA_DEF_DEF_  "GenSigStartValue" 0;
BA_DEF_DEF_  "CANzero_SDO_Group" "";
BA_DEF_DEF_  "CANzero_SDO_AccessIfOperational" "No";
BA_DEF_DEF_  "CANzero_SDO_AccessType" "Read Write";
BA_DEF_DEF_  "CANzero_SDO_Default" 0;
BA_DEF_DEF_  "SystemSignalLongSymbol" "";
BA_ "CANzero_SDO_Group" SG_ 1482 HVCU_OD_CAN2_DelayedTxMessages "CAN";
BA_ "CANzero_SDO_AccessType" SG_ 1482 HVCU_OD_CAN2_DelayedTxMessages 1;
BA_ "CANzero_SDO_AccessIfOperational" SG_ 1482 HVCU_OD_CAN2_DelayedTxMessages 1;
BA_ "CANzero_SDO_Group" SG_ 1482 HVCU_OD_CAN2_ErrorStatus "CAN";
BA_ "CANzero_SDO_AccessType" SG_ 1482 HVCU_OD_CAN2_ErrorStatus 1;
BA_ "CANzero_SDO_AccessIfOperational" SG_ 1482 HVCU_OD_CAN2_ErrorStatus 1;
BA_ "CANzero_SDO_Group" SG_ 1482 HVCU_OD_CAN2_DiscardedTxMessages "CAN";
BA_ "CANzero_SDO_AccessType" SG_ 1482 HVCU_OD_CAN2_DiscardedTxMessages 1;
BA_ "CANzero_SDO_AccessIfOperational" SG_ 1482 HVCU_OD_CAN2_DiscardedTxMessages 1;
BA_ "CANzero_SDO_Group" SG_ 1482 HVCU_OD_CAN2_Status "CAN";
BA_ "CANzero_SDO_AccessType" SG_ 1482 HVCU_OD_CAN2_Status 1;
BA_ "CANzero_SDO_AccessIfOperational" SG_ 1482 HVCU_OD_CAN2_Status 1;
BA_ "CANzero_SDO_Group" SG_ 1482 HVCU_OD_CAN2_Baudrate "CAN";
BA_ "CANzero_SDO_AccessIfOperational" SG_ 1482 HVCU_OD_CAN2_Baudrate 1;
BA_ "GenSigStartValue" SG_ 1482 HVCU_OD_CAN2_Baudrate 1000.0;
BA_ "CANzero_SDO_Default" SG_ 1482 HVCU_OD_CAN2_Baudrate 1000;
BA_ "CANzero_SDO_Group" SG_ 1482 HVCU_OD_CAN2_autoErrorReset "CAN";
BA_ "CANzero_SDO_AccessIfOperational" SG_ 1482 HVCU_OD_CAN2_autoErrorReset 1;
BA_ "GenSigStartValue" SG_ 1482 HVCU_OD_CAN2_autoErrorReset 1.0;
BA_ "CANzero_SDO_Default" SG_ 1482 HVCU_OD_CAN2_autoErrorReset 1;
BA_ "CANzero_SDO_Group" SG_ 1482 HVCU_OD_CAN2_lastErrorCode "CAN";
BA_ "CANzero_SDO_AccessType" SG_ 1482 HVCU_OD_CAN2_lastErrorCode 1;
BA_ "CANzero_SDO_AccessIfOperational" SG_ 1482 HVCU_OD_CAN2_lastErrorCode 1;
BA_ "CANzero_SDO_Group" SG_ 1482 HVCU_OD_CAN2_RxErrCnt "CAN";
BA_ "CANzero_SDO_AccessType" SG_ 1482 HVCU_OD_CAN2_RxErrCnt 1;
BA_ "CANzero_SDO_AccessIfOperational" SG_ 1482 HVCU_OD_CAN2_RxErrCnt 1;
BA_ "CANzero_SDO_Group" SG_ 1482 HVCU_OD_CAN2_TxErrCnt "CAN";
BA_ "CANzero_SDO_AccessType" SG_ 1482 HVCU_OD_CAN2_TxErrCnt 1;
BA_ "CANzero_SDO_AccessIfOperational" SG_ 1482 HVCU_OD_CAN2_TxErrCnt 1;
BA_ "CANzero_SDO_Group" SG_ 1482 HVCU_OD_CAN1_DelayedTxMessages "CAN";
BA_ "CANzero_SDO_AccessType" SG_ 1482 HVCU_OD_CAN1_DelayedTxMessages 1;
BA_ "CANzero_SDO_AccessIfOperational" SG_ 1482 HVCU_OD_CAN1_DelayedTxMessages 1;
BA_ "CANzero_SDO_Group" SG_ 1482 HVCU_OD_CAN1_ErrorStatus "CAN";
BA_ "CANzero_SDO_AccessType" SG_ 1482 HVCU_OD_CAN1_ErrorStatus 1;
BA_ "CANzero_SDO_AccessIfOperational" SG_ 1482 HVCU_OD_CAN1_ErrorStatus 1;
BA_ "CANzero_SDO_Group" SG_ 1482 HVCU_OD_CAN1_DiscardedTxMessages "CAN";
BA_ "CANzero_SDO_AccessType" SG_ 1482 HVCU_OD_CAN1_DiscardedTxMessages 1;
BA_ "CANzero_SDO_AccessIfOperational" SG_ 1482 HVCU_OD_CAN1_DiscardedTxMessages 1;
BA_ "CANzero_SDO_Group" SG_ 1482 HVCU_OD_CAN1_Status "CAN";
BA_ "CANzero_SDO_AccessType" SG_ 1482 HVCU_OD_CAN1_Status 1;
BA_ "CANzero_SDO_AccessIfOperational" SG_ 1482 HVCU_OD_CAN1_Status 1;
BA_ "CANzero_SDO_Group" SG_ 1482 HVCU_OD_CAN1_Baudrate "CAN";
BA_ "CANzero_SDO_AccessIfOperational" SG_ 1482 HVCU_OD_CAN1_Baudrate 1;
BA_ "GenSigStartValue" SG_ 1482 HVCU_OD_CAN1_Baudrate 1000.0;
BA_ "CANzero_SDO_Default" SG_ 1482 HVCU_OD_CAN1_Baudrate 1000;
BA_ "CANzero_SDO_Group" SG_ 1482 HVCU_OD_CAN1_autoErrorReset "CAN";
BA_ "CANzero_SDO_AccessIfOperational" SG_ 1482 HVCU_OD_CAN1_autoErrorReset 1;
BA_ "GenSigStartValue" SG_ 1482 HVCU_OD_CAN1_autoErrorReset 1.0;
BA_ "CANzero_SDO_Default" SG_ 1482 HVCU_OD_CAN1_autoErrorReset 1;
BA_ "CANzero_SDO_Group" SG_ 1482 HVCU_OD_CAN1_lastErrorCode "CAN";
BA_ "CANzero_SDO_AccessType" SG_ 1482 HVCU_OD_CAN1_lastErrorCode 1;
BA_ "CANzero_SDO_AccessIfOperational" SG_ 1482 HVCU_OD_CAN1_lastErrorCode 1;
BA_ "CANzero_SDO_Group" SG_ 1482 HVCU_OD_CAN1_RxErrCnt "CAN";
BA_ "CANzero_SDO_AccessType" SG_ 1482 HVCU_OD_CAN1_RxErrCnt 1;
BA_ "CANzero_SDO_AccessIfOperational" SG_ 1482 HVCU_OD_CAN1_RxErrCnt 1;
BA_ "CANzero_SDO_Group" SG_ 1482 HVCU_OD_CAN1_TxErrCnt "CAN";
BA_ "CANzero_SDO_AccessType" SG_ 1482 HVCU_OD_CAN1_TxErrCnt 1;
BA_ "CANzero_SDO_AccessIfOperational" SG_ 1482 HVCU_OD_CAN1_TxErrCnt 1;
BA_ "CANzero_SDO_AccessType" SG_ 1482 HVCU_OD_BuildTime 1;
BA_ "CANzero_SDO_AccessIfOperational" SG_ 1482 HVCU_OD_BuildTime 1;
BA_ "CANzero_SDO_AccessType" SG_ 1482 HVCU_OD_BuildDate 1;
BA_ "CANzero_SDO_AccessIfOperational" SG_ 1482 HVCU_OD_BuildDate 1;
BA_ "CANzero_SDO_AccessType" SG_ 1482 HVCU_OD_ChipUID2 1;
BA_ "CANzero_SDO_AccessIfOperational" SG_ 1482 HVCU_OD_ChipUID2 1;
BA_ "CANzero_SDO_AccessType" SG_ 1482 HVCU_OD_ChipUID1 1;
BA_ "CANzero_SDO_AccessIfOperational" SG_ 1482 HVCU_OD_ChipUID1 1;
BA_ "CANzero_SDO_AccessType" SG_ 1482 HVCU_OD_SdcOut 1;
BA_ "CANzero_SDO_AccessIfOperational" SG_ 1482 HVCU_OD_SdcOut 1;
BA_ "CANzero_SDO_AccessType" SG_ 1482 HVCU_OD_SdcIn 1;
BA_ "CANzero_SDO_AccessIfOperational" SG_ 1482 HVCU_OD_SdcIn 1;
BA_ "CANzero_SDO_AccessType" SG_ 1482 HVCU_OD_runtime 1;
BA_ "CANzero_SDO_AccessIfOperational" SG_ 1482 HVCU_OD_runtime 1;
BA_ "CANzero_SDO_AccessType" SG_ 1482 HVCU_OD_InputVoltage 1;
BA_ "CANzero_SDO_AccessIfOperational" SG_ 1482 HVCU_OD_InputVoltage 1;
BA_ "CANzero_SDO_AccessType" SG_ 1482 HVCU_OD_BoardTemp 1;
BA_ "CANzero_SDO_AccessIfOperational" SG_ 1482 HVCU_OD_BoardTemp 1;
BA_ "GenSigStartValue" SG_ 1482 HVCU_OD_BoardTemp 3000.0;
BA_ "CANzero_SDO_AccessType" SG_ 1482 HVCU_OD_MemFree 1;
BA_ "CANzero_SDO_AccessIfOperational" SG_ 1482 HVCU_OD_MemFree 1;
BA_ "CANzero_SDO_AccessType" SG_ 1482 HVCU_OD_CpuUsage 1;
BA_ "CANzero_SDO_AccessIfOperational" SG_ 1482 HVCU_OD_CpuUsage 1;
BA_ "CANzero_SDO_AccessIfOperational" SG_ 1482 HVCU_OD_OdEntrySendInterval 1;
BA_ "GenSigStartValue" SG_ 1482 HVCU_OD_OdEntrySendInterval 10.0;
BA_ "CANzero_SDO_Default" SG_ 1482 HVCU_OD_OdEntrySendInterval 10;
BA_ "CANzero_SDO_AccessIfOperational" SG_ 1482 HVCU_OD_SendOdOnBootup 1;
BA_ "CANzero_SDO_AccessIfOperational" SG_ 1482 HVCU_OD_HeartbeatInterval 1;
BA_ "GenSigStartValue" SG_ 1482 HVCU_OD_HeartbeatInterval 250.0;
BA_ "CANzero_SDO_Default" SG_ 1482 HVCU_OD_HeartbeatInterval 250;
BA_ "CANzero_SDO_AccessType" SG_ 1482 HVCU_OD_DbcVersion 1;
BA_ "CANzero_SDO_AccessIfOperational" SG_ 1482 HVCU_OD_DbcVersion 1;
BA_ "CANzero_SDO_AccessType" SG_ 1482 HVCU_OD_StackVersion 1;
BA_ "CANzero_SDO_AccessIfOperational" SG_ 1482 HVCU_OD_StackVersion 1;
BA_ "CANzero_SDO_AccessType" SG_ 1482 HVCU_OD_ProtocolVersion 1;
BA_ "CANzero_SDO_AccessIfOperational" SG_ 1482 HVCU_OD_ProtocolVersion 1;
BA_ "GenSigStartValue" SG_ 1482 HVCU_OD_ProtocolVersion 1.0;
BA_ "CANzero_SDO_Default" SG_ 1482 HVCU_OD_ProtocolVersion 1;
BA_ "CANzero_SDO_AccessType" SG_ 1482 HVCU_OD_NodeStatus 1;
BA_ "CANzero_SDO_AccessIfOperational" SG_ 1482 HVCU_OD_NodeStatus 1;
BA_ "CANzero_SDO_AccessType" SG_ 1482 HVCU_OD_NodeID 1;
BA_ "CANzero_SDO_AccessIfOperational" SG_ 1482 HVCU_OD_NodeID 1;
BA_ "GenMsgSendType" BO_ 1456 0;
BA_ "GenMsgCycleTime" BO_ 1456 10;
BA_ "GenSigStartValue" SG_ 1299 SCIMO_MOT2_A3 100;
BA_ "GenSigStartValue" SG_ 1299 SCIMO_MOT2_A2 100;
BA_ "GenSigStartValue" SG_ 1299 SCIMO_MOT2_A1 100;
BA_ "GenMsgSendType" BO_ 1280 0;
BA_ "GenMsgCycleTime" BO_ 1280 10;
BA_ "GenMsgCycleTime" BO_ 1296 10;
BA_ "GenMsgSendType" BO_ 1296 0;
BA_ "SystemSignalLongSymbol" SG_ 2578777089 EMUS_ContactorControl_ContactorS "EMUS_ContactorControl_ContactorState";
BA_ "CANzero_SDO_Group" SG_ 1433 HVTU_OD_CAN2_DelayedTxMessages "CAN";
BA_ "CANzero_SDO_AccessType" SG_ 1433 HVTU_OD_CAN2_DelayedTxMessages 1;
BA_ "CANzero_SDO_AccessIfOperational" SG_ 1433 HVTU_OD_CAN2_DelayedTxMessages 1;
BA_ "CANzero_SDO_Group" SG_ 1433 HVTU_OD_CAN2_ErrorStatus "CAN";
BA_ "CANzero_SDO_AccessType" SG_ 1433 HVTU_OD_CAN2_ErrorStatus 1;
BA_ "CANzero_SDO_AccessIfOperational" SG_ 1433 HVTU_OD_CAN2_ErrorStatus 1;
BA_ "CANzero_SDO_Group" SG_ 1433 HVTU_OD_CAN2_DiscardedTxMessages "CAN";
BA_ "CANzero_SDO_AccessType" SG_ 1433 HVTU_OD_CAN2_DiscardedTxMessages 1;
BA_ "CANzero_SDO_AccessIfOperational" SG_ 1433 HVTU_OD_CAN2_DiscardedTxMessages 1;
BA_ "CANzero_SDO_Group" SG_ 1433 HVTU_OD_CAN2_Status "CAN";
BA_ "CANzero_SDO_AccessType" SG_ 1433 HVTU_OD_CAN2_Status 1;
BA_ "CANzero_SDO_AccessIfOperational" SG_ 1433 HVTU_OD_CAN2_Status 1;
BA_ "CANzero_SDO_Group" SG_ 1433 HVTU_OD_CAN2_Baudrate "CAN";
BA_ "CANzero_SDO_AccessIfOperational" SG_ 1433 HVTU_OD_CAN2_Baudrate 1;
BA_ "GenSigStartValue" SG_ 1433 HVTU_OD_CAN2_Baudrate 1000.0;
BA_ "CANzero_SDO_Default" SG_ 1433 HVTU_OD_CAN2_Baudrate 1000;
BA_ "CANzero_SDO_Group" SG_ 1433 HVTU_OD_CAN2_autoErrorReset "CAN";
BA_ "CANzero_SDO_AccessIfOperational" SG_ 1433 HVTU_OD_CAN2_autoErrorReset 1;
BA_ "GenSigStartValue" SG_ 1433 HVTU_OD_CAN2_autoErrorReset 1.0;
BA_ "CANzero_SDO_Default" SG_ 1433 HVTU_OD_CAN2_autoErrorReset 1;
BA_ "CANzero_SDO_Group" SG_ 1433 HVTU_OD_CAN2_lastErrorCode "CAN";
BA_ "CANzero_SDO_AccessType" SG_ 1433 HVTU_OD_CAN2_lastErrorCode 1;
BA_ "CANzero_SDO_AccessIfOperational" SG_ 1433 HVTU_OD_CAN2_lastErrorCode 1;
BA_ "CANzero_SDO_Group" SG_ 1433 HVTU_OD_CAN2_RxErrCnt "CAN";
BA_ "CANzero_SDO_AccessType" SG_ 1433 HVTU_OD_CAN2_RxErrCnt 1;
BA_ "CANzero_SDO_AccessIfOperational" SG_ 1433 HVTU_OD_CAN2_RxErrCnt 1;
BA_ "CANzero_SDO_Group" SG_ 1433 HVTU_OD_CAN2_TxErrCnt "CAN";
BA_ "CANzero_SDO_AccessType" SG_ 1433 HVTU_OD_CAN2_TxErrCnt 1;
BA_ "CANzero_SDO_AccessIfOperational" SG_ 1433 HVTU_OD_CAN2_TxErrCnt 1;
BA_ "CANzero_SDO_Group" SG_ 1433 HVTU_OD_CAN1_DelayedTxMessages "CAN";
BA_ "CANzero_SDO_AccessType" SG_ 1433 HVTU_OD_CAN1_DelayedTxMessages 1;
BA_ "CANzero_SDO_AccessIfOperational" SG_ 1433 HVTU_OD_CAN1_DelayedTxMessages 1;
BA_ "CANzero_SDO_Group" SG_ 1433 HVTU_OD_CAN1_ErrorStatus "CAN";
BA_ "CANzero_SDO_AccessType" SG_ 1433 HVTU_OD_CAN1_ErrorStatus 1;
BA_ "CANzero_SDO_AccessIfOperational" SG_ 1433 HVTU_OD_CAN1_ErrorStatus 1;
BA_ "CANzero_SDO_Group" SG_ 1433 HVTU_OD_CAN1_DiscardedTxMessages "CAN";
BA_ "CANzero_SDO_AccessType" SG_ 1433 HVTU_OD_CAN1_DiscardedTxMessages 1;
BA_ "CANzero_SDO_AccessIfOperational" SG_ 1433 HVTU_OD_CAN1_DiscardedTxMessages 1;
BA_ "CANzero_SDO_Group" SG_ 1433 HVTU_OD_CAN1_Status "CAN";
BA_ "CANzero_SDO_AccessType" SG_ 1433 HVTU_OD_CAN1_Status 1;
BA_ "CANzero_SDO_AccessIfOperational" SG_ 1433 HVTU_OD_CAN1_Status 1;
BA_ "CANzero_SDO_Group" SG_ 1433 HVTU_OD_CAN1_Baudrate "CAN";
BA_ "CANzero_SDO_AccessIfOperational" SG_ 1433 HVTU_OD_CAN1_Baudrate 1;
BA_ "GenSigStartValue" SG_ 1433 HVTU_OD_CAN1_Baudrate 1000.0;
BA_ "CANzero_SDO_Default" SG_ 1433 HVTU_OD_CAN1_Baudrate 1000;
BA_ "CANzero_SDO_Group" SG_ 1433 HVTU_OD_CAN1_autoErrorReset "CAN";
BA_ "CANzero_SDO_AccessIfOperational" SG_ 1433 HVTU_OD_CAN1_autoErrorReset 1;
BA_ "GenSigStartValue" SG_ 1433 HVTU_OD_CAN1_autoErrorReset 1.0;
BA_ "CANzero_SDO_Default" SG_ 1433 HVTU_OD_CAN1_autoErrorReset 1;
BA_ "CANzero_SDO_Group" SG_ 1433 HVTU_OD_CAN1_lastErrorCode "CAN";
BA_ "CANzero_SDO_AccessType" SG_ 1433 HVTU_OD_CAN1_lastErrorCode 1;
BA_ "CANzero_SDO_AccessIfOperational" SG_ 1433 HVTU_OD_CAN1_lastErrorCode 1;
BA_ "CANzero_SDO_Group" SG_ 1433 HVTU_OD_CAN1_RxErrCnt "CAN";
BA_ "CANzero_SDO_AccessType" SG_ 1433 HVTU_OD_CAN1_RxErrCnt 1;
BA_ "CANzero_SDO_AccessIfOperational" SG_ 1433 HVTU_OD_CAN1_RxErrCnt 1;
BA_ "CANzero_SDO_Group" SG_ 1433 HVTU_OD_CAN1_TxErrCnt "CAN";
BA_ "CANzero_SDO_AccessType" SG_ 1433 HVTU_OD_CAN1_TxErrCnt 1;
BA_ "CANzero_SDO_AccessIfOperational" SG_ 1433 HVTU_OD_CAN1_TxErrCnt 1;
BA_ "CANzero_SDO_AccessType" SG_ 1433 HVTU_OD_BuildTime 1;
BA_ "CANzero_SDO_AccessIfOperational" SG_ 1433 HVTU_OD_BuildTime 1;
BA_ "CANzero_SDO_AccessType" SG_ 1433 HVTU_OD_BuildDate 1;
BA_ "CANzero_SDO_AccessIfOperational" SG_ 1433 HVTU_OD_BuildDate 1;
BA_ "CANzero_SDO_AccessType" SG_ 1433 HVTU_OD_ChipUID2 1;
BA_ "CANzero_SDO_AccessIfOperational" SG_ 1433 HVTU_OD_ChipUID2 1;
BA_ "CANzero_SDO_AccessType" SG_ 1433 HVTU_OD_ChipUID1 1;
BA_ "CANzero_SDO_AccessIfOperational" SG_ 1433 HVTU_OD_ChipUID1 1;
BA_ "CANzero_SDO_AccessType" SG_ 1433 HVTU_OD_SdcOut 1;
BA_ "CANzero_SDO_AccessIfOperational" SG_ 1433 HVTU_OD_SdcOut 1;
BA_ "CANzero_SDO_AccessType" SG_ 1433 HVTU_OD_SdcIn 1;
BA_ "CANzero_SDO_AccessIfOperational" SG_ 1433 HVTU_OD_SdcIn 1;
BA_ "CANzero_SDO_AccessType" SG_ 1433 HVTU_OD_runtime 1;
BA_ "CANzero_SDO_AccessIfOperational" SG_ 1433 HVTU_OD_runtime 1;
BA_ "CANzero_SDO_AccessType" SG_ 1433 HVTU_OD_InputVoltage 1;
BA_ "CANzero_SDO_AccessIfOperational" SG_ 1433 HVTU_OD_InputVoltage 1;
BA_ "CANzero_SDO_AccessType" SG_ 1433 HVTU_OD_BoardTemp 1;
BA_ "CANzero_SDO_AccessIfOperational" SG_ 1433 HVTU_OD_BoardTemp 1;
BA_ "GenSigStartValue" SG_ 1433 HVTU_OD_BoardTemp 3000.0;
BA_ "CANzero_SDO_AccessType" SG_ 1433 HVTU_OD_MemFree 1;
BA_ "CANzero_SDO_AccessIfOperational" SG_ 1433 HVTU_OD_MemFree 1;
BA_ "CANzero_SDO_AccessType" SG_ 1433 HVTU_OD_CpuUsage 1;
BA_ "CANzero_SDO_AccessIfOperational" SG_ 1433 HVTU_OD_CpuUsage 1;
BA_ "CANzero_SDO_AccessIfOperational" SG_ 1433 HVTU_OD_OdEntrySendInterval 1;
BA_ "GenSigStartValue" SG_ 1433 HVTU_OD_OdEntrySendInterval 50.0;
BA_ "CANzero_SDO_Default" SG_ 1433 HVTU_OD_OdEntrySendInterval 50;
BA_ "CANzero_SDO_AccessIfOperational" SG_ 1433 HVTU_OD_SendOdOnBootup 1;
BA_ "CANzero_SDO_AccessIfOperational" SG_ 1433 HVTU_OD_HeartbeatInterval 1;
BA_ "GenSigStartValue" SG_ 1433 HVTU_OD_HeartbeatInterval 250.0;
BA_ "CANzero_SDO_Default" SG_ 1433 HVTU_OD_HeartbeatInterval 250;
BA_ "CANzero_SDO_AccessType" SG_ 1433 HVTU_OD_DbcVersion 1;
BA_ "CANzero_SDO_AccessIfOperational" SG_ 1433 HVTU_OD_DbcVersion 1;
BA_ "CANzero_SDO_AccessType" SG_ 1433 HVTU_OD_StackVersion 1;
BA_ "CANzero_SDO_AccessIfOperational" SG_ 1433 HVTU_OD_StackVersion 1;
BA_ "CANzero_SDO_AccessType" SG_ 1433 HVTU_OD_ProtocolVersion 1;
BA_ "CANzero_SDO_AccessIfOperational" SG_ 1433 HVTU_OD_ProtocolVersion 1;
BA_ "GenSigStartValue" SG_ 1433 HVTU_OD_ProtocolVersion 1.0;
BA_ "CANzero_SDO_Default" SG_ 1433 HVTU_OD_ProtocolVersion 1;
BA_ "CANzero_SDO_AccessType" SG_ 1433 HVTU_OD_NodeStatus 1;
BA_ "CANzero_SDO_AccessIfOperational" SG_ 1433 HVTU_OD_NodeStatus 1;
BA_ "CANzero_SDO_AccessType" SG_ 1433 HVTU_OD_NodeID 1;
BA_ "CANzero_SDO_AccessIfOperational" SG_ 1433 HVTU_OD_NodeID 1;
BA_ "CANzero_SDO_Group" SG_ 1497 HVTU_OD_CAN2_DelayedTxMessages "CAN";
BA_ "CANzero_SDO_AccessType" SG_ 1497 HVTU_OD_CAN2_DelayedTxMessages 1;
BA_ "CANzero_SDO_AccessIfOperational" SG_ 1497 HVTU_OD_CAN2_DelayedTxMessages 1;
BA_ "CANzero_SDO_Group" SG_ 1497 HVTU_OD_CAN2_ErrorStatus "CAN";
BA_ "CANzero_SDO_AccessType" SG_ 1497 HVTU_OD_CAN2_ErrorStatus 1;
BA_ "CANzero_SDO_AccessIfOperational" SG_ 1497 HVTU_OD_CAN2_ErrorStatus 1;
BA_ "CANzero_SDO_Group" SG_ 1497 HVTU_OD_CAN2_DiscardedTxMessages "CAN";
BA_ "CANzero_SDO_AccessType" SG_ 1497 HVTU_OD_CAN2_DiscardedTxMessages 1;
BA_ "CANzero_SDO_AccessIfOperational" SG_ 1497 HVTU_OD_CAN2_DiscardedTxMessages 1;
BA_ "CANzero_SDO_Group" SG_ 1497 HVTU_OD_CAN2_Status "CAN";
BA_ "CANzero_SDO_AccessType" SG_ 1497 HVTU_OD_CAN2_Status 1;
BA_ "CANzero_SDO_AccessIfOperational" SG_ 1497 HVTU_OD_CAN2_Status 1;
BA_ "CANzero_SDO_Group" SG_ 1497 HVTU_OD_CAN2_Baudrate "CAN";
BA_ "CANzero_SDO_AccessIfOperational" SG_ 1497 HVTU_OD_CAN2_Baudrate 1;
BA_ "GenSigStartValue" SG_ 1497 HVTU_OD_CAN2_Baudrate 1000.0;
BA_ "CANzero_SDO_Default" SG_ 1497 HVTU_OD_CAN2_Baudrate 1000;
BA_ "CANzero_SDO_Group" SG_ 1497 HVTU_OD_CAN2_autoErrorReset "CAN";
BA_ "CANzero_SDO_AccessIfOperational" SG_ 1497 HVTU_OD_CAN2_autoErrorReset 1;
BA_ "GenSigStartValue" SG_ 1497 HVTU_OD_CAN2_autoErrorReset 1.0;
BA_ "CANzero_SDO_Default" SG_ 1497 HVTU_OD_CAN2_autoErrorReset 1;
BA_ "CANzero_SDO_Group" SG_ 1497 HVTU_OD_CAN2_lastErrorCode "CAN";
BA_ "CANzero_SDO_AccessType" SG_ 1497 HVTU_OD_CAN2_lastErrorCode 1;
BA_ "CANzero_SDO_AccessIfOperational" SG_ 1497 HVTU_OD_CAN2_lastErrorCode 1;
BA_ "CANzero_SDO_Group" SG_ 1497 HVTU_OD_CAN2_RxErrCnt "CAN";
BA_ "CANzero_SDO_AccessType" SG_ 1497 HVTU_OD_CAN2_RxErrCnt 1;
BA_ "CANzero_SDO_AccessIfOperational" SG_ 1497 HVTU_OD_CAN2_RxErrCnt 1;
BA_ "CANzero_SDO_Group" SG_ 1497 HVTU_OD_CAN2_TxErrCnt "CAN";
BA_ "CANzero_SDO_AccessType" SG_ 1497 HVTU_OD_CAN2_TxErrCnt 1;
BA_ "CANzero_SDO_AccessIfOperational" SG_ 1497 HVTU_OD_CAN2_TxErrCnt 1;
BA_ "CANzero_SDO_Group" SG_ 1497 HVTU_OD_CAN1_DelayedTxMessages "CAN";
BA_ "CANzero_SDO_AccessType" SG_ 1497 HVTU_OD_CAN1_DelayedTxMessages 1;
BA_ "CANzero_SDO_AccessIfOperational" SG_ 1497 HVTU_OD_CAN1_DelayedTxMessages 1;
BA_ "CANzero_SDO_Group" SG_ 1497 HVTU_OD_CAN1_ErrorStatus "CAN";
BA_ "CANzero_SDO_AccessType" SG_ 1497 HVTU_OD_CAN1_ErrorStatus 1;
BA_ "CANzero_SDO_AccessIfOperational" SG_ 1497 HVTU_OD_CAN1_ErrorStatus 1;
BA_ "CANzero_SDO_Group" SG_ 1497 HVTU_OD_CAN1_DiscardedTxMessages "CAN";
BA_ "CANzero_SDO_AccessType" SG_ 1497 HVTU_OD_CAN1_DiscardedTxMessages 1;
BA_ "CANzero_SDO_AccessIfOperational" SG_ 1497 HVTU_OD_CAN1_DiscardedTxMessages 1;
BA_ "CANzero_SDO_Group" SG_ 1497 HVTU_OD_CAN1_Status "CAN";
BA_ "CANzero_SDO_AccessType" SG_ 1497 HVTU_OD_CAN1_Status 1;
BA_ "CANzero_SDO_AccessIfOperational" SG_ 1497 HVTU_OD_CAN1_Status 1;
BA_ "CANzero_SDO_Group" SG_ 1497 HVTU_OD_CAN1_Baudrate "CAN";
BA_ "CANzero_SDO_AccessIfOperational" SG_ 1497 HVTU_OD_CAN1_Baudrate 1;
BA_ "GenSigStartValue" SG_ 1497 HVTU_OD_CAN1_Baudrate 1000.0;
BA_ "CANzero_SDO_Default" SG_ 1497 HVTU_OD_CAN1_Baudrate 1000;
BA_ "CANzero_SDO_Group" SG_ 1497 HVTU_OD_CAN1_autoErrorReset "CAN";
BA_ "CANzero_SDO_AccessIfOperational" SG_ 1497 HVTU_OD_CAN1_autoErrorReset 1;
BA_ "GenSigStartValue" SG_ 1497 HVTU_OD_CAN1_autoErrorReset 1.0;
BA_ "CANzero_SDO_Default" SG_ 1497 HVTU_OD_CAN1_autoErrorReset 1;
BA_ "CANzero_SDO_Group" SG_ 1497 HVTU_OD_CAN1_lastErrorCode "CAN";
BA_ "CANzero_SDO_AccessType" SG_ 1497 HVTU_OD_CAN1_lastErrorCode 1;
BA_ "CANzero_SDO_AccessIfOperational" SG_ 1497 HVTU_OD_CAN1_lastErrorCode 1;
BA_ "CANzero_SDO_Group" SG_ 1497 HVTU_OD_CAN1_RxErrCnt "CAN";
BA_ "CANzero_SDO_AccessType" SG_ 1497 HVTU_OD_CAN1_RxErrCnt 1;
BA_ "CANzero_SDO_AccessIfOperational" SG_ 1497 HVTU_OD_CAN1_RxErrCnt 1;
BA_ "CANzero_SDO_Group" SG_ 1497 HVTU_OD_CAN1_TxErrCnt "CAN";
BA_ "CANzero_SDO_AccessType" SG_ 1497 HVTU_OD_CAN1_TxErrCnt 1;
BA_ "CANzero_SDO_AccessIfOperational" SG_ 1497 HVTU_OD_CAN1_TxErrCnt 1;
BA_ "CANzero_SDO_AccessType" SG_ 1497 HVTU_OD_BuildTime 1;
BA_ "CANzero_SDO_AccessIfOperational" SG_ 1497 HVTU_OD_BuildTime 1;
BA_ "CANzero_SDO_AccessType" SG_ 1497 HVTU_OD_BuildDate 1;
BA_ "CANzero_SDO_AccessIfOperational" SG_ 1497 HVTU_OD_BuildDate 1;
BA_ "CANzero_SDO_AccessType" SG_ 1497 HVTU_OD_ChipUID2 1;
BA_ "CANzero_SDO_AccessIfOperational" SG_ 1497 HVTU_OD_ChipUID2 1;
BA_ "CANzero_SDO_AccessType" SG_ 1497 HVTU_OD_ChipUID1 1;
BA_ "CANzero_SDO_AccessIfOperational" SG_ 1497 HVTU_OD_ChipUID1 1;
BA_ "CANzero_SDO_AccessType" SG_ 1497 HVTU_OD_SdcOut 1;
BA_ "CANzero_SDO_AccessIfOperational" SG_ 1497 HVTU_OD_SdcOut 1;
BA_ "CANzero_SDO_AccessType" SG_ 1497 HVTU_OD_SdcIn 1;
BA_ "CANzero_SDO_AccessIfOperational" SG_ 1497 HVTU_OD_SdcIn 1;
BA_ "CANzero_SDO_AccessType" SG_ 1497 HVTU_OD_runtime 1;
BA_ "CANzero_SDO_AccessIfOperational" SG_ 1497 HVTU_OD_runtime 1;
BA_ "CANzero_SDO_AccessType" SG_ 1497 HVTU_OD_InputVoltage 1;
BA_ "CANzero_SDO_AccessIfOperational" SG_ 1497 HVTU_OD_InputVoltage 1;
BA_ "CANzero_SDO_AccessType" SG_ 1497 HVTU_OD_BoardTemp 1;
BA_ "CANzero_SDO_AccessIfOperational" SG_ 1497 HVTU_OD_BoardTemp 1;
BA_ "GenSigStartValue" SG_ 1497 HVTU_OD_BoardTemp 3000.0;
BA_ "CANzero_SDO_AccessType" SG_ 1497 HVTU_OD_MemFree 1;
BA_ "CANzero_SDO_AccessIfOperational" SG_ 1497 HVTU_OD_MemFree 1;
BA_ "CANzero_SDO_AccessType" SG_ 1497 HVTU_OD_CpuUsage 1;
BA_ "CANzero_SDO_AccessIfOperational" SG_ 1497 HVTU_OD_CpuUsage 1;
BA_ "CANzero_SDO_AccessIfOperational" SG_ 1497 HVTU_OD_OdEntrySendInterval 1;
BA_ "GenSigStartValue" SG_ 1497 HVTU_OD_OdEntrySendInterval 50.0;
BA_ "CANzero_SDO_Default" SG_ 1497 HVTU_OD_OdEntrySendInterval 50;
BA_ "CANzero_SDO_AccessIfOperational" SG_ 1497 HVTU_OD_SendOdOnBootup 1;
BA_ "CANzero_SDO_AccessIfOperational" SG_ 1497 HVTU_OD_HeartbeatInterval 1;
BA_ "GenSigStartValue" SG_ 1497 HVTU_OD_HeartbeatInterval 250.0;
BA_ "CANzero_SDO_Default" SG_ 1497 HVTU_OD_HeartbeatInterval 250;
BA_ "CANzero_SDO_AccessType" SG_ 1497 HVTU_OD_DbcVersion 1;
BA_ "CANzero_SDO_AccessIfOperational" SG_ 1497 HVTU_OD_DbcVersion 1;
BA_ "CANzero_SDO_AccessType" SG_ 1497 HVTU_OD_StackVersion 1;
BA_ "CANzero_SDO_AccessIfOperational" SG_ 1497 HVTU_OD_StackVersion 1;
BA_ "CANzero_SDO_AccessType" SG_ 1497 HVTU_OD_ProtocolVersion 1;
BA_ "CANzero_SDO_AccessIfOperational" SG_ 1497 HVTU_OD_ProtocolVersion 1;
BA_ "GenSigStartValue" SG_ 1497 HVTU_OD_ProtocolVersion 1.0;
BA_ "CANzero_SDO_Default" SG_ 1497 HVTU_OD_ProtocolVersion 1;
BA_ "CANzero_SDO_AccessType" SG_ 1497 HVTU_OD_NodeStatus 1;
BA_ "CANzero_SDO_AccessIfOperational" SG_ 1497 HVTU_OD_NodeStatus 1;
BA_ "CANzero_SDO_AccessType" SG_ 1497 HVTU_OD_NodeID 1;
BA_ "CANzero_SDO_AccessIfOperational" SG_ 1497 HVTU_OD_NodeID 1;
BA_ "CANzero_SDO_AccessType" SG_ 1442 TelemetryNode_OD_CanRestart 2;
BA_ "CANzero_SDO_AccessIfOperational" SG_ 1442 TelemetryNode_OD_CanRestart 1;
BA_ "CANzero_SDO_AccessType" SG_ 1442 TelemetryNode_OD_Reboot 2;
BA_ "CANzero_SDO_AccessIfOperational" SG_ 1442 TelemetryNode_OD_Reboot 1;
BA_ "CANzero_SDO_AccessType" SG_ 1442 TelemetryNode_OD_Shutdown 2;
BA_ "CANzero_SDO_AccessIfOperational" SG_ 1442 TelemetryNode_OD_Shutdown 1;
BA_ "CANzero_SDO_Group" SG_ 1442 TelemetryNode_OD_CAN2_DelayedTxM "CAN";
BA_ "CANzero_SDO_AccessType" SG_ 1442 TelemetryNode_OD_CAN2_DelayedTxM 1;
BA_ "CANzero_SDO_AccessIfOperational" SG_ 1442 TelemetryNode_OD_CAN2_DelayedTxM 1;
BA_ "SystemSignalLongSymbol" SG_ 1442 TelemetryNode_OD_CAN2_DelayedTxM "TelemetryNode_OD_CAN2_DelayedTxMessages";
BA_ "CANzero_SDO_Group" SG_ 1442 TelemetryNode_OD_CAN2_ErrorStatu "CAN";
BA_ "CANzero_SDO_AccessType" SG_ 1442 TelemetryNode_OD_CAN2_ErrorStatu 1;
BA_ "CANzero_SDO_AccessIfOperational" SG_ 1442 TelemetryNode_OD_CAN2_ErrorStatu 1;
BA_ "SystemSignalLongSymbol" SG_ 1442 TelemetryNode_OD_CAN2_ErrorStatu "TelemetryNode_OD_CAN2_ErrorStatus";
BA_ "CANzero_SDO_Group" SG_ 1442 TelemetryNode_OD_CAN2_DiscardedT "CAN";
BA_ "CANzero_SDO_AccessType" SG_ 1442 TelemetryNode_OD_CAN2_DiscardedT 1;
BA_ "CANzero_SDO_AccessIfOperational" SG_ 1442 TelemetryNode_OD_CAN2_DiscardedT 1;
BA_ "SystemSignalLongSymbol" SG_ 1442 TelemetryNode_OD_CAN2_DiscardedT "TelemetryNode_OD_CAN2_DiscardedTxMessages";
BA_ "CANzero_SDO_Group" SG_ 1442 TelemetryNode_OD_CAN2_Status "CAN";
BA_ "CANzero_SDO_AccessType" SG_ 1442 TelemetryNode_OD_CAN2_Status 1;
BA_ "CANzero_SDO_AccessIfOperational" SG_ 1442 TelemetryNode_OD_CAN2_Status 1;
BA_ "CANzero_SDO_Group" SG_ 1442 TelemetryNode_OD_CAN2_Baudrate "CAN";
BA_ "CANzero_SDO_AccessIfOperational" SG_ 1442 TelemetryNode_OD_CAN2_Baudrate 1;
BA_ "GenSigStartValue" SG_ 1442 TelemetryNode_OD_CAN2_Baudrate 1000.0;
BA_ "CANzero_SDO_Default" SG_ 1442 TelemetryNode_OD_CAN2_Baudrate 1000;
BA_ "CANzero_SDO_Group" SG_ 1442 TelemetryNode_OD_CAN2_autoErrorR "CAN";
BA_ "CANzero_SDO_AccessIfOperational" SG_ 1442 TelemetryNode_OD_CAN2_autoErrorR 1;
BA_ "GenSigStartValue" SG_ 1442 TelemetryNode_OD_CAN2_autoErrorR 1.0;
BA_ "CANzero_SDO_Default" SG_ 1442 TelemetryNode_OD_CAN2_autoErrorR 1;
BA_ "SystemSignalLongSymbol" SG_ 1442 TelemetryNode_OD_CAN2_autoErrorR "TelemetryNode_OD_CAN2_autoErrorReset";
BA_ "CANzero_SDO_Group" SG_ 1442 TelemetryNode_OD_CAN2_lastErrorC "CAN";
BA_ "CANzero_SDO_AccessType" SG_ 1442 TelemetryNode_OD_CAN2_lastErrorC 1;
BA_ "CANzero_SDO_AccessIfOperational" SG_ 1442 TelemetryNode_OD_CAN2_lastErrorC 1;
BA_ "SystemSignalLongSymbol" SG_ 1442 TelemetryNode_OD_CAN2_lastErrorC "TelemetryNode_OD_CAN2_lastErrorCode";
BA_ "CANzero_SDO_Group" SG_ 1442 TelemetryNode_OD_CAN2_RxErrCnt "CAN";
BA_ "CANzero_SDO_AccessType" SG_ 1442 TelemetryNode_OD_CAN2_RxErrCnt 1;
BA_ "CANzero_SDO_AccessIfOperational" SG_ 1442 TelemetryNode_OD_CAN2_RxErrCnt 1;
BA_ "CANzero_SDO_Group" SG_ 1442 TelemetryNode_OD_CAN2_TxErrCnt "CAN";
BA_ "CANzero_SDO_AccessType" SG_ 1442 TelemetryNode_OD_CAN2_TxErrCnt 1;
BA_ "CANzero_SDO_AccessIfOperational" SG_ 1442 TelemetryNode_OD_CAN2_TxErrCnt 1;
BA_ "CANzero_SDO_Group" SG_ 1442 TelemetryNode_OD_CAN1_DelayedTxM "CAN";
BA_ "CANzero_SDO_AccessType" SG_ 1442 TelemetryNode_OD_CAN1_DelayedTxM 1;
BA_ "CANzero_SDO_AccessIfOperational" SG_ 1442 TelemetryNode_OD_CAN1_DelayedTxM 1;
BA_ "SystemSignalLongSymbol" SG_ 1442 TelemetryNode_OD_CAN1_DelayedTxM "TelemetryNode_OD_CAN1_DelayedTxMessages";
BA_ "CANzero_SDO_Group" SG_ 1442 TelemetryNode_OD_CAN1_ErrorStatu "CAN";
BA_ "CANzero_SDO_AccessType" SG_ 1442 TelemetryNode_OD_CAN1_ErrorStatu 1;
BA_ "CANzero_SDO_AccessIfOperational" SG_ 1442 TelemetryNode_OD_CAN1_ErrorStatu 1;
BA_ "SystemSignalLongSymbol" SG_ 1442 TelemetryNode_OD_CAN1_ErrorStatu "TelemetryNode_OD_CAN1_ErrorStatus";
BA_ "CANzero_SDO_Group" SG_ 1442 TelemetryNode_OD_CAN1_DiscardedT "CAN";
BA_ "CANzero_SDO_AccessType" SG_ 1442 TelemetryNode_OD_CAN1_DiscardedT 1;
BA_ "CANzero_SDO_AccessIfOperational" SG_ 1442 TelemetryNode_OD_CAN1_DiscardedT 1;
BA_ "SystemSignalLongSymbol" SG_ 1442 TelemetryNode_OD_CAN1_DiscardedT "TelemetryNode_OD_CAN1_DiscardedTxMessages";
BA_ "CANzero_SDO_Group" SG_ 1442 TelemetryNode_OD_CAN1_Status "CAN";
BA_ "CANzero_SDO_AccessType" SG_ 1442 TelemetryNode_OD_CAN1_Status 1;
BA_ "CANzero_SDO_AccessIfOperational" SG_ 1442 TelemetryNode_OD_CAN1_Status 1;
BA_ "CANzero_SDO_Group" SG_ 1442 TelemetryNode_OD_CAN1_Baudrate "CAN";
BA_ "CANzero_SDO_AccessIfOperational" SG_ 1442 TelemetryNode_OD_CAN1_Baudrate 1;
BA_ "GenSigStartValue" SG_ 1442 TelemetryNode_OD_CAN1_Baudrate 1000.0;
BA_ "CANzero_SDO_Default" SG_ 1442 TelemetryNode_OD_CAN1_Baudrate 1000;
BA_ "CANzero_SDO_Group" SG_ 1442 TelemetryNode_OD_CAN1_autoErrorR "CAN";
BA_ "CANzero_SDO_AccessIfOperational" SG_ 1442 TelemetryNode_OD_CAN1_autoErrorR 1;
BA_ "GenSigStartValue" SG_ 1442 TelemetryNode_OD_CAN1_autoErrorR 1.0;
BA_ "CANzero_SDO_Default" SG_ 1442 TelemetryNode_OD_CAN1_autoErrorR 1;
BA_ "SystemSignalLongSymbol" SG_ 1442 TelemetryNode_OD_CAN1_autoErrorR "TelemetryNode_OD_CAN1_autoErrorReset";
BA_ "CANzero_SDO_Group" SG_ 1442 TelemetryNode_OD_CAN1_lastErrorC "CAN";
BA_ "CANzero_SDO_AccessType" SG_ 1442 TelemetryNode_OD_CAN1_lastErrorC 1;
BA_ "CANzero_SDO_AccessIfOperational" SG_ 1442 TelemetryNode_OD_CAN1_lastErrorC 1;
BA_ "SystemSignalLongSymbol" SG_ 1442 TelemetryNode_OD_CAN1_lastErrorC "TelemetryNode_OD_CAN1_lastErrorCode";
BA_ "CANzero_SDO_Group" SG_ 1442 TelemetryNode_OD_CAN1_RxErrCnt "CAN";
BA_ "CANzero_SDO_AccessType" SG_ 1442 TelemetryNode_OD_CAN1_RxErrCnt 1;
BA_ "CANzero_SDO_AccessIfOperational" SG_ 1442 TelemetryNode_OD_CAN1_RxErrCnt 1;
BA_ "CANzero_SDO_Group" SG_ 1442 TelemetryNode_OD_CAN1_TxErrCnt "CAN";
BA_ "CANzero_SDO_AccessType" SG_ 1442 TelemetryNode_OD_CAN1_TxErrCnt 1;
BA_ "CANzero_SDO_AccessIfOperational" SG_ 1442 TelemetryNode_OD_CAN1_TxErrCnt 1;
BA_ "CANzero_SDO_AccessType" SG_ 1442 TelemetryNode_OD_BuildTime 1;
BA_ "CANzero_SDO_AccessIfOperational" SG_ 1442 TelemetryNode_OD_BuildTime 1;
BA_ "CANzero_SDO_AccessType" SG_ 1442 TelemetryNode_OD_BuildDate 1;
BA_ "CANzero_SDO_AccessIfOperational" SG_ 1442 TelemetryNode_OD_BuildDate 1;
BA_ "CANzero_SDO_AccessType" SG_ 1442 TelemetryNode_OD_ChipUID2 1;
BA_ "CANzero_SDO_AccessIfOperational" SG_ 1442 TelemetryNode_OD_ChipUID2 1;
BA_ "CANzero_SDO_AccessType" SG_ 1442 TelemetryNode_OD_ChipUID1 1;
BA_ "CANzero_SDO_AccessIfOperational" SG_ 1442 TelemetryNode_OD_ChipUID1 1;
BA_ "CANzero_SDO_AccessType" SG_ 1442 TelemetryNode_OD_SdcOut 1;
BA_ "CANzero_SDO_AccessIfOperational" SG_ 1442 TelemetryNode_OD_SdcOut 1;
BA_ "CANzero_SDO_AccessType" SG_ 1442 TelemetryNode_OD_SdcIn 1;
BA_ "CANzero_SDO_AccessIfOperational" SG_ 1442 TelemetryNode_OD_SdcIn 1;
BA_ "CANzero_SDO_AccessType" SG_ 1442 TelemetryNode_OD_runtime 1;
BA_ "CANzero_SDO_AccessIfOperational" SG_ 1442 TelemetryNode_OD_runtime 1;
BA_ "CANzero_SDO_AccessType" SG_ 1442 TelemetryNode_OD_InputVoltage 1;
BA_ "CANzero_SDO_AccessIfOperational" SG_ 1442 TelemetryNode_OD_InputVoltage 1;
BA_ "CANzero_SDO_AccessType" SG_ 1442 TelemetryNode_OD_BoardTemp 1;
BA_ "CANzero_SDO_AccessIfOperational" SG_ 1442 TelemetryNode_OD_BoardTemp 1;
BA_ "GenSigStartValue" SG_ 1442 TelemetryNode_OD_BoardTemp 3000.0;
BA_ "CANzero_SDO_AccessType" SG_ 1442 TelemetryNode_OD_MemFree 1;
BA_ "CANzero_SDO_AccessIfOperational" SG_ 1442 TelemetryNode_OD_MemFree 1;
BA_ "CANzero_SDO_AccessType" SG_ 1442 TelemetryNode_OD_CpuUsage 1;
BA_ "CANzero_SDO_AccessIfOperational" SG_ 1442 TelemetryNode_OD_CpuUsage 1;
BA_ "CANzero_SDO_AccessIfOperational" SG_ 1442 TelemetryNode_OD_OdEntrySendInte 1;
BA_ "GenSigStartValue" SG_ 1442 TelemetryNode_OD_OdEntrySendInte 50.0;
BA_ "CANzero_SDO_Default" SG_ 1442 TelemetryNode_OD_OdEntrySendInte 50;
BA_ "SystemSignalLongSymbol" SG_ 1442 TelemetryNode_OD_OdEntrySendInte "TelemetryNode_OD_OdEntrySendInterval";
BA_ "CANzero_SDO_AccessIfOperational" SG_ 1442 TelemetryNode_OD_SendOdOnBootup 1;
BA_ "CANzero_SDO_AccessIfOperational" SG_ 1442 TelemetryNode_OD_HeartbeatInterv 1;
BA_ "GenSigStartValue" SG_ 1442 TelemetryNode_OD_HeartbeatInterv 250.0;
BA_ "CANzero_SDO_Default" SG_ 1442 TelemetryNode_OD_HeartbeatInterv 250;
BA_ "SystemSignalLongSymbol" SG_ 1442 TelemetryNode_OD_HeartbeatInterv "TelemetryNode_OD_HeartbeatInterval";
BA_ "CANzero_SDO_AccessType" SG_ 1442 TelemetryNode_OD_DbcVersion 1;
BA_ "CANzero_SDO_AccessIfOperational" SG_ 1442 TelemetryNode_OD_DbcVersion 1;
BA_ "CANzero_SDO_AccessType" SG_ 1442 TelemetryNode_OD_StackVersion 1;
BA_ "CANzero_SDO_AccessIfOperational" SG_ 1442 TelemetryNode_OD_StackVersion 1;
BA_ "CANzero_SDO_AccessType" SG_ 1442 TelemetryNode_OD_ProtocolVersion 1;
BA_ "CANzero_SDO_AccessIfOperational" SG_ 1442 TelemetryNode_OD_ProtocolVersion 1;
BA_ "GenSigStartValue" SG_ 1442 TelemetryNode_OD_ProtocolVersion 1.0;
BA_ "CANzero_SDO_Default" SG_ 1442 TelemetryNode_OD_ProtocolVersion 1;
BA_ "CANzero_SDO_AccessType" SG_ 1442 TelemetryNode_OD_NodeStatus 1;
BA_ "CANzero_SDO_AccessIfOperational" SG_ 1442 TelemetryNode_OD_NodeStatus 1;
BA_ "CANzero_SDO_AccessType" SG_ 1442 TelemetryNode_OD_NodeID 1;
BA_ "CANzero_SDO_AccessIfOperational" SG_ 1442 TelemetryNode_OD_NodeID 1;
BA_ "CANzero_SDO_AccessType" SG_ 1506 TelemetryNode_OD_CanRestart 2;
BA_ "CANzero_SDO_AccessIfOperational" SG_ 1506 TelemetryNode_OD_CanRestart 1;
BA_ "CANzero_SDO_AccessType" SG_ 1506 TelemetryNode_OD_Reboot 2;
BA_ "CANzero_SDO_AccessIfOperational" SG_ 1506 TelemetryNode_OD_Reboot 1;
BA_ "CANzero_SDO_AccessType" SG_ 1506 TelemetryNode_OD_Shutdown 2;
BA_ "CANzero_SDO_AccessIfOperational" SG_ 1506 TelemetryNode_OD_Shutdown 1;
BA_ "CANzero_SDO_Group" SG_ 1506 TelemetryNode_OD_CAN2_Delay_0000 "CAN";
BA_ "CANzero_SDO_AccessType" SG_ 1506 TelemetryNode_OD_CAN2_Delay_0000 1;
BA_ "CANzero_SDO_AccessIfOperational" SG_ 1506 TelemetryNode_OD_CAN2_Delay_0000 1;
BA_ "SystemSignalLongSymbol" SG_ 1506 TelemetryNode_OD_CAN2_Delay_0000 "TelemetryNode_OD_CAN2_DelayedTxMessages";
BA_ "CANzero_SDO_Group" SG_ 1506 TelemetryNode_OD_CAN2_Error_0000 "CAN";
BA_ "CANzero_SDO_AccessType" SG_ 1506 TelemetryNode_OD_CAN2_Error_0000 1;
BA_ "CANzero_SDO_AccessIfOperational" SG_ 1506 TelemetryNode_OD_CAN2_Error_0000 1;
BA_ "SystemSignalLongSymbol" SG_ 1506 TelemetryNode_OD_CAN2_Error_0000 "TelemetryNode_OD_CAN2_ErrorStatus";
BA_ "CANzero_SDO_Group" SG_ 1506 TelemetryNode_OD_CAN2_Disca_0000 "CAN";
BA_ "CANzero_SDO_AccessType" SG_ 1506 TelemetryNode_OD_CAN2_Disca_0000 1;
BA_ "CANzero_SDO_AccessIfOperational" SG_ 1506 TelemetryNode_OD_CAN2_Disca_0000 1;
BA_ "SystemSignalLongSymbol" SG_ 1506 TelemetryNode_OD_CAN2_Disca_0000 "TelemetryNode_OD_CAN2_DiscardedTxMessages";
BA_ "CANzero_SDO_Group" SG_ 1506 TelemetryNode_OD_CAN2_Status "CAN";
BA_ "CANzero_SDO_AccessType" SG_ 1506 TelemetryNode_OD_CAN2_Status 1;
BA_ "CANzero_SDO_AccessIfOperational" SG_ 1506 TelemetryNode_OD_CAN2_Status 1;
BA_ "CANzero_SDO_Group" SG_ 1506 TelemetryNode_OD_CAN2_Baudrate "CAN";
BA_ "CANzero_SDO_AccessIfOperational" SG_ 1506 TelemetryNode_OD_CAN2_Baudrate 1;
BA_ "GenSigStartValue" SG_ 1506 TelemetryNode_OD_CAN2_Baudrate 1000.0;
BA_ "CANzero_SDO_Default" SG_ 1506 TelemetryNode_OD_CAN2_Baudrate 1000;
BA_ "CANzero_SDO_Group" SG_ 1506 TelemetryNode_OD_CAN2_autoE_0000 "CAN";
BA_ "CANzero_SDO_AccessIfOperational" SG_ 1506 TelemetryNode_OD_CAN2_autoE_0000 1;
BA_ "GenSigStartValue" SG_ 1506 TelemetryNode_OD_CAN2_autoE_0000 1.0;
BA_ "CANzero_SDO_Default" SG_ 1506 TelemetryNode_OD_CAN2_autoE_0000 1;
BA_ "SystemSignalLongSymbol" SG_ 1506 TelemetryNode_OD_CAN2_autoE_0000 "TelemetryNode_OD_CAN2_autoErrorReset";
BA_ "CANzero_SDO_Group" SG_ 1506 TelemetryNode_OD_CAN2_lastE_0000 "CAN";
BA_ "CANzero_SDO_AccessType" SG_ 1506 TelemetryNode_OD_CAN2_lastE_0000 1;
BA_ "CANzero_SDO_AccessIfOperational" SG_ 1506 TelemetryNode_OD_CAN2_lastE_0000 1;
BA_ "SystemSignalLongSymbol" SG_ 1506 TelemetryNode_OD_CAN2_lastE_0000 "TelemetryNode_OD_CAN2_lastErrorCode";
BA_ "CANzero_SDO_Group" SG_ 1506 TelemetryNode_OD_CAN2_RxErrCnt "CAN";
BA_ "CANzero_SDO_AccessType" SG_ 1506 TelemetryNode_OD_CAN2_RxErrCnt 1;
BA_ "CANzero_SDO_AccessIfOperational" SG_ 1506 TelemetryNode_OD_CAN2_RxErrCnt 1;
BA_ "CANzero_SDO_Group" SG_ 1506 TelemetryNode_OD_CAN2_TxErrCnt "CAN";
BA_ "CANzero_SDO_AccessType" SG_ 1506 TelemetryNode_OD_CAN2_TxErrCnt 1;
BA_ "CANzero_SDO_AccessIfOperational" SG_ 1506 TelemetryNode_OD_CAN2_TxErrCnt 1;
BA_ "CANzero_SDO_Group" SG_ 1506 TelemetryNode_OD_CAN1_Delay_0000 "CAN";
BA_ "CANzero_SDO_AccessType" SG_ 1506 TelemetryNode_OD_CAN1_Delay_0000 1;
BA_ "CANzero_SDO_AccessIfOperational" SG_ 1506 TelemetryNode_OD_CAN1_Delay_0000 1;
BA_ "SystemSignalLongSymbol" SG_ 1506 TelemetryNode_OD_CAN1_Delay_0000 "TelemetryNode_OD_CAN1_DelayedTxMessages";
BA_ "CANzero_SDO_Group" SG_ 1506 TelemetryNode_OD_CAN1_Error_0000 "CAN";
BA_ "CANzero_SDO_AccessType" SG_ 1506 TelemetryNode_OD_CAN1_Error_0000 1;
BA_ "CANzero_SDO_AccessIfOperational" SG_ 1506 TelemetryNode_OD_CAN1_Error_0000 1;
BA_ "SystemSignalLongSymbol" SG_ 1506 TelemetryNode_OD_CAN1_Error_0000 "TelemetryNode_OD_CAN1_ErrorStatus";
BA_ "CANzero_SDO_Group" SG_ 1506 TelemetryNode_OD_CAN1_Disca_0000 "CAN";
BA_ "CANzero_SDO_AccessType" SG_ 1506 TelemetryNode_OD_CAN1_Disca_0000 1;
BA_ "CANzero_SDO_AccessIfOperational" SG_ 1506 TelemetryNode_OD_CAN1_Disca_0000 1;
BA_ "SystemSignalLongSymbol" SG_ 1506 TelemetryNode_OD_CAN1_Disca_0000 "TelemetryNode_OD_CAN1_DiscardedTxMessages";
BA_ "CANzero_SDO_Group" SG_ 1506 TelemetryNode_OD_CAN1_Status "CAN";
BA_ "CANzero_SDO_AccessType" SG_ 1506 TelemetryNode_OD_CAN1_Status 1;
BA_ "CANzero_SDO_AccessIfOperational" SG_ 1506 TelemetryNode_OD_CAN1_Status 1;
BA_ "CANzero_SDO_Group" SG_ 1506 TelemetryNode_OD_CAN1_Baudrate "CAN";
BA_ "CANzero_SDO_AccessIfOperational" SG_ 1506 TelemetryNode_OD_CAN1_Baudrate 1;
BA_ "GenSigStartValue" SG_ 1506 TelemetryNode_OD_CAN1_Baudrate 1000.0;
BA_ "CANzero_SDO_Default" SG_ 1506 TelemetryNode_OD_CAN1_Baudrate 1000;
BA_ "CANzero_SDO_Group" SG_ 1506 TelemetryNode_OD_CAN1_autoE_0000 "CAN";
BA_ "CANzero_SDO_AccessIfOperational" SG_ 1506 TelemetryNode_OD_CAN1_autoE_0000 1;
BA_ "GenSigStartValue" SG_ 1506 TelemetryNode_OD_CAN1_autoE_0000 1.0;
BA_ "CANzero_SDO_Default" SG_ 1506 TelemetryNode_OD_CAN1_autoE_0000 1;
BA_ "SystemSignalLongSymbol" SG_ 1506 TelemetryNode_OD_CAN1_autoE_0000 "TelemetryNode_OD_CAN1_autoErrorReset";
BA_ "CANzero_SDO_Group" SG_ 1506 TelemetryNode_OD_CAN1_lastE_0000 "CAN";
BA_ "CANzero_SDO_AccessType" SG_ 1506 TelemetryNode_OD_CAN1_lastE_0000 1;
BA_ "CANzero_SDO_AccessIfOperational" SG_ 1506 TelemetryNode_OD_CAN1_lastE_0000 1;
BA_ "SystemSignalLongSymbol" SG_ 1506 TelemetryNode_OD_CAN1_lastE_0000 "TelemetryNode_OD_CAN1_lastErrorCode";
BA_ "CANzero_SDO_Group" SG_ 1506 TelemetryNode_OD_CAN1_RxErrCnt "CAN";
BA_ "CANzero_SDO_AccessType" SG_ 1506 TelemetryNode_OD_CAN1_RxErrCnt 1;
BA_ "CANzero_SDO_AccessIfOperational" SG_ 1506 TelemetryNode_OD_CAN1_RxErrCnt 1;
BA_ "CANzero_SDO_Group" SG_ 1506 TelemetryNode_OD_CAN1_TxErrCnt "CAN";
BA_ "CANzero_SDO_AccessType" SG_ 1506 TelemetryNode_OD_CAN1_TxErrCnt 1;
BA_ "CANzero_SDO_AccessIfOperational" SG_ 1506 TelemetryNode_OD_CAN1_TxErrCnt 1;
BA_ "CANzero_SDO_AccessType" SG_ 1506 TelemetryNode_OD_BuildTime 1;
BA_ "CANzero_SDO_AccessIfOperational" SG_ 1506 TelemetryNode_OD_BuildTime 1;
BA_ "CANzero_SDO_AccessType" SG_ 1506 TelemetryNode_OD_BuildDate 1;
BA_ "CANzero_SDO_AccessIfOperational" SG_ 1506 TelemetryNode_OD_BuildDate 1;
BA_ "CANzero_SDO_AccessType" SG_ 1506 TelemetryNode_OD_ChipUID2 1;
BA_ "CANzero_SDO_AccessIfOperational" SG_ 1506 TelemetryNode_OD_ChipUID2 1;
BA_ "CANzero_SDO_AccessType" SG_ 1506 TelemetryNode_OD_ChipUID1 1;
BA_ "CANzero_SDO_AccessIfOperational" SG_ 1506 TelemetryNode_OD_ChipUID1 1;
BA_ "CANzero_SDO_AccessType" SG_ 1506 TelemetryNode_OD_SdcOut 1;
BA_ "CANzero_SDO_AccessIfOperational" SG_ 1506 TelemetryNode_OD_SdcOut 1;
BA_ "CANzero_SDO_AccessType" SG_ 1506 TelemetryNode_OD_SdcIn 1;
BA_ "CANzero_SDO_AccessIfOperational" SG_ 1506 TelemetryNode_OD_SdcIn 1;
BA_ "CANzero_SDO_AccessType" SG_ 1506 TelemetryNode_OD_runtime 1;
BA_ "CANzero_SDO_AccessIfOperational" SG_ 1506 TelemetryNode_OD_runtime 1;
BA_ "CANzero_SDO_AccessType" SG_ 1506 TelemetryNode_OD_InputVoltage 1;
BA_ "CANzero_SDO_AccessIfOperational" SG_ 1506 TelemetryNode_OD_InputVoltage 1;
BA_ "CANzero_SDO_AccessType" SG_ 1506 TelemetryNode_OD_BoardTemp 1;
BA_ "CANzero_SDO_AccessIfOperational" SG_ 1506 TelemetryNode_OD_BoardTemp 1;
BA_ "GenSigStartValue" SG_ 1506 TelemetryNode_OD_BoardTemp 3000.0;
BA_ "CANzero_SDO_AccessType" SG_ 1506 TelemetryNode_OD_MemFree 1;
BA_ "CANzero_SDO_AccessIfOperational" SG_ 1506 TelemetryNode_OD_MemFree 1;
BA_ "CANzero_SDO_AccessType" SG_ 1506 TelemetryNode_OD_CpuUsage 1;
BA_ "CANzero_SDO_AccessIfOperational" SG_ 1506 TelemetryNode_OD_CpuUsage 1;
BA_ "CANzero_SDO_AccessIfOperational" SG_ 1506 TelemetryNode_OD_OdEntrySen_0000 1;
BA_ "GenSigStartValue" SG_ 1506 TelemetryNode_OD_OdEntrySen_0000 50.0;
BA_ "CANzero_SDO_Default" SG_ 1506 TelemetryNode_OD_OdEntrySen_0000 50;
BA_ "SystemSignalLongSymbol" SG_ 1506 TelemetryNode_OD_OdEntrySen_0000 "TelemetryNode_OD_OdEntrySendInterval";
BA_ "CANzero_SDO_AccessIfOperational" SG_ 1506 TelemetryNode_OD_SendOdOnBootup 1;
BA_ "CANzero_SDO_AccessIfOperational" SG_ 1506 TelemetryNode_OD_HeartbeatI_0000 1;
BA_ "GenSigStartValue" SG_ 1506 TelemetryNode_OD_HeartbeatI_0000 250.0;
BA_ "CANzero_SDO_Default" SG_ 1506 TelemetryNode_OD_HeartbeatI_0000 250;
BA_ "SystemSignalLongSymbol" SG_ 1506 TelemetryNode_OD_HeartbeatI_0000 "TelemetryNode_OD_HeartbeatInterval";
BA_ "CANzero_SDO_AccessType" SG_ 1506 TelemetryNode_OD_DbcVersion 1;
BA_ "CANzero_SDO_AccessIfOperational" SG_ 1506 TelemetryNode_OD_DbcVersion 1;
BA_ "CANzero_SDO_AccessType" SG_ 1506 TelemetryNode_OD_StackVersion 1;
BA_ "CANzero_SDO_AccessIfOperational" SG_ 1506 TelemetryNode_OD_StackVersion 1;
BA_ "CANzero_SDO_AccessType" SG_ 1506 TelemetryNode_OD_ProtocolVersion 1;
BA_ "CANzero_SDO_AccessIfOperational" SG_ 1506 TelemetryNode_OD_ProtocolVersion 1;
BA_ "GenSigStartValue" SG_ 1506 TelemetryNode_OD_ProtocolVersion 1.0;
BA_ "CANzero_SDO_Default" SG_ 1506 TelemetryNode_OD_ProtocolVersion 1;
BA_ "CANzero_SDO_AccessType" SG_ 1506 TelemetryNode_OD_NodeStatus 1;
BA_ "CANzero_SDO_AccessIfOperational" SG_ 1506 TelemetryNode_OD_NodeStatus 1;
BA_ "CANzero_SDO_AccessType" SG_ 1506 TelemetryNode_OD_NodeID 1;
BA_ "CANzero_SDO_AccessIfOperational" SG_ 1506 TelemetryNode_OD_NodeID 1;
VAL_ 1482 HVCU_OD_CAN2_ErrorStatus 0 "Ok" 1 "Warn" 2 "Error Passive" 3 "Bus Off" ;
VAL_ 1482 HVCU_OD_CAN2_Status 0 "Reset" 1 "Ready" 2 "Listening" 3 "Sleep_Pending" 4 "Sleep_Active" 5 "ERROR" ;
VAL_ 1482 HVCU_OD_CAN2_autoErrorReset 0 "Disabled" 1 "Enabled" ;
VAL_ 1482 HVCU_OD_CAN2_lastErrorCode 0 "No Error" 1 "Stuff Error" 2 "Form Error" 3 "Ack Error" 4 "Bit recessive Error" 5 "Bit dominant Error" 6 "CRC Error" ;
VAL_ 1482 HVCU_OD_CAN1_ErrorStatus 0 "Ok" 1 "Warn" 2 "Error Passive" 3 "Bus Off" ;
VAL_ 1482 HVCU_OD_CAN1_Status 0 "Reset" 1 "Ready" 2 "Listening" 3 "Sleep_Pending" 4 "Sleep_Active" 5 "ERROR" ;
VAL_ 1482 HVCU_OD_CAN1_autoErrorReset 0 "Disabled" 1 "Enabled" ;
VAL_ 1482 HVCU_OD_CAN1_lastErrorCode 0 "No Error" 1 "Stuff Error" 2 "Form Error" 3 "Ack Error" 4 "Bit recessive Error" 5 "Bit dominant Error" 6 "CRC Error" ;
VAL_ 1482 HVCU_OD_SendOdOnBootup 0 "Disabled" 1 "Enabled" ;
VAL_ 1482 HVCU_OD_NodeStatus 0 "Bootup" 4 "Stopped" 5 "Operational" 127 "Pre-Operational" 128 "Reset" ;
VAL_ 1482 HVCU_SDO_ID 0 "Reserved" 1 "NodeID" 2 "NodeStatus" 3 "ProtocolVersion" 4 "StackVersion" 5 "DbcVersion" 16 "HeartbeatInterval" 32 "SendOdOnBootup" 33 "OdEntrySendInterval" 1040 "CpuUsage" 1041 "MemFree" 1042 "BoardTemp" 1043 "InputVoltage" 1044 "runtime" 1045 "SdcIn" 1046 "SdcOut" 1056 "ChipUID1" 1057 "ChipUID2" 1072 "BuildDate" 1073 "BuildTime" 1104 "CAN1_TxErrCnt" 1105 "CAN1_RxErrCnt" 1106 "CAN1_lastErrorCode" 1107 "CAN1_autoErrorReset" 1108 "CAN1_Baudrate" 1110 "CAN1_Status" 1111 "CAN1_DiscardedTxMessages" 1112 "CAN1_ErrorStatus" 1113 "CAN1_DelayedTxMessages" 1120 "CAN2_TxErrCnt" 1121 "CAN2_RxErrCnt" 1122 "CAN2_lastErrorCode" 1123 "CAN2_autoErrorReset" 1124 "CAN2_Baudrate" 1126 "CAN2_Status" 1127 "CAN2_DiscardedTxMessages" 1128 "CAN2_ErrorStatus" 1129 "CAN2_DelayedTxMessages" ;
VAL_ 1546 HVCU_SDO_ID 0 "Reserved" 1 "NodeID" 2 "NodeStatus" 3 "ProtocolVersion" 4 "StackVersion" 5 "DbcVersion" 16 "HeartbeatInterval" 32 "SendOdOnBootup" 33 "OdEntrySendInterval" 1040 "CpuUsage" 1041 "MemFree" 1042 "BoardTemp" 1043 "InputVoltage" 1044 "runtime" 1045 "SdcIn" 1046 "SdcOut" 1056 "ChipUID1" 1057 "ChipUID2" 1072 "BuildDate" 1073 "BuildTime" 1104 "CAN1_TxErrCnt" 1105 "CAN1_RxErrCnt" 1106 "CAN1_lastErrorCode" 1107 "CAN1_autoErrorReset" 1108 "CAN1_Baudrate" 1110 "CAN1_Status" 1111 "CAN1_DiscardedTxMessages" 1112 "CAN1_ErrorStatus" 1113 "CAN1_DelayedTxMessages" 1120 "CAN2_TxErrCnt" 1121 "CAN2_RxErrCnt" 1122 "CAN2_lastErrorCode" 1123 "CAN2_autoErrorReset" 1124 "CAN2_Baudrate" 1126 "CAN2_Status" 1127 "CAN2_DiscardedTxMessages" 1128 "CAN2_ErrorStatus" 1129 "CAN2_DelayedTxMessages" ;
VAL_ 1802 HVCU_NodeState 0 "Bootup" 4 "Stopped" 5 "Operational" 127 "Pre-Operational" ;
VAL_ 153 HVTU_E0_OtherError 0 "Ok" 1 "ERR" ;
VAL_ 153 HVTU_W0_OtherWarning 0 "Ok" 1 "WARN" ;
VAL_ 1408 SCIMO_FSM_State_MOT2 7 "permanent fault" 6 "fault" 5 "active" 4 "system check" 3 "ready" 2 "disabled" 1 "initial fault" 0 "reset" ;
VAL_ 1392 SCIMO_FSM_State_MOT1 7 "permanent fault" 6 "fault" 5 "active" 4 "system check" 3 "ready" 2 "disabled" 1 "initial fault" 0 "reset" ;
VAL_ 1312 SCIMO_warnNum_MOT2 1002 "Version" 1001 "Parameter Version" 102 "Comm2" 60 "U_ZK zu gross" 53 "Kennfeld Grenze" 52 "Spannungsgrenze" 51 "Torque Change" 50 "Max Torque" 33 "Drehzahllimit" 32 "PowerMin" 31 "PowerMax" 30 "Genauigkeit" 20 "Comm1" 2 "Commutation succedded" 0 "kein Warning" 402 "Comm5" 401 "Comm5" 302 "Comm4" 301 "Comm4" 202 "Comm3" 201 "Comm3" 104 "Uebertemperatur" 101 "Comm2" 21 "Comm1" 19 "Comm1" 18 "Comm1" 17 "Comm1" 16 "Comm1" 15 "Comm1" 14 "Comm1" 13 "Comm1" 12 "Comm1" 11 "Comm1" 10 "Comm1" 1 "Comm" ;
VAL_ 1312 SCIMO_warnNum_MOT1 1002 "Version" 1001 "Parameter Version" 102 "Comm2" 60 "U_ZK zu gross" 53 "Kennfeld Grenze" 52 "Spannungsgrenze" 51 "Torque Change" 50 "Max Torque" 33 "Drehzahllimit" 32 "PowerMin" 31 "PowerMax" 30 "Genauigkeit" 20 "Comm1" 2 "Commutation succedded" 0 "kein Warning" 402 "Comm5" 401 "Comm5" 302 "Comm4" 301 "Comm4" 202 "Comm3" 201 "Comm3" 104 "Uebertemperatur" 101 "Comm2" 21 "Comm1" 19 "Comm1" 18 "Comm1" 17 "Comm1" 16 "Comm1" 15 "Comm1" 14 "Comm1" 13 "Comm1" 12 "Comm1" 11 "Comm1" 10 "Comm1" 1 "Comm" ;
VAL_ 1312 SCIMO_errNum_MOT2 101 "Phasenueberstrom 4 Sample" 7 "Version" 121 "Unterdrehzahl" 120 "Ueberdrehzahl" 110 "Encoderfehler" 104 "Uebertemperatur" 103 "Summenueberstrom" 102 "Phasenueberstrom" 26 "Watchdog" 24 "Motor Temp" 21 "U_ZK zu gross" 20 "U_ZK zu klein" 10 "Encoder Fehler" 9 "Pulslock Fehler" 6 "Commutation" 5 "PS error" 4 "PS watchdog" 3 "Versorgung" 2 "Interpoloator Fehler" 1 "Parameter Fehler" 0 "Kein Fehler aktiv" ;
VAL_ 1312 SCIMO_errNum_MOT1 101 "Phasenueberstrom 4 Sample" 7 "Version" 121 "Unterdrehzahl" 120 "Ueberdrehzahl" 110 "Encoderfehler" 104 "Uebertemperatur" 103 "Summenueberstrom" 102 "Phasenueberstrom" 26 "Watchdog" 24 "Motor Temp" 21 "U_ZK zu gross" 20 "U_ZK zu klein" 10 "Encoder Fehler" 9 "Pulslock Fehler" 6 "Commutation" 5 "PS error" 4 "PS watchdog" 3 "Versorgung" 2 "Interpoloator Fehler" 1 "Parameter Fehler" 0 "Kein Fehler aktiv" ;
VAL_ 2578776064 EMUS_OverallParams_ChargingStage 0 "OFF" 1 "ON" ;
VAL_ 2578776064 EMUS_OverallParams_DCDC_Control 0 "OFF" 1 "ON" ;
VAL_ 2578776064 EMUS_OverallParams_BatteryFan 0 "OFF" 1 "ON" ;
VAL_ 2578776064 EMUS_OverallParams_HeaterEnable 0 "OFF" 1 "ON" ;
VAL_ 2578776064 EMUS_OverallParams_ChargerEnable 0 "OFF" 1 "ON" ;
VAL_ 2578776064 EMUS_OverallParams_LeakageSensor 0 "OFF" 1 "ON" ;
VAL_ 2578776064 EMUS_OverallParams_FastCharge 0 "OFF" 1 "ON" ;
VAL_ 2578776064 EMUS_OverallParams_ChargerMains 0 "OFF" 1 "ON" ;
VAL_ 2578776064 EMUS_OverallParams_IgnitionKey 0 "OFF" 1 "ON" ;
VAL_ 2578777090 EMUS_LoginLevel 0 "Guest" 1 "User" 2 "Admin" ;
VAL_ 2578777092 EMUS_Statistics_DataType 0 "Statistics Value" 1 "Additional Value" 2 "Statistics Timestamp" ;
VAL_ 2578777092 EMUS_Statistics_Identifier 0 "Total Disharge" 1 "Total Charge" 2 "Total Discharge Energy" 3 "Total Charge Energy" 4 "Total Discharge Time" 5 "Total Charge Time" 6 "Total Distance" 7 "Master Clear Count" 8 "Max Discharge Current" 9 "Max Charge Current" 10 "Min Cell Voltage" 11 "Max Cell Voltage" 12 "Max Cell Voltage Difference" 13 "Min Pack Voltage" 14 "Max Pack Voltage" 15 "Min Cell Module Temperature" 16 "Max Cell Module Temperature" 17 "Max Cell Module Temperature Difference" 18 "BMS Starts Count" 19 "Under Voltage Protection Count" 20 "Over Voltage Protection Count" 21 "Discharge Over Current Protection Count" 22 "Charge Over Current Protection Count" 23 "Cell Module Over Heat Protection Count" 24 "Leakage Protection Count" 25 "No Cell Communication Protection Count" 26 "Low Voltage Power Reduction Count" 27 "High Current Power Reduction Count" 28 "High Cell Module Temp Power Reduction Count" 29 "Charger Connected Count" 30 "Charger Disconnected Count" 31 "Pre Heat Stage Count" 32 "Pre Charge Stage Count" 33 "Main Charge Stage Count" 34 "Balancing Stage Count" 35 "Charging Finished Count" 36 "Charging Error Count" 37 "Charging Retry Count" 38 "Trips Count" 39 "Charge Restarts Count" 40 "Cell Over Heat Protection Count" 41 "High Cell Temperature Power Reduction Count" 42 "Min Cell Temperature" 43 "Max Cell Temperature Count" 44 "Max Cell Temperature Difference" ;
VAL_ 2578777093 EMUS_Events_Data_MSB 0 "No event" 1 "BMS Started" 2 "Lost Communication To Cells" 3 "Established Communication To Cells" 4 "Cells Voltage Critically Low" 5 "Critical Low Voltage Recovered" 6 "Cells Voltage Critically High " 7 "Critical High Voltage Recovered" 8 "Discharge Current Critically High" 9 "Discharge Critically High Current Recovered" 10 "Charge Current Critically High" 11 "Charge Critically High Current Recovered" 12 "Cell Module Temperature Critically High" 13 "Critical High Cell Module Temperature Recovered" 14 "Leakage Detected" 15 "Leakage Recovered" 16 "Warning: Low Voltage - Reducing Power" 17 "Power Reduction Due To Low Voltage Recovered" 18 "Warning: High Current - Reducing Power" 19 "Power Reduction Due To High Current Recovered" 20 "Warning: High Cell Module Temperature - Reducing Power" 21 "Power Reduction Due To High Cell Module Temperature Recovered" 22 "Charger Connected" 23 "Charger Disconnected" 24 "Started Pre-Heating Stage" 25 "Started Pre-Charging Stage" 26 "Started Main-Charging Stage" 27 "Started Balancing Stage" 28 "Charging Finished" 29 "Charging Error Occured" 30 "Retrying Charging" 31 "Restarting Charging" 32 "Cell Temperature Critically High" 33 "Critically High Cell Temperature Recovered" 34 "Warning: High Cell Temperature - Reducing Power" 35 "Power Reduction Due To High Cell Temperature Recovered" ;
VAL_ 2578777093 EMUS_Events_DataType 0 "Event Info " 1 "Event timestamp" ;
VAL_ 1433 HVTU_OD_CAN2_ErrorStatus 0 "Ok" 1 "Warn" 2 "Error Passive" 3 "Bus Off" ;
VAL_ 1433 HVTU_OD_CAN2_Status 0 "Reset" 1 "Ready" 2 "Listening" 3 "Sleep_Pending" 4 "Sleep_Active" 5 "ERROR" ;
VAL_ 1433 HVTU_OD_CAN2_autoErrorReset 0 "Disabled" 1 "Enabled" ;
VAL_ 1433 HVTU_OD_CAN2_lastErrorCode 0 "No Error" 1 "Stuff Error" 2 "Form Error" 3 "Ack Error" 4 "Bit recessive Error" 5 "Bit dominant Error" 6 "CRC Error" ;
VAL_ 1433 HVTU_OD_CAN1_ErrorStatus 0 "Ok" 1 "Warn" 2 "Error Passive" 3 "Bus Off" ;
VAL_ 1433 HVTU_OD_CAN1_Status 0 "Reset" 1 "Ready" 2 "Listening" 3 "Sleep_Pending" 4 "Sleep_Active" 5 "ERROR" ;
VAL_ 1433 HVTU_OD_CAN1_autoErrorReset 0 "Disabled" 1 "Enabled" ;
VAL_ 1433 HVTU_OD_CAN1_lastErrorCode 0 "No Error" 1 "Stuff Error" 2 "Form Error" 3 "Ack Error" 4 "Bit recessive Error" 5 "Bit dominant Error" 6 "CRC Error" ;
VAL_ 1433 HVTU_OD_SendOdOnBootup 0 "Disabled" 1 "Enabled" ;
VAL_ 1433 HVTU_OD_NodeStatus 0 "Bootup" 4 "Stopped" 5 "Operational" 127 "Pre-Operational" 128 "Reset" ;
VAL_ 1433 HVTU_SDO_RespCode 5 "ERR: Out of range" 4 "ERR: No access in this state" 3 "ERR: Read only object" 2 "ERR: Write only object" 1 "ERR: Non existing object" 0 "OK" ;
VAL_ 1433 HVTU_SDO_ID 0 "Reserved" 1 "NodeID" 2 "NodeStatus" 3 "ProtocolVersion" 4 "StackVersion" 5 "DbcVersion" 16 "HeartbeatInterval" 32 "SendOdOnBootup" 33 "OdEntrySendInterval" 1040 "CpuUsage" 1041 "MemFree" 1042 "BoardTemp" 1043 "InputVoltage" 1044 "runtime" 1045 "SdcIn" 1046 "SdcOut" 1056 "ChipUID1" 1057 "ChipUID2" 1072 "BuildDate" 1073 "BuildTime" 1104 "CAN1_TxErrCnt" 1105 "CAN1_RxErrCnt" 1106 "CAN1_lastErrorCode" 1107 "CAN1_autoErrorReset" 1108 "CAN1_Baudrate" 1110 "CAN1_Status" 1111 "CAN1_DiscardedTxMessages" 1112 "CAN1_ErrorStatus" 1113 "CAN1_DelayedTxMessages" 1120 "CAN2_TxErrCnt" 1121 "CAN2_RxErrCnt" 1122 "CAN2_lastErrorCode" 1123 "CAN2_autoErrorReset" 1124 "CAN2_Baudrate" 1126 "CAN2_Status" 1127 "CAN2_DiscardedTxMessages" 1128 "CAN2_ErrorStatus" 1129 "CAN2_DelayedTxMessages" ;
VAL_ 1497 HVTU_OD_CAN2_ErrorStatus 0 "Ok" 1 "Warn" 2 "Error Passive" 3 "Bus Off" ;
VAL_ 1497 HVTU_OD_CAN2_Status 0 "Reset" 1 "Ready" 2 "Listening" 3 "Sleep_Pending" 4 "Sleep_Active" 5 "ERROR" ;
VAL_ 1497 HVTU_OD_CAN2_autoErrorReset 0 "Disabled" 1 "Enabled" ;
VAL_ 1497 HVTU_OD_CAN2_lastErrorCode 0 "No Error" 1 "Stuff Error" 2 "Form Error" 3 "Ack Error" 4 "Bit recessive Error" 5 "Bit dominant Error" 6 "CRC Error" ;
VAL_ 1497 HVTU_OD_CAN1_ErrorStatus 0 "Ok" 1 "Warn" 2 "Error Passive" 3 "Bus Off" ;
VAL_ 1497 HVTU_OD_CAN1_Status 0 "Reset" 1 "Ready" 2 "Listening" 3 "Sleep_Pending" 4 "Sleep_Active" 5 "ERROR" ;
VAL_ 1497 HVTU_OD_CAN1_autoErrorReset 0 "Disabled" 1 "Enabled" ;
VAL_ 1497 HVTU_OD_CAN1_lastErrorCode 0 "No Error" 1 "Stuff Error" 2 "Form Error" 3 "Ack Error" 4 "Bit recessive Error" 5 "Bit dominant Error" 6 "CRC Error" ;
VAL_ 1497 HVTU_OD_SendOdOnBootup 0 "Disabled" 1 "Enabled" ;
VAL_ 1497 HVTU_OD_NodeStatus 0 "Bootup" 4 "Stopped" 5 "Operational" 127 "Pre-Operational" 128 "Reset" ;
VAL_ 1497 HVTU_SDO_ID 0 "Reserved" 1 "NodeID" 2 "NodeStatus" 3 "ProtocolVersion" 4 "StackVersion" 5 "DbcVersion" 16 "HeartbeatInterval" 32 "SendOdOnBootup" 33 "OdEntrySendInterval" 1040 "CpuUsage" 1041 "MemFree" 1042 "BoardTemp" 1043 "InputVoltage" 1044 "runtime" 1045 "SdcIn" 1046 "SdcOut" 1056 "ChipUID1" 1057 "ChipUID2" 1072 "BuildDate" 1073 "BuildTime" 1104 "CAN1_TxErrCnt" 1105 "CAN1_RxErrCnt" 1106 "CAN1_lastErrorCode" 1107 "CAN1_autoErrorReset" 1108 "CAN1_Baudrate" 1110 "CAN1_Status" 1111 "CAN1_DiscardedTxMessages" 1112 "CAN1_ErrorStatus" 1113 "CAN1_DelayedTxMessages" 1120 "CAN2_TxErrCnt" 1121 "CAN2_RxErrCnt" 1122 "CAN2_lastErrorCode" 1123 "CAN2_autoErrorReset" 1124 "CAN2_Baudrate" 1126 "CAN2_Status" 1127 "CAN2_DiscardedTxMessages" 1128 "CAN2_ErrorStatus" 1129 "CAN2_DelayedTxMessages" ;
VAL_ 1561 HVTU_SDO_ID 0 "Reserved" 1 "NodeID" 2 "NodeStatus" 3 "ProtocolVersion" 4 "StackVersion" 5 "DbcVersion" 16 "HeartbeatInterval" 32 "SendOdOnBootup" 33 "OdEntrySendInterval" 1040 "CpuUsage" 1041 "MemFree" 1042 "BoardTemp" 1043 "InputVoltage" 1044 "runtime" 1045 "SdcIn" 1046 "SdcOut" 1056 "ChipUID1" 1057 "ChipUID2" 1072 "BuildDate" 1073 "BuildTime" 1104 "CAN1_TxErrCnt" 1105 "CAN1_RxErrCnt" 1106 "CAN1_lastErrorCode" 1107 "CAN1_autoErrorReset" 1108 "CAN1_Baudrate" 1110 "CAN1_Status" 1111 "CAN1_DiscardedTxMessages" 1112 "CAN1_ErrorStatus" 1113 "CAN1_DelayedTxMessages" 1120 "CAN2_TxErrCnt" 1121 "CAN2_RxErrCnt" 1122 "CAN2_lastErrorCode" 1123 "CAN2_autoErrorReset" 1124 "CAN2_Baudrate" 1126 "CAN2_Status" 1127 "CAN2_DiscardedTxMessages" 1128 "CAN2_ErrorStatus" 1129 "CAN2_DelayedTxMessages" ;
VAL_ 1817 HVTU_NodeState 0 "Bootup" 4 "Stopped" 5 "Operational" 127 "Pre-Operational" ;
VAL_ 162 TelemetryNode_E0_OtherError 0 "Ok" 1 "ERR" ;
VAL_ 162 TelemetryNode_W0_OtherWarning 0 "Ok" 1 "WARN" ;
VAL_ 482 TelemetryNode_RX_Shutdown 2 "Reboot" 1 "Shutdown" 0 "None" ;
VAL_ 1442 TelemetryNode_OD_CanRestart 0 "None" 1 "Restart CAN" ;
VAL_ 1442 TelemetryNode_OD_Reboot 0 "None" 1 "Reboot" ;
VAL_ 1442 TelemetryNode_OD_Shutdown 0 "None" 1 "Shutdown" ;
VAL_ 1442 TelemetryNode_OD_CAN2_ErrorStatu 0 "Ok" 1 "Warn" 2 "Error Passive" 3 "Bus Off" ;
VAL_ 1442 TelemetryNode_OD_CAN2_Status 0 "Reset" 1 "Ready" 2 "Listening" 3 "Sleep_Pending" 4 "Sleep_Active" 5 "ERROR" ;
VAL_ 1442 TelemetryNode_OD_CAN2_autoErrorR 0 "Disabled" 1 "Enabled" ;
VAL_ 1442 TelemetryNode_OD_CAN2_lastErrorC 0 "No Error" 1 "Stuff Error" 2 "Form Error" 3 "Ack Error" 4 "Bit recessive Error" 5 "Bit dominant Error" 6 "CRC Error" ;
VAL_ 1442 TelemetryNode_OD_CAN1_ErrorStatu 0 "Ok" 1 "Warn" 2 "Error Passive" 3 "Bus Off" ;
VAL_ 1442 TelemetryNode_OD_CAN1_Status 0 "Reset" 1 "Ready" 2 "Listening" 3 "Sleep_Pending" 4 "Sleep_Active" 5 "ERROR" ;
VAL_ 1442 TelemetryNode_OD_CAN1_autoErrorR 0 "Disabled" 1 "Enabled" ;
VAL_ 1442 TelemetryNode_OD_CAN1_lastErrorC 0 "No Error" 1 "Stuff Error" 2 "Form Error" 3 "Ack Error" 4 "Bit recessive Error" 5 "Bit dominant Error" 6 "CRC Error" ;
VAL_ 1442 TelemetryNode_OD_SendOdOnBootup 0 "Disabled" 1 "Enabled" ;
VAL_ 1442 TelemetryNode_OD_NodeStatus 0 "Bootup" 4 "Stopped" 5 "Operational" 127 "Pre-Operational" 128 "Reset" ;
VAL_ 1442 TelemetryNode_SDO_RespCode 5 "ERR: Out of range" 4 "ERR: No access in this state" 3 "ERR: Read only object" 2 "ERR: Write only object" 1 "ERR: Non existing object" 0 "OK" ;
VAL_ 1442 TelemetryNode_SDO_ID 0 "Reserved" 1 "NodeID" 2 "NodeStatus" 3 "ProtocolVersion" 4 "StackVersion" 5 "DbcVersion" 16 "HeartbeatInterval" 32 "SendOdOnBootup" 33 "OdEntrySendInterval" 1040 "CpuUsage" 1041 "MemFree" 1042 "BoardTemp" 1043 "InputVoltage" 1044 "runtime" 1045 "SdcIn" 1046 "SdcOut" 1056 "ChipUID1" 1057 "ChipUID2" 1072 "BuildDate" 1073 "BuildTime" 1104 "CAN1_TxErrCnt" 1105 "CAN1_RxErrCnt" 1106 "CAN1_lastErrorCode" 1107 "CAN1_autoErrorReset" 1108 "CAN1_Baudrate" 1110 "CAN1_Status" 1111 "CAN1_DiscardedTxMessages" 1112 "CAN1_ErrorStatus" 1113 "CAN1_DelayedTxMessages" 1120 "CAN2_TxErrCnt" 1121 "CAN2_RxErrCnt" 1122 "CAN2_lastErrorCode" 1123 "CAN2_autoErrorReset" 1124 "CAN2_Baudrate" 1126 "CAN2_Status" 1127 "CAN2_DiscardedTxMessages" 1128 "CAN2_ErrorStatus" 1129 "CAN2_DelayedTxMessages" 2048 "Shutdown" 2049 "Reboot" 2050 "CanRestart" ;
VAL_ 1506 TelemetryNode_OD_CanRestart 0 "None" 1 "Restart CAN" ;
VAL_ 1506 TelemetryNode_OD_Reboot 0 "None" 1 "Reboot" ;
VAL_ 1506 TelemetryNode_OD_Shutdown 0 "None" 1 "Shutdown" ;
VAL_ 1506 TelemetryNode_OD_CAN2_Error_0000 0 "Ok" 1 "Warn" 2 "Error Passive" 3 "Bus Off" ;
VAL_ 1506 TelemetryNode_OD_CAN2_Status 0 "Reset" 1 "Ready" 2 "Listening" 3 "Sleep_Pending" 4 "Sleep_Active" 5 "ERROR" ;
VAL_ 1506 TelemetryNode_OD_CAN2_autoE_0000 0 "Disabled" 1 "Enabled" ;
VAL_ 1506 TelemetryNode_OD_CAN2_lastE_0000 0 "No Error" 1 "Stuff Error" 2 "Form Error" 3 "Ack Error" 4 "Bit recessive Error" 5 "Bit dominant Error" 6 "CRC Error" ;
VAL_ 1506 TelemetryNode_OD_CAN1_Error_0000 0 "Ok" 1 "Warn" 2 "Error Passive" 3 "Bus Off" ;
VAL_ 1506 TelemetryNode_OD_CAN1_Status 0 "Reset" 1 "Ready" 2 "Listening" 3 "Sleep_Pending" 4 "Sleep_Active" 5 "ERROR" ;
VAL_ 1506 TelemetryNode_OD_CAN1_autoE_0000 0 "Disabled" 1 "Enabled" ;
VAL_ 1506 TelemetryNode_OD_CAN1_lastE_0000 0 "No Error" 1 "Stuff Error" 2 "Form Error" 3 "Ack Error" 4 "Bit recessive Error" 5 "Bit dominant Error" 6 "CRC Error" ;
VAL_ 1506 TelemetryNode_OD_SendOdOnBootup 0 "Disabled" 1 "Enabled" ;
VAL_ 1506 TelemetryNode_OD_NodeStatus 0 "Bootup" 4 "Stopped" 5 "Operational" 127 "Pre-Operational" 128 "Reset" ;
VAL_ 1506 TelemetryNode_SDO_ID 0 "Reserved" 1 "NodeID" 2 "NodeStatus" 3 "ProtocolVersion" 4 "StackVersion" 5 "DbcVersion" 16 "HeartbeatInterval" 32 "SendOdOnBootup" 33 "OdEntrySendInterval" 1040 "CpuUsage" 1041 "MemFree" 1042 "BoardTemp" 1043 "InputVoltage" 1044 "runtime" 1045 "SdcIn" 1046 "SdcOut" 1056 "ChipUID1" 1057 "ChipUID2" 1072 "BuildDate" 1073 "BuildTime" 1104 "CAN1_TxErrCnt" 1105 "CAN1_RxErrCnt" 1106 "CAN1_lastErrorCode" 1107 "CAN1_autoErrorReset" 1108 "CAN1_Baudrate" 1110 "CAN1_Status" 1111 "CAN1_DiscardedTxMessages" 1112 "CAN1_ErrorStatus" 1113 "CAN1_DelayedTxMessages" 1120 "CAN2_TxErrCnt" 1121 "CAN2_RxErrCnt" 1122 "CAN2_lastErrorCode" 1123 "CAN2_autoErrorReset" 1124 "CAN2_Baudrate" 1126 "CAN2_Status" 1127 "CAN2_DiscardedTxMessages" 1128 "CAN2_ErrorStatus" 1129 "CAN2_DelayedTxMessages" 2048 "Shutdown" 2049 "Reboot" 2050 "CanRestart" ;
VAL_ 1570 TelemetryNode_SDO_ID 0 "Reserved" 1 "NodeID" 2 "NodeStatus" 3 "ProtocolVersion" 4 "StackVersion" 5 "DbcVersion" 16 "HeartbeatInterval" 32 "SendOdOnBootup" 33 "OdEntrySendInterval" 1040 "CpuUsage" 1041 "MemFree" 1042 "BoardTemp" 1043 "InputVoltage" 1044 "runtime" 1045 "SdcIn" 1046 "SdcOut" 1056 "ChipUID1" 1057 "ChipUID2" 1072 "BuildDate" 1073 "BuildTime" 1104 "CAN1_TxErrCnt" 1105 "CAN1_RxErrCnt" 1106 "CAN1_lastErrorCode" 1107 "CAN1_autoErrorReset" 1108 "CAN1_Baudrate" 1110 "CAN1_Status" 1111 "CAN1_DiscardedTxMessages" 1112 "CAN1_ErrorStatus" 1113 "CAN1_DelayedTxMessages" 1120 "CAN2_TxErrCnt" 1121 "CAN2_RxErrCnt" 1122 "CAN2_lastErrorCode" 1123 "CAN2_autoErrorReset" 1124 "CAN2_Baudrate" 1126 "CAN2_Status" 1127 "CAN2_DiscardedTxMessages" 1128 "CAN2_ErrorStatus" 1129 "CAN2_DelayedTxMessages" 2048 "Shutdown" 2049 "Reboot" 2050 "CanRestart" ;
VAL_ 1826 TelemetryNode_NodeState 0 "Bootup" 4 "Stopped" 5 "Operational" 127 "Pre-Operational" ;
